[part 1 of 2: packages /VehicleProject to /E40_Platform_System_SystemPackage/Components]
AUTOSAR XML (schema 4-2-1)
standard types defined: uint8, uint16, UInt16, uint32, UInt32, sint32, boolean, Boolean, SInt32, UInt8, sint8, SInt8
package /VehicleProject
  ecu instance METER
package /E40_Platform_System_SystemPackage
  composition sw component type E40_Platform_System_SoftwareArchitecture
    component E40_Platform_SystemCmp: type=E40_Platform_System
  system E40_Platform_System_System
    system mapping MAPPING
      sw-impl-mappings:
        18 x swc to impl mapping:
          ImplementationMapping1: component-implementation=IMPL_CBacklightCdd, component=SoftwareArchitecture.E40_Platform_SystemCmp.CBacklightCdd
          ImplementationMapping2: component-implementation=IMPL_IoHwAb, component=SoftwareArchitecture.E40_Platform_SystemCmp.IoHwAb
          ImplementationMapping3: component-implementation=IMPL_CBattMdl, component=SoftwareArchitecture.E40_Platform_SystemCmp.CBattMdl
          ImplementationMapping4: component-implementation=IMPL_CCDD_EcuPowerM, component=SoftwareArchitecture.E40_Platform_SystemCmp.CCDD_EcuPowerM
          ImplementationMapping5: component-implementation=IMPL_CDisplayCdd, component=SoftwareArchitecture.E40_Platform_SystemCmp.CDisplayCdd
          ImplementationMapping6: component-implementation=IMPL_CMeetCdd, component=SoftwareArchitecture.E40_Platform_SystemCmp.CMeetCdd
          ImplementationMapping7: component-implementation=IMPL_MemAbstractMdl, component=SoftwareArchitecture.E40_Platform_SystemCmp.MemAbstractMdl
          ImplementationMapping8: component-implementation=IMPL_RtcCdd, component=SoftwareArchitecture.E40_Platform_SystemCmp.RtcCdd
          ImplementationMapping9: component-implementation=IMPL_CSleepManager, component=SoftwareArchitecture.E40_Platform_SystemCmp.CSleepManager
          ImplementationMapping10: component-implementation=IMPL_CSndCdd, component=SoftwareArchitecture.E40_Platform_SystemCmp.CSndCdd
          ImplementationMapping11: component-implementation=IMPL_DcmExt, component=SoftwareArchitecture.E40_Platform_SystemCmp.DcmExt
          ImplementationMapping12: component-implementation=IMPL_DemExt, component=SoftwareArchitecture.E40_Platform_SystemCmp.DemExt
          ImplementationMapping13: component-implementation=IMPL_DmnMgr, component=SoftwareArchitecture.E40_Platform_SystemCmp.DmnMgr
          ImplementationMapping14: component-implementation=IMPL_UclProxyCdd, component=SoftwareArchitecture.E40_Platform_SystemCmp.UclProxyCdd
          ImplementationMapping15: component-implementation=IMPL_EcuAppM, component=SoftwareArchitecture.E40_Platform_SystemCmp.EcuAppM
          ImplementationMapping16: component-implementation=IMPL_NvMExt, component=SoftwareArchitecture.E40_Platform_SystemCmp.NvMExt
          ImplementationMapping17: component-implementation=IMPL_EcuMExt, component=SoftwareArchitecture.E40_Platform_SystemCmp.EcuMExt
          ImplementationMapping18: component-implementation=IMPL_TmExt, component=SoftwareArchitecture.E40_Platform_SystemCmp.TmExt
      sw-mappings:
        swc to ecu mapping SwcToEcuMapping: ecu-instance=METER
    root-software-compositions:
      root sw composition prototype SoftwareArchitecture: software-composition=E40_Platform_System
package /E40_Platform_System_SystemPackage/Components
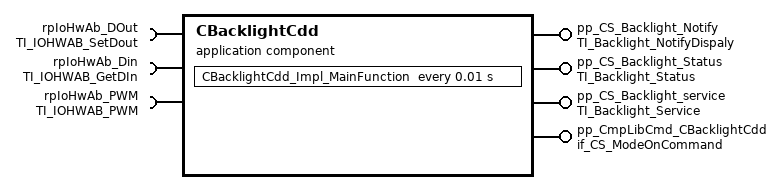
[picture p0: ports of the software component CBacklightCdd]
  application sw component type CBacklightCdd
    4 x provide port:
      pp_CS_Backlight_Notify: server-com-spec{operation=NotifyDisplayPowerState, queue-length=1}, provided-interface=TI_Backlight_NotifyDispaly
      pp_CS_Backlight_Status: server-com-spec{operation=TI_Backlight_Status/GetStatus, queue-length=1}, provided-interface=TI_Backlight_Status
      pp_CS_Backlight_service: provided-interface=TI_Backlight_Service
        provided-com-specs:
          operation=GetBrightnessValue, queue-length=1
          operation=GetThermalValue, queue-length=1
          operation=SetBrightnessValue, queue-length=1
      pp_CmpLibCmd_CBacklightCdd: server-com-spec{operation=Impl_OnCommand, queue-length=1}, provided-interface=if_CS_ModeOnCommand
    require port rpIoHwAb_DOut: required-interface=TI_IOHWAB_SetDout
    require port rpIoHwAb_Din: required-interface=TI_IOHWAB_GetDIn
    require port rpIoHwAb_PWM: required-interface=TI_IOHWAB_PWM
    behavior IB_CBacklightCdd
      operation invoked event OIE_pp_CS_Backlight_service_CBacklightCdd_GetBrightnessValueTrigByGetBrightnessValue: start-on-event=CBacklightCdd_GetBrightnessValue, operation=pp_CS_Backlight_service.GetBrightnessValue
      operation invoked event OIE_pp_CS_Backlight_Status_CBacklightCdd_GetStatusTrigByGetStatus: start-on-event=CBacklightCdd_GetStatus, operation=pp_CS_Backlight_Status.GetStatus
      operation invoked event OIE_pp_CS_Backlight_service_CBacklightCdd_GetThermalValueTrigByGetThermalValue: start-on-event=CBacklightCdd_GetThermalValue, operation=pp_CS_Backlight_service.GetThermalValue
      timing event TECBacklightCdd_Impl_MainFunction: start-on-event=CBacklightCdd_Impl_MainFunction, period=0.01
      operation invoked event OIE_pp_CmpLibCmd_CBacklightCdd_CBacklightCdd_Impl_OnCommandTrigByImpl_OnCommand: start-on-event=CBacklightCdd_Impl_OnCommand, operation=pp_CmpLibCmd_CBacklightCdd.Impl_OnCommand
      operation invoked event OIE_pp_CS_Backlight_Notify_CBacklightCdd_NotifyDisplayPowerStateTrigByNotifyDisplayPowerState: start-on-event=CBacklightCdd_NotifyDisplayPowerState, operation=pp_CS_Backlight_Notify.NotifyDisplayPowerState
      operation invoked event OIE_pp_CS_Backlight_service_CBacklightCdd_SetBrightnessValueTrigBySetBrightnessValue: start-on-event=CBacklightCdd_SetBrightnessValue, operation=pp_CS_Backlight_service.SetBrightnessValue
      port-api-options:
        enable-take-address=false, indirect-api=false, port=pp_CS_Backlight_Notify
        enable-take-address=false, indirect-api=false, port=pp_CS_Backlight_Status
        enable-take-address=false, indirect-api=false, port=pp_CS_Backlight_service
        enable-take-address=false, indirect-api=false, port=pp_CmpLibCmd_CBacklightCdd
        enable-take-address=false, indirect-api=false, port=CBacklightCdd/rpIoHwAb_DOut
        enable-take-address=false, indirect-api=false, port=CBacklightCdd/rpIoHwAb_Din
        enable-take-address=false, indirect-api=false, port=CBacklightCdd/rpIoHwAb_PWM
      7 x runnable, all with can-be-invoked-concurrently=true:
        CBacklightCdd_GetBrightnessValue
          9 x sync call, all with timeout=0.0:
            OA_rpIoHwAb_DOut_SetOutputGroup: operation=rpIoHwAb_DOut.SetOutputGroup
            OA_rpIoHwAb_DOut_SetOutputPin: operation=rpIoHwAb_DOut.SetOutputPin
            OA_rpIoHwAb_Din_GetAsyncRawInput: operation=rpIoHwAb_Din.GetAsyncRawInput
            OA_rpIoHwAb_Din_GetProcessedInput: operation=rpIoHwAb_Din.GetProcessedInput
            OA_rpIoHwAb_Din_GetSyncRawInput: operation=rpIoHwAb_Din.GetSyncRawInput
            OA_rpIoHwAb_Din_GetInputGroup: operation=rpIoHwAb_Din.GetInputGroup
            OA_rpIoHwAb_PWM_PwmSetDuty: operation=rpIoHwAb_PWM.PwmSetDuty
            OA_rpIoHwAb_PWM_PwmSetDutyAndPeriod: operation=rpIoHwAb_PWM.PwmSetDutyAndPeriod
            OA_rpIoHwAb_PWM_PwmSetIdeal: operation=rpIoHwAb_PWM.PwmSetIdeal
        CBacklightCdd_GetStatus
          9 x sync call, all with timeout=0.0:
            OA_rpIoHwAb_DOut_SetOutputGroup: operation=rpIoHwAb_DOut.SetOutputGroup
            OA_rpIoHwAb_DOut_SetOutputPin: operation=rpIoHwAb_DOut.SetOutputPin
            OA_rpIoHwAb_Din_GetAsyncRawInput: operation=rpIoHwAb_Din.GetAsyncRawInput
            OA_rpIoHwAb_Din_GetProcessedInput: operation=rpIoHwAb_Din.GetProcessedInput
            OA_rpIoHwAb_Din_GetSyncRawInput: operation=rpIoHwAb_Din.GetSyncRawInput
            OA_rpIoHwAb_Din_GetInputGroup: operation=rpIoHwAb_Din.GetInputGroup
            OA_rpIoHwAb_PWM_PwmSetDuty: operation=rpIoHwAb_PWM.PwmSetDuty
            OA_rpIoHwAb_PWM_PwmSetDutyAndPeriod: operation=rpIoHwAb_PWM.PwmSetDutyAndPeriod
            OA_rpIoHwAb_PWM_PwmSetIdeal: operation=rpIoHwAb_PWM.PwmSetIdeal
        CBacklightCdd_GetThermalValue
          9 x sync call, all with timeout=0.0:
            OA_rpIoHwAb_DOut_SetOutputGroup: operation=rpIoHwAb_DOut.SetOutputGroup
            OA_rpIoHwAb_DOut_SetOutputPin: operation=rpIoHwAb_DOut.SetOutputPin
            OA_rpIoHwAb_Din_GetAsyncRawInput: operation=rpIoHwAb_Din.GetAsyncRawInput
            OA_rpIoHwAb_Din_GetProcessedInput: operation=rpIoHwAb_Din.GetProcessedInput
            OA_rpIoHwAb_Din_GetSyncRawInput: operation=rpIoHwAb_Din.GetSyncRawInput
            OA_rpIoHwAb_Din_GetInputGroup: operation=rpIoHwAb_Din.GetInputGroup
            OA_rpIoHwAb_PWM_PwmSetDuty: operation=rpIoHwAb_PWM.PwmSetDuty
            OA_rpIoHwAb_PWM_PwmSetDutyAndPeriod: operation=rpIoHwAb_PWM.PwmSetDutyAndPeriod
            OA_rpIoHwAb_PWM_PwmSetIdeal: operation=rpIoHwAb_PWM.PwmSetIdeal
        CBacklightCdd_Impl_MainFunction
          9 x sync call, all with timeout=0.0:
            OA_rpIoHwAb_DOut_SetOutputGroup: operation=rpIoHwAb_DOut.SetOutputGroup
            OA_rpIoHwAb_DOut_SetOutputPin: operation=rpIoHwAb_DOut.SetOutputPin
            OA_rpIoHwAb_Din_GetAsyncRawInput: operation=rpIoHwAb_Din.GetAsyncRawInput
            OA_rpIoHwAb_Din_GetProcessedInput: operation=rpIoHwAb_Din.GetProcessedInput
            OA_rpIoHwAb_Din_GetSyncRawInput: operation=rpIoHwAb_Din.GetSyncRawInput
            OA_rpIoHwAb_Din_GetInputGroup: operation=rpIoHwAb_Din.GetInputGroup
            OA_rpIoHwAb_PWM_PwmSetDuty: operation=rpIoHwAb_PWM.PwmSetDuty
            OA_rpIoHwAb_PWM_PwmSetDutyAndPeriod: operation=rpIoHwAb_PWM.PwmSetDutyAndPeriod
            OA_rpIoHwAb_PWM_PwmSetIdeal: operation=rpIoHwAb_PWM.PwmSetIdeal
        CBacklightCdd_Impl_OnCommand
          9 x sync call, all with timeout=0.0:
            OA_rpIoHwAb_DOut_SetOutputGroup: operation=rpIoHwAb_DOut.SetOutputGroup
            OA_rpIoHwAb_DOut_SetOutputPin: operation=rpIoHwAb_DOut.SetOutputPin
            OA_rpIoHwAb_Din_GetAsyncRawInput: operation=rpIoHwAb_Din.GetAsyncRawInput
            OA_rpIoHwAb_Din_GetProcessedInput: operation=rpIoHwAb_Din.GetProcessedInput
            OA_rpIoHwAb_Din_GetSyncRawInput: operation=rpIoHwAb_Din.GetSyncRawInput
            OA_rpIoHwAb_Din_GetInputGroup: operation=rpIoHwAb_Din.GetInputGroup
            OA_rpIoHwAb_PWM_PwmSetDuty: operation=rpIoHwAb_PWM.PwmSetDuty
            OA_rpIoHwAb_PWM_PwmSetDutyAndPeriod: operation=rpIoHwAb_PWM.PwmSetDutyAndPeriod
            OA_rpIoHwAb_PWM_PwmSetIdeal: operation=rpIoHwAb_PWM.PwmSetIdeal
        CBacklightCdd_NotifyDisplayPowerState
          9 x sync call, all with timeout=0.0:
            OA_rpIoHwAb_DOut_SetOutputGroup: operation=rpIoHwAb_DOut.SetOutputGroup
            OA_rpIoHwAb_DOut_SetOutputPin: operation=rpIoHwAb_DOut.SetOutputPin
            OA_rpIoHwAb_Din_GetAsyncRawInput: operation=rpIoHwAb_Din.GetAsyncRawInput
            OA_rpIoHwAb_Din_GetProcessedInput: operation=rpIoHwAb_Din.GetProcessedInput
            OA_rpIoHwAb_Din_GetSyncRawInput: operation=rpIoHwAb_Din.GetSyncRawInput
            OA_rpIoHwAb_Din_GetInputGroup: operation=rpIoHwAb_Din.GetInputGroup
            OA_rpIoHwAb_PWM_PwmSetDuty: operation=rpIoHwAb_PWM.PwmSetDuty
            OA_rpIoHwAb_PWM_PwmSetDutyAndPeriod: operation=rpIoHwAb_PWM.PwmSetDutyAndPeriod
            OA_rpIoHwAb_PWM_PwmSetIdeal: operation=rpIoHwAb_PWM.PwmSetIdeal
        CBacklightCdd_SetBrightnessValue
          9 x sync call, all with timeout=0.0:
            OA_rpIoHwAb_DOut_SetOutputGroup: operation=rpIoHwAb_DOut.SetOutputGroup
            OA_rpIoHwAb_DOut_SetOutputPin: operation=rpIoHwAb_DOut.SetOutputPin
            OA_rpIoHwAb_Din_GetAsyncRawInput: operation=rpIoHwAb_Din.GetAsyncRawInput
            OA_rpIoHwAb_Din_GetProcessedInput: operation=rpIoHwAb_Din.GetProcessedInput
            OA_rpIoHwAb_Din_GetSyncRawInput: operation=rpIoHwAb_Din.GetSyncRawInput
            OA_rpIoHwAb_Din_GetInputGroup: operation=rpIoHwAb_Din.GetInputGroup
            OA_rpIoHwAb_PWM_PwmSetDuty: operation=rpIoHwAb_PWM.PwmSetDuty
            OA_rpIoHwAb_PWM_PwmSetDutyAndPeriod: operation=rpIoHwAb_PWM.PwmSetDutyAndPeriod
            OA_rpIoHwAb_PWM_PwmSetIdeal: operation=rpIoHwAb_PWM.PwmSetIdeal
  swc implementation IMPL_CBacklightCdd: programming-language=C, behavior=IB_CBacklightCdd
    code-descriptors:
      code CodeDescriptor
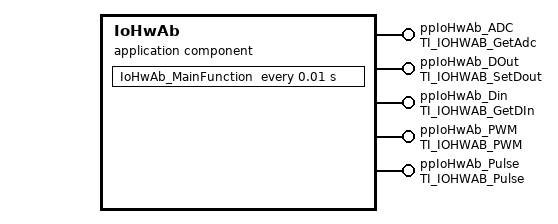
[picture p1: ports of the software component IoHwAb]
  application sw component type IoHwAb
    5 x provide port:
      ppIoHwAb_ADC: provided-interface=TI_IOHWAB_GetAdc
        provided-com-specs:
          operation=GetAsyncRawAdc, queue-length=1
          operation=GetProcessedAdc, queue-length=1
          operation=GetSyncRawAdc, queue-length=1
      ppIoHwAb_DOut: provided-com-specs=[{operation=SetOutputGroup, queue-length=1}, {operation=SetOutputPin, queue-length=1}], provided-interface=TI_IOHWAB_SetDout
      ppIoHwAb_Din: provided-interface=TI_IOHWAB_GetDIn
        provided-com-specs:
          operation=GetAsyncRawInput, queue-length=1
          operation=GetInputGroup, queue-length=1
          operation=GetProcessedInput, queue-length=1
          operation=GetSyncRawInput, queue-length=1
      ppIoHwAb_PWM: provided-interface=TI_IOHWAB_PWM
        provided-com-specs:
          operation=PwmSetDuty, queue-length=1
          operation=PwmSetDutyAndPeriod, queue-length=1
          operation=PwmSetIdeal, queue-length=1
      ppIoHwAb_Pulse: provided-interface=TI_IOHWAB_Pulse
        provided-com-specs:
          operation=GetCurrentSignalStatus_PulseInput, queue-length=1
          operation=GetCurrentSpeed_PulseInput, queue-length=1
          operation=GetRollingCount_PulseInput, queue-length=1
          operation=ResetRollingCount_PulseInput, queue-length=1
          operation=Start_Signal_Measurement_PulseInput, queue-length=1
          operation=Stop_Signal_Measurement_PulseInput, queue-length=1
          operation=Update_CalibParam_PulseInput, queue-length=1
    behavior IB_IoHwAb
      10 x operation invoked event:
        OIE_ppIoHwAb_ADC_IoHwAb_GetAsyncRawAdcTrigByGetAsyncRawAdc: start-on-event=IoHwAb_GetAsyncRawAdc, operation=ppIoHwAb_ADC.GetAsyncRawAdc
        OIE_ppIoHwAb_Din_IoHwAb_GetAsyncRawInputTrigByGetAsyncRawInput: start-on-event=IoHwAb_GetAsyncRawInput, operation=ppIoHwAb_Din.GetAsyncRawInput
        OIE_ppIoHwAb_Pulse_IoHwAb_GetCurrentSignalStatus_PulseInputTrigByGetCurrentSignalStatus_PulseInput: start-on-event=IoHwAb_GetCurrentSignalStatus_PulseInput, operation=ppIoHwAb_Pulse.GetCurrentSignalStatus_PulseInput
        OIE_ppIoHwAb_Pulse_IoHwAb_GetCurrentSpeed_PulseInputTrigByGetCurrentSpeed_PulseInput: start-on-event=IoHwAb_GetCurrentSpeed_PulseInput, operation=ppIoHwAb_Pulse.GetCurrentSpeed_PulseInput
        OIE_ppIoHwAb_Din_IoHwAb_GetInputGroupTrigByGetInputGroup: start-on-event=IoHwAb_GetInputGroup, operation=ppIoHwAb_Din.GetInputGroup
        OIE_ppIoHwAb_ADC_IoHwAb_GetProcessedAdcTrigByGetProcessedAdc: start-on-event=IoHwAb_GetProcessedAdc, operation=ppIoHwAb_ADC.GetProcessedAdc
        OIE_ppIoHwAb_Din_IoHwAb_GetProcessedInputTrigByGetProcessedInput: start-on-event=IoHwAb_GetProcessedInput, operation=ppIoHwAb_Din.GetProcessedInput
        OIE_ppIoHwAb_Pulse_IoHwAb_GetRollingCount_PulseInputTrigByGetRollingCount_PulseInput: start-on-event=IoHwAb_GetRollingCount_PulseInput, operation=ppIoHwAb_Pulse.GetRollingCount_PulseInput
        OIE_ppIoHwAb_ADC_IoHwAb_GetSyncRawAdcTrigByGetSyncRawAdc: start-on-event=IoHwAb_GetSyncRawAdc, operation=ppIoHwAb_ADC.GetSyncRawAdc
        OIE_ppIoHwAb_Din_IoHwAb_GetSyncRawInputTrigByGetSyncRawInput: start-on-event=IoHwAb_GetSyncRawInput, operation=ppIoHwAb_Din.GetSyncRawInput
      timing event TEIoHwAb_MainFunction: start-on-event=IoHwAb_MainFunction, period=0.01
      9 x operation invoked event:
        OIE_ppIoHwAb_PWM_IoHwAb_PwmSetDutyTrigByPwmSetDuty: start-on-event=IoHwAb_PwmSetDuty, operation=ppIoHwAb_PWM.PwmSetDuty
        OIE_ppIoHwAb_PWM_IoHwAb_PwmSetDutyAndPeriodTrigByPwmSetDutyAndPeriod: start-on-event=IoHwAb_PwmSetDutyAndPeriod, operation=ppIoHwAb_PWM.PwmSetDutyAndPeriod
        OIE_ppIoHwAb_PWM_IoHwAb_PwmSetIdealTrigByPwmSetIdeal: start-on-event=IoHwAb_PwmSetIdeal, operation=ppIoHwAb_PWM.PwmSetIdeal
        OIE_ppIoHwAb_Pulse_IoHwAb_ResetRollingCount_PulseInputTrigByResetRollingCount_PulseInput: start-on-event=IoHwAb_ResetRollingCount_PulseInput, operation=ppIoHwAb_Pulse.ResetRollingCount_PulseInput
        OIE_ppIoHwAb_DOut_IoHwAb_SetOutputGroupTrigBySetOutputGroup: start-on-event=IoHwAb_SetOutputGroup, operation=ppIoHwAb_DOut.SetOutputGroup
        OIE_ppIoHwAb_DOut_IoHwAb_SetOutputPinTrigBySetOutputPin: start-on-event=IoHwAb_SetOutputPin, operation=ppIoHwAb_DOut.SetOutputPin
        OIE_ppIoHwAb_Pulse_IoHwAb_Start_Signal_Measurement_PulseInputTrigByStart_Signal_Measurement_PulseInput: start-on-event=IoHwAb_Start_Signal_Measurement_PulseInput, operation=ppIoHwAb_Pulse.Start_Signal_Measurement_PulseInput
        OIE_ppIoHwAb_Pulse_IoHwAb_Stop_Signal_Measurement_PulseInputTrigByStop_Signal_Measurement_PulseInput: start-on-event=IoHwAb_Stop_Signal_Measurement_PulseInput, operation=ppIoHwAb_Pulse.Stop_Signal_Measurement_PulseInput
        OIE_ppIoHwAb_Pulse_IoHwAb_Update_CalibParam_PulseInputTrigByUpdate_CalibParam_PulseInput: start-on-event=IoHwAb_Update_CalibParam_PulseInput, operation=ppIoHwAb_Pulse.Update_CalibParam_PulseInput
      port-api-options:
        enable-take-address=false, indirect-api=false, port=ppIoHwAb_ADC
        enable-take-address=false, indirect-api=false, port=ppIoHwAb_DOut
        enable-take-address=false, indirect-api=false, port=ppIoHwAb_Din
        enable-take-address=false, indirect-api=false, port=ppIoHwAb_PWM
        enable-take-address=false, indirect-api=false, port=ppIoHwAb_Pulse
      20 x runnable, all with can-be-invoked-concurrently=true:
        IoHwAb_GetAsyncRawAdc
        IoHwAb_GetAsyncRawInput
        IoHwAb_GetCurrentSignalStatus_PulseInput
        IoHwAb_GetCurrentSpeed_PulseInput
        IoHwAb_GetInputGroup
        IoHwAb_GetProcessedAdc
        IoHwAb_GetProcessedInput
        IoHwAb_GetRollingCount_PulseInput
        IoHwAb_GetSyncRawAdc
        IoHwAb_GetSyncRawInput
        IoHwAb_MainFunction
        IoHwAb_PwmSetDuty
        IoHwAb_PwmSetDutyAndPeriod
        IoHwAb_PwmSetIdeal
        IoHwAb_ResetRollingCount_PulseInput
        IoHwAb_SetOutputGroup
        IoHwAb_SetOutputPin
        IoHwAb_Start_Signal_Measurement_PulseInput
        IoHwAb_Stop_Signal_Measurement_PulseInput
        IoHwAb_Update_CalibParam_PulseInput
  swc implementation IMPL_IoHwAb: programming-language=C, behavior=IB_IoHwAb
    code-descriptors:
      code CodeDescriptor
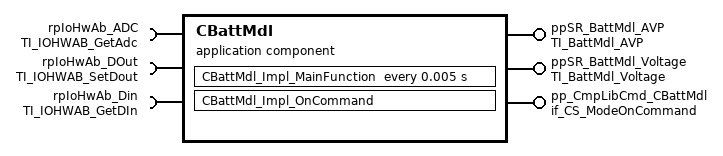
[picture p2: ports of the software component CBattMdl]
  application sw component type CBattMdl
    provide port ppSR_BattMdl_AVP: provided-interface=TI_BattMdl_AVP
      provided-com-specs:
        data-element=HVP0Flag, uses-end-to-end-protection=0, init-value=constant-reference=CBattMdlHVP0FlagValue0
        data-element=HVSD{0..4}Flag, uses-end-to-end-protection=0, init-value=constant-reference=CBattMdlHVSD{0..4}FlagValue0
        data-element=LVP0Flag, uses-end-to-end-protection=0, init-value=constant-reference=CBattMdlLVP0FlagValue0
        data-element=LVP1Flag, uses-end-to-end-protection=0, init-value=constant-reference=CBattMdlLVP1FlagValue0
        data-element=LVSD{0..4}Flag, uses-end-to-end-protection=0, init-value=constant-reference=CBattMdlLVSD{0..4}FlagValue0
        data-element=SVPFlag, uses-end-to-end-protection=0, init-value=constant-reference=CBattMdlSVPFlagValue0
    provide port ppSR_BattMdl_Voltage: nonqueued-sender-com-spec{data-element=OverVoltageInterruptFlag, uses-end-to-end-protection=0, init-value=constant-reference=CBattMdlOverVoltageInterruptFlagValue0}, provided-interface=TI_BattMdl_Voltage
    provide port pp_CmpLibCmd_CBattMdl: server-com-spec{operation=Impl_OnCommand, queue-length=1}, provided-interface=if_CS_ModeOnCommand
    require port rpIoHwAb_ADC: required-interface=TI_IOHWAB_GetAdc
    require port rpIoHwAb_DOut: required-interface=TI_IOHWAB_SetDout
    require port rpIoHwAb_Din: required-interface=TI_IOHWAB_GetDIn
    behavior IB_CBattMdl
      timing event TECBattMdl_Impl_MainFunction: start-on-event=CBattMdl_Impl_MainFunction, period=0.005
      operation invoked event OIE_pp_CmpLibCmd_CBattMdl_CBattMdl_Impl_OnCommandTrigByImpl_OnCommand: start-on-event=CBattMdl_Impl_OnCommand, operation=pp_CmpLibCmd_CBattMdl.Impl_OnCommand
      port-api-options:
        enable-take-address=false, indirect-api=false, port=ppSR_BattMdl_AVP
        enable-take-address=false, indirect-api=false, port=ppSR_BattMdl_Voltage
        enable-take-address=false, indirect-api=false, port=pp_CmpLibCmd_CBattMdl
        enable-take-address=false, indirect-api=false, port=CBattMdl/rpIoHwAb_ADC
        enable-take-address=false, indirect-api=false, port=CBattMdl/rpIoHwAb_DOut
        enable-take-address=false, indirect-api=false, port=CBattMdl/rpIoHwAb_Din
      runnable CBattMdl_Impl_MainFunction: can-be-invoked-concurrently=true
        data-send-points:
          15 x access:
            DWA_ppSR_BattMdl_AVP_HVP0Flag: accessed-variable=ppSR_BattMdl_AVP.HVP0Flag
            DWA_ppSR_BattMdl_AVP_HVSD{0..4}Flag: accessed-variable=ppSR_BattMdl_AVP.HVSD{0..4}Flag
            DWA_ppSR_BattMdl_AVP_LVP0Flag: accessed-variable=ppSR_BattMdl_AVP.LVP0Flag
            DWA_ppSR_BattMdl_AVP_LVP1Flag: accessed-variable=ppSR_BattMdl_AVP.LVP1Flag
            DWA_ppSR_BattMdl_AVP_LVSD{0..4}Flag: accessed-variable=ppSR_BattMdl_AVP.LVSD{0..4}Flag
            DWA_ppSR_BattMdl_AVP_SVPFlag: accessed-variable=ppSR_BattMdl_AVP.SVPFlag
            DWA_ppSR_BattMdl_Voltage_OverVoltageInterruptFlag: accessed-variable=ppSR_BattMdl_Voltage.OverVoltageInterruptFlag
        9 x sync call, all with timeout=0.0:
          OA_rpIoHwAb_ADC_GetAsyncRawAdc: operation=rpIoHwAb_ADC.GetAsyncRawAdc
          OA_rpIoHwAb_ADC_GetSyncRawAdc: operation=rpIoHwAb_ADC.GetSyncRawAdc
          OA_rpIoHwAb_ADC_GetProcessedAdc: operation=rpIoHwAb_ADC.GetProcessedAdc
          OA_rpIoHwAb_DOut_SetOutputGroup: operation=rpIoHwAb_DOut.SetOutputGroup
          OA_rpIoHwAb_DOut_SetOutputPin: operation=rpIoHwAb_DOut.SetOutputPin
          OA_rpIoHwAb_Din_GetAsyncRawInput: operation=rpIoHwAb_Din.GetAsyncRawInput
          OA_rpIoHwAb_Din_GetProcessedInput: operation=rpIoHwAb_Din.GetProcessedInput
          OA_rpIoHwAb_Din_GetSyncRawInput: operation=rpIoHwAb_Din.GetSyncRawInput
          OA_rpIoHwAb_Din_GetInputGroup: operation=rpIoHwAb_Din.GetInputGroup
      runnable CBattMdl_Impl_OnCommand: can-be-invoked-concurrently=true
        data-send-points:
          15 x access:
            DWA_ppSR_BattMdl_AVP_HVP0Flag: accessed-variable=ppSR_BattMdl_AVP.HVP0Flag
            DWA_ppSR_BattMdl_AVP_HVSD{0..4}Flag: accessed-variable=ppSR_BattMdl_AVP.HVSD{0..4}Flag
            DWA_ppSR_BattMdl_AVP_LVP0Flag: accessed-variable=ppSR_BattMdl_AVP.LVP0Flag
            DWA_ppSR_BattMdl_AVP_LVP1Flag: accessed-variable=ppSR_BattMdl_AVP.LVP1Flag
            DWA_ppSR_BattMdl_AVP_LVSD{0..4}Flag: accessed-variable=ppSR_BattMdl_AVP.LVSD{0..4}Flag
            DWA_ppSR_BattMdl_AVP_SVPFlag: accessed-variable=ppSR_BattMdl_AVP.SVPFlag
            DWA_ppSR_BattMdl_Voltage_OverVoltageInterruptFlag: accessed-variable=ppSR_BattMdl_Voltage.OverVoltageInterruptFlag
        9 x sync call, all with timeout=0.0:
          OA_rpIoHwAb_ADC_GetAsyncRawAdc: operation=rpIoHwAb_ADC.GetAsyncRawAdc
          OA_rpIoHwAb_ADC_GetSyncRawAdc: operation=rpIoHwAb_ADC.GetSyncRawAdc
          OA_rpIoHwAb_ADC_GetProcessedAdc: operation=rpIoHwAb_ADC.GetProcessedAdc
          OA_rpIoHwAb_DOut_SetOutputGroup: operation=rpIoHwAb_DOut.SetOutputGroup
          OA_rpIoHwAb_DOut_SetOutputPin: operation=rpIoHwAb_DOut.SetOutputPin
          OA_rpIoHwAb_Din_GetAsyncRawInput: operation=rpIoHwAb_Din.GetAsyncRawInput
          OA_rpIoHwAb_Din_GetProcessedInput: operation=rpIoHwAb_Din.GetProcessedInput
          OA_rpIoHwAb_Din_GetSyncRawInput: operation=rpIoHwAb_Din.GetSyncRawInput
          OA_rpIoHwAb_Din_GetInputGroup: operation=rpIoHwAb_Din.GetInputGroup
  15 x constant specification:
    CBattMdlHVP0FlagValue0: value-spec=CBattMdlHVP0FlagValue0:false
    CBattMdlHVSD{0..4}FlagValue0: value-spec=CBattMdlHVSD{0..4}FlagValue0:false
    CBattMdlLVP0FlagValue0: value-spec=CBattMdlLVP0FlagValue0:false
    CBattMdlLVP1FlagValue0: value-spec=CBattMdlLVP1FlagValue0:false
    CBattMdlLVSD{0..4}FlagValue0: value-spec=CBattMdlLVSD{0..4}FlagValue0:false
    CBattMdlSVPFlagValue0: value-spec=CBattMdlSVPFlagValue0:false
    CBattMdlOverVoltageInterruptFlagValue0: value-spec=CBattMdlOverVoltageInterruptFlagValue0:false
  swc implementation IMPL_CBattMdl: programming-language=C, behavior=IB_CBattMdl
    code-descriptors:
      code CodeDescriptor
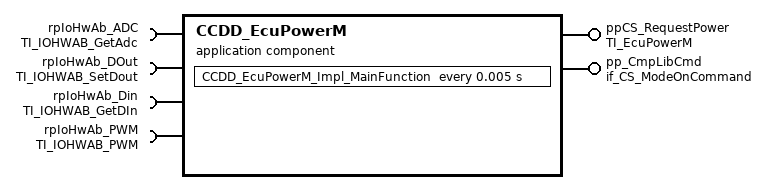
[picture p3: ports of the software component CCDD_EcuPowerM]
  application sw component type CCDD_EcuPowerM
    provide port ppCS_RequestPower: provided-interface=TI_EcuPowerM
      provided-com-specs:
        operation=EcuPowerM_GetDeviceStatus, queue-length=1
        operation=EcuPowerM_RequestPower, queue-length=1
    provide port pp_CmpLibCmd: server-com-spec{operation=Impl_OnCommand, queue-length=1}, provided-interface=if_CS_ModeOnCommand
    4 x require port:
      rpIoHwAb_ADC: required-interface=TI_IOHWAB_GetAdc
      rpIoHwAb_DOut: required-interface=TI_IOHWAB_SetDout
      rpIoHwAb_Din: required-interface=TI_IOHWAB_GetDIn
      rpIoHwAb_PWM: required-interface=TI_IOHWAB_PWM
    behavior IB_CCDD_EcuPowerM
      timing event TECCDD_EcuPowerM_Impl_MainFunction: start-on-event=CCDD_EcuPowerM_Impl_MainFunction, period=0.005
      operation invoked event OIE_ppCS_RequestPower_EcuPowerM_GetDeviceStatusTrigByEcuPowerM_GetDeviceStatus: start-on-event=EcuPowerM_GetDeviceStatus, operation=ppCS_RequestPower.EcuPowerM_GetDeviceStatus
      operation invoked event OIE_ppCS_RequestPower_EcuPowerM_RequestPowerTrigByEcuPowerM_RequestPower: start-on-event=EcuPowerM_RequestPower, operation=ppCS_RequestPower.EcuPowerM_RequestPower
      operation invoked event OIE_pp_CmpLibCmd_CCDD_EcuPowerM_Impl_OnCommandTrigByImpl_OnCommand: start-on-event=CCDD_EcuPowerM_Impl_OnCommand, operation=pp_CmpLibCmd.Impl_OnCommand
      port-api-options:
        enable-take-address=false, indirect-api=false, port=ppCS_RequestPower
        enable-take-address=false, indirect-api=false, port=CCDD_EcuPowerM/pp_CmpLibCmd
        enable-take-address=false, indirect-api=false, port=CCDD_EcuPowerM/rpIoHwAb_ADC
        enable-take-address=false, indirect-api=false, port=CCDD_EcuPowerM/rpIoHwAb_DOut
        enable-take-address=false, indirect-api=false, port=CCDD_EcuPowerM/rpIoHwAb_Din
        enable-take-address=false, indirect-api=false, port=CCDD_EcuPowerM/rpIoHwAb_PWM
      4 x runnable, all with can-be-invoked-concurrently=true:
        CCDD_EcuPowerM_Impl_MainFunction
          12 x sync call, all with timeout=0.0:
            OA_rpIoHwAb_ADC_GetAsyncRawAdc: operation=rpIoHwAb_ADC.GetAsyncRawAdc
            OA_rpIoHwAb_ADC_GetSyncRawAdc: operation=rpIoHwAb_ADC.GetSyncRawAdc
            OA_rpIoHwAb_ADC_GetProcessedAdc: operation=rpIoHwAb_ADC.GetProcessedAdc
            OA_rpIoHwAb_DOut_SetOutputGroup: operation=rpIoHwAb_DOut.SetOutputGroup
            OA_rpIoHwAb_DOut_SetOutputPin: operation=rpIoHwAb_DOut.SetOutputPin
            OA_rpIoHwAb_Din_GetAsyncRawInput: operation=rpIoHwAb_Din.GetAsyncRawInput
            OA_rpIoHwAb_Din_GetProcessedInput: operation=rpIoHwAb_Din.GetProcessedInput
            OA_rpIoHwAb_Din_GetSyncRawInput: operation=rpIoHwAb_Din.GetSyncRawInput
            OA_rpIoHwAb_Din_GetInputGroup: operation=rpIoHwAb_Din.GetInputGroup
            OA_rpIoHwAb_PWM_PwmSetDuty: operation=rpIoHwAb_PWM.PwmSetDuty
            OA_rpIoHwAb_PWM_PwmSetDutyAndPeriod: operation=rpIoHwAb_PWM.PwmSetDutyAndPeriod
            OA_rpIoHwAb_PWM_PwmSetIdeal: operation=rpIoHwAb_PWM.PwmSetIdeal
        EcuPowerM_GetDeviceStatus
          12 x sync call, all with timeout=0.0:
            OA_rpIoHwAb_ADC_GetAsyncRawAdc: operation=rpIoHwAb_ADC.GetAsyncRawAdc
            OA_rpIoHwAb_ADC_GetSyncRawAdc: operation=rpIoHwAb_ADC.GetSyncRawAdc
            OA_rpIoHwAb_ADC_GetProcessedAdc: operation=rpIoHwAb_ADC.GetProcessedAdc
            OA_rpIoHwAb_DOut_SetOutputGroup: operation=rpIoHwAb_DOut.SetOutputGroup
            OA_rpIoHwAb_DOut_SetOutputPin: operation=rpIoHwAb_DOut.SetOutputPin
            OA_rpIoHwAb_Din_GetAsyncRawInput: operation=rpIoHwAb_Din.GetAsyncRawInput
            OA_rpIoHwAb_Din_GetProcessedInput: operation=rpIoHwAb_Din.GetProcessedInput
            OA_rpIoHwAb_Din_GetSyncRawInput: operation=rpIoHwAb_Din.GetSyncRawInput
            OA_rpIoHwAb_Din_GetInputGroup: operation=rpIoHwAb_Din.GetInputGroup
            OA_rpIoHwAb_PWM_PwmSetDuty: operation=rpIoHwAb_PWM.PwmSetDuty
            OA_rpIoHwAb_PWM_PwmSetDutyAndPeriod: operation=rpIoHwAb_PWM.PwmSetDutyAndPeriod
            OA_rpIoHwAb_PWM_PwmSetIdeal: operation=rpIoHwAb_PWM.PwmSetIdeal
        EcuPowerM_RequestPower
          12 x sync call, all with timeout=0.0:
            OA_rpIoHwAb_ADC_GetAsyncRawAdc: operation=rpIoHwAb_ADC.GetAsyncRawAdc
            OA_rpIoHwAb_ADC_GetSyncRawAdc: operation=rpIoHwAb_ADC.GetSyncRawAdc
            OA_rpIoHwAb_ADC_GetProcessedAdc: operation=rpIoHwAb_ADC.GetProcessedAdc
            OA_rpIoHwAb_DOut_SetOutputGroup: operation=rpIoHwAb_DOut.SetOutputGroup
            OA_rpIoHwAb_DOut_SetOutputPin: operation=rpIoHwAb_DOut.SetOutputPin
            OA_rpIoHwAb_Din_GetAsyncRawInput: operation=rpIoHwAb_Din.GetAsyncRawInput
            OA_rpIoHwAb_Din_GetProcessedInput: operation=rpIoHwAb_Din.GetProcessedInput
            OA_rpIoHwAb_Din_GetSyncRawInput: operation=rpIoHwAb_Din.GetSyncRawInput
            OA_rpIoHwAb_Din_GetInputGroup: operation=rpIoHwAb_Din.GetInputGroup
            OA_rpIoHwAb_PWM_PwmSetDuty: operation=rpIoHwAb_PWM.PwmSetDuty
            OA_rpIoHwAb_PWM_PwmSetDutyAndPeriod: operation=rpIoHwAb_PWM.PwmSetDutyAndPeriod
            OA_rpIoHwAb_PWM_PwmSetIdeal: operation=rpIoHwAb_PWM.PwmSetIdeal
        CCDD_EcuPowerM_Impl_OnCommand
  swc implementation IMPL_CCDD_EcuPowerM: programming-language=C, behavior=IB_CCDD_EcuPowerM
    code-descriptors:
      code CodeDescriptor
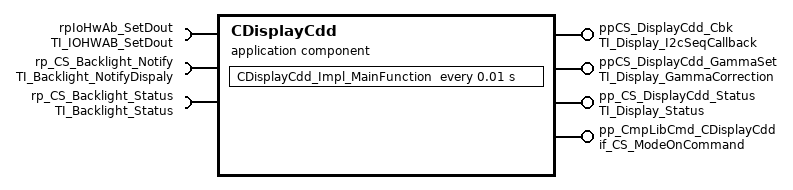
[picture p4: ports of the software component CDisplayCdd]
  application sw component type CDisplayCdd
    4 x provide port:
      ppCS_DisplayCdd_Cbk: server-com-spec{operation=I2cSeqEndCallback, queue-length=1}, provided-interface=TI_Display_I2cSeqCallback
      ppCS_DisplayCdd_GammaSet: provided-com-specs=[{operation=GetGammaCorrectionStatus, queue-length=1}, {operation=SetGammaCorrection, queue-length=1}], provided-interface=TI_Display_GammaCorrection
      pp_CS_DisplayCdd_Status: provided-com-specs=[{operation=TI_Display_Status/GetStatus, queue-length=1}, {operation=SetState, queue-length=1}], provided-interface=TI_Display_Status
      pp_CmpLibCmd_CDisplayCdd: server-com-spec{operation=Impl_OnCommand, queue-length=1}, provided-interface=if_CS_ModeOnCommand
    require port rpIoHwAb_SetDout: required-interface=TI_IOHWAB_SetDout
    require port rp_CS_Backlight_Notify: required-interface=TI_Backlight_NotifyDispaly
    require port rp_CS_Backlight_Status: required-interface=TI_Backlight_Status
    behavior IB_CDisplayCdd
      operation invoked event OIE_ppCS_DisplayCdd_GammaSet_CDisplayCdd_GetGammaCorrectionStatusTrigByGetGammaCorrectionStatus: start-on-event=CDisplayCdd_GetGammaCorrectionStatus, operation=ppCS_DisplayCdd_GammaSet.GetGammaCorrectionStatus
      operation invoked event OIE_pp_CS_DisplayCdd_Status_CDisplayCdd_GetStatusTrigByGetStatus: start-on-event=CDisplayCdd_GetStatus, operation=pp_CS_DisplayCdd_Status.GetStatus
      operation invoked event OIE_ppCS_DisplayCdd_Cbk_CDisplayCdd_I2cSeqEndCallbackTrigByI2cSeqEndCallback: start-on-event=CDisplayCdd_I2cSeqEndCallback, operation=ppCS_DisplayCdd_Cbk.I2cSeqEndCallback
      timing event TECDisplayCdd_Impl_MainFunction: start-on-event=CDisplayCdd_Impl_MainFunction, period=0.01
      operation invoked event OIE_pp_CmpLibCmd_CDisplayCdd_CDisplayCdd_Impl_OnCommandTrigByImpl_OnCommand: start-on-event=CDisplayCdd_Impl_OnCommand, operation=pp_CmpLibCmd_CDisplayCdd.Impl_OnCommand
      operation invoked event OIE_ppCS_DisplayCdd_GammaSet_CDisplayCdd_SetGammaCorrectionTrigBySetGammaCorrection: start-on-event=CDisplayCdd_SetGammaCorrection, operation=ppCS_DisplayCdd_GammaSet.SetGammaCorrection
      operation invoked event OIE_pp_CS_DisplayCdd_Status_CDisplayCdd_SetStateTrigBySetState: start-on-event=CDisplayCdd_SetState, operation=pp_CS_DisplayCdd_Status.SetState
      port-api-options:
        enable-take-address=false, indirect-api=false, port=ppCS_DisplayCdd_Cbk
        enable-take-address=false, indirect-api=false, port=ppCS_DisplayCdd_GammaSet
        enable-take-address=false, indirect-api=false, port=pp_CS_DisplayCdd_Status
        enable-take-address=false, indirect-api=false, port=pp_CmpLibCmd_CDisplayCdd
        enable-take-address=false, indirect-api=false, port=rpIoHwAb_SetDout
        enable-take-address=false, indirect-api=false, port=rp_CS_Backlight_Notify
        enable-take-address=false, indirect-api=false, port=rp_CS_Backlight_Status
      7 x runnable, all with can-be-invoked-concurrently=true:
        CDisplayCdd_GetGammaCorrectionStatus
        CDisplayCdd_GetStatus
          4 x sync call, all with timeout=0.0:
            OA_rpIoHwAb_SetDout_SetOutputGroup: operation=rpIoHwAb_SetDout.SetOutputGroup
            OA_rpIoHwAb_SetDout_SetOutputPin: operation=rpIoHwAb_SetDout.SetOutputPin
            OA_rp_CS_Backlight_Notify_NotifyDisplayPowerState: operation=rp_CS_Backlight_Notify.NotifyDisplayPowerState
            OA_rp_CS_Backlight_Status_GetStatus: operation=rp_CS_Backlight_Status.GetStatus
        CDisplayCdd_I2cSeqEndCallback
        CDisplayCdd_Impl_MainFunction
          4 x sync call, all with timeout=0.0:
            OA_rpIoHwAb_SetDout_SetOutputGroup: operation=rpIoHwAb_SetDout.SetOutputGroup
            OA_rpIoHwAb_SetDout_SetOutputPin: operation=rpIoHwAb_SetDout.SetOutputPin
            OA_rp_CS_Backlight_Notify_NotifyDisplayPowerState: operation=rp_CS_Backlight_Notify.NotifyDisplayPowerState
            OA_rp_CS_Backlight_Status_GetStatus: operation=rp_CS_Backlight_Status.GetStatus
        CDisplayCdd_Impl_OnCommand
          4 x sync call, all with timeout=0.0:
            OA_rpIoHwAb_SetDout_SetOutputGroup: operation=rpIoHwAb_SetDout.SetOutputGroup
            OA_rpIoHwAb_SetDout_SetOutputPin: operation=rpIoHwAb_SetDout.SetOutputPin
            OA_rp_CS_Backlight_Notify_NotifyDisplayPowerState: operation=rp_CS_Backlight_Notify.NotifyDisplayPowerState
            OA_rp_CS_Backlight_Status_GetStatus: operation=rp_CS_Backlight_Status.GetStatus
        CDisplayCdd_SetGammaCorrection
        CDisplayCdd_SetState
          4 x sync call, all with timeout=0.0:
            OA_rpIoHwAb_SetDout_SetOutputGroup: operation=rpIoHwAb_SetDout.SetOutputGroup
            OA_rpIoHwAb_SetDout_SetOutputPin: operation=rpIoHwAb_SetDout.SetOutputPin
            OA_rp_CS_Backlight_Notify_NotifyDisplayPowerState: operation=rp_CS_Backlight_Notify.NotifyDisplayPowerState
            OA_rp_CS_Backlight_Status_GetStatus: operation=rp_CS_Backlight_Status.GetStatus
  swc implementation IMPL_CDisplayCdd: programming-language=C, behavior=IB_CDisplayCdd
    code-descriptors:
      code CodeDescriptor
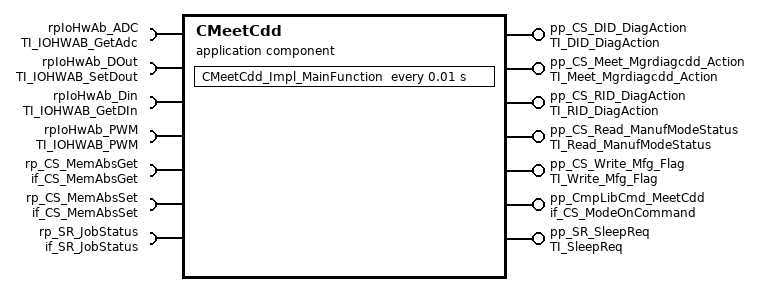
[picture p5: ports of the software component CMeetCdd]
  application sw component type CMeetCdd
    7 x provide port:
      pp_CS_DID_DiagAction: server-com-spec{operation=DID_DiagAction, queue-length=1}, provided-interface=TI_DID_DiagAction
      pp_CS_Meet_Mgrdiagcdd_Action: server-com-spec{operation=Meet_Mgrdiagcdd_Action, queue-length=1}, provided-interface=TI_Meet_Mgrdiagcdd_Action
      pp_CS_RID_DiagAction: server-com-spec{operation=RID_DiagAction, queue-length=1}, provided-interface=TI_RID_DiagAction
      pp_CS_Read_ManufModeStatus: server-com-spec{operation=Read_ManufModeStatus, queue-length=1}, provided-interface=TI_Read_ManufModeStatus
      pp_CS_Write_Mfg_Flag: server-com-spec{operation=Write_Mfg_Flag, queue-length=1}, provided-interface=TI_Write_Mfg_Flag
      pp_CmpLibCmd_MeetCdd: server-com-spec{operation=Impl_OnCommand, queue-length=1}, provided-interface=if_CS_ModeOnCommand
      pp_SR_SleepReq: nonqueued-sender-com-spec{data-element=SleepReqData, uses-end-to-end-protection=0, init-value=constant-reference=CMeetCddSleepReqDataValue0}, provided-interface=TI_SleepReq
    7 x require port:
      rpIoHwAb_ADC: required-interface=TI_IOHWAB_GetAdc
      rpIoHwAb_DOut: required-interface=TI_IOHWAB_SetDout
      rpIoHwAb_Din: required-interface=TI_IOHWAB_GetDIn
      rpIoHwAb_PWM: required-interface=TI_IOHWAB_PWM
      rp_CS_MemAbsGet: required-interface=if_CS_MemAbsGet
      rp_CS_MemAbsSet: required-interface=if_CS_MemAbsSet
      rp_SR_JobStatus: required-interface=if_SR_JobStatus
        required-com-specs:
          data-element=JobStatus_BsConst_Audio_Element, init-value=constant-reference=CMeetCddJobStatus_BsConst_Audio_ElementValue0
          data-element=JobStatus_BsConst_Communication_Element, init-value=constant-reference=CMeetCddJobStatus_BsConst_Communication_ElementValue0
          data-element=JobStatus_BsConst_EngOffTimer_Element, init-value=constant-reference=CMeetCddJobStatus_BsConst_EngOffTimer_ElementValue0
          data-element=JobStatus_BsConst_FuelGauge_Element, init-value=constant-reference=CMeetCddJobStatus_BsConst_FuelGauge_ElementValue0
          data-element=JobStatus_BsConst_Illumination_Element, init-value=constant-reference=CMeetCddJobStatus_BsConst_Illumination_ElementValue0
          data-element=JobStatus_BsConst_OilGauge_Element, init-value=constant-reference=CMeetCddJobStatus_BsConst_OilGauge_ElementValue0
          data-element=JobStatus_BsConst_PowerGauge_Element, init-value=constant-reference=CMeetCddJobStatus_BsConst_PowerGauge_ElementValue0
          data-element=JobStatus_BsConst_Power_Element, init-value=constant-reference=CMeetCddJobStatus_BsConst_Power_ElementValue0
          data-element=JobStatus_BsConst_RealTimeClock_Element, init-value=constant-reference=CMeetCddJobStatus_BsConst_RealTimeClock_ElementValue0
          data-element=JobStatus_BsConst_ServiceReminder_Element, init-value=constant-reference=CMeetCddJobStatus_BsConst_ServiceReminder_ElementValue0
          data-element=JobStatus_BsConst_SpeedoGauge_Element, init-value=constant-reference=CMeetCddJobStatus_BsConst_SpeedoGauge_ElementValue0
          data-element=JobStatus_BsConst_TachoGauge_Element, init-value=constant-reference=CMeetCddJobStatus_BsConst_TachoGauge_ElementValue0
          data-element=JobStatus_BsConst_TempGauge_Element, init-value=constant-reference=CMeetCddJobStatus_BsConst_TempGauge_ElementValue0
          data-element=JobStatus_BsConst_TripComputer_Element, init-value=constant-reference=CMeetCddJobStatus_BsConst_TripComputer_ElementValue0
          data-element=JobStatus_BsConst_Warning_Element, init-value=constant-reference=CMeetCddJobStatus_BsConst_Warning_ElementValue0
          data-element=JobStatus_BsCys_Certicificate_Element, init-value=constant-reference=CMeetCddJobStatus_BsCys_Certicificate_ElementValue0
          data-element=JobStatus_BsDiag_Dtc_Element, init-value=constant-reference=CMeetCddJobStatus_BsDiag_Dtc_ElementValue0
          data-element=JobStatus_BsDiag_ErrorRecord_Element, init-value=constant-reference=CMeetCddJobStatus_BsDiag_ErrorRecord_ElementValue0
          data-element=JobStatus_BsFuSa_Audio_Element, init-value=constant-reference=CMeetCddJobStatus_BsFuSa_Audio_ElementValue0
          data-element=JobStatus_BsFuSa_Communication_Element, init-value=constant-reference=CMeetCddJobStatus_BsFuSa_Communication_ElementValue0
          data-element=JobStatus_BsFuSa_Config_Element, init-value=constant-reference=CMeetCddJobStatus_BsFuSa_Config_ElementValue0
          data-element=JobStatus_BsFuSa_Display_Element, init-value=constant-reference=CMeetCddJobStatus_BsFuSa_Display_ElementValue0
          data-element=JobStatus_BsFuSa_Power_Element, init-value=constant-reference=CMeetCddJobStatus_BsFuSa_Power_ElementValue0
          data-element=JobStatus_BsFuSa_Warning_Element, init-value=constant-reference=CMeetCddJobStatus_BsFuSa_Warning_ElementValue0
          data-element=JobStatus_BsFusa_Fota_Element, init-value=constant-reference=CMeetCddJobStatus_BsFusa_Fota_ElementValue0
          data-element=JobStatus_BsReten_Audio_Element, init-value=constant-reference=CMeetCddJobStatus_BsReten_Audio_ElementValue0
          data-element=JobStatus_BsReten_Communication_Element, init-value=constant-reference=CMeetCddJobStatus_BsReten_Communication_ElementValue0
          data-element=JobStatus_BsReten_Display_Element, init-value=constant-reference=CMeetCddJobStatus_BsReten_Display_ElementValue0
          data-element=JobStatus_BsReten_Gauges_Element, init-value=constant-reference=CMeetCddJobStatus_BsReten_Gauges_ElementValue0
          data-element=JobStatus_BsReten_Illumination_Element, init-value=constant-reference=CMeetCddJobStatus_BsReten_Illumination_ElementValue0
          data-element=JobStatus_BsReten_Odometer_Element, init-value=constant-reference=CMeetCddJobStatus_BsReten_Odometer_ElementValue0
          data-element=JobStatus_BsReten_Personalization_Element, init-value=constant-reference=CMeetCddJobStatus_BsReten_Personalization_ElementValue0
          data-element=JobStatus_BsReten_Power_Element, init-value=constant-reference=CMeetCddJobStatus_BsReten_Power_ElementValue0
          data-element=JobStatus_BsReten_RealTimeClock_Element, init-value=constant-reference=CMeetCddJobStatus_BsReten_RealTimeClock_ElementValue0
          data-element=JobStatus_BsReten_Tripcomputer_Element, init-value=constant-reference=CMeetCddJobStatus_BsReten_Tripcomputer_ElementValue0
          data-element=JobStatus_BsReten_VisDlt_Element, init-value=constant-reference=CMeetCddJobStatus_BsReten_VisDlt_ElementValue0
          data-element=JobStatus_BsReten_Warning_Element, init-value=constant-reference=CMeetCddJobStatus_BsReten_Warning_ElementValue0
          data-element=JobStatus_BsRt_CusDlt_Element, init-value=constant-reference=CMeetCddJobStatus_BsRt_CusDlt_ElementValue0
          data-element=JobStatus_BsRt_FuelGauge_Element, init-value=constant-reference=CMeetCddJobStatus_BsRt_FuelGauge_ElementValue0
          data-element=JobStatus_BsRt_Illumination_Element, init-value=constant-reference=CMeetCddJobStatus_BsRt_Illumination_ElementValue0
          data-element=JobStatus_BsRt_Odometer_Element, init-value=constant-reference=CMeetCddJobStatus_BsRt_Odometer_ElementValue0
          data-element=JobStatus_BsRt_OilGauge_Element, init-value=constant-reference=CMeetCddJobStatus_BsRt_OilGauge_ElementValue0
          data-element=JobStatus_BsRt_Personalization_Element, init-value=constant-reference=CMeetCddJobStatus_BsRt_Personalization_ElementValue0
          data-element=JobStatus_BsRt_PowerGauge_Element, init-value=constant-reference=CMeetCddJobStatus_BsRt_PowerGauge_ElementValue0
          data-element=JobStatus_BsRt_RealTimeClock_Element, init-value=constant-reference=CMeetCddJobStatus_BsRt_RealTimeClock_ElementValue0
          data-element=JobStatus_BsRt_SpeedoGauge_Element, init-value=constant-reference=CMeetCddJobStatus_BsRt_SpeedoGauge_ElementValue0
          data-element=JobStatus_BsRt_TachoGauge_Element, init-value=constant-reference=CMeetCddJobStatus_BsRt_TachoGauge_ElementValue0
          data-element=JobStatus_BsRt_TempGauge_Element, init-value=constant-reference=CMeetCddJobStatus_BsRt_TempGauge_ElementValue0
          data-element=JobStatus_BsRt_TripComputer_Element, init-value=constant-reference=CMeetCddJobStatus_BsRt_TripComputer_ElementValue0
          data-element=JobStatus_BsRt_Warning_Element, init-value=constant-reference=CMeetCddJobStatus_BsRt_Warning_ElementValue0
          data-element=JobStatus_BsShare_EcuPartNumber_Element, init-value=constant-reference=CMeetCddJobStatus_BsShare_EcuPartNumber_ElementValue0
          data-element=JobStatus_BsShare_SwUpdFotaFinPrint_Element, init-value=constant-reference=CMeetCddJobStatus_BsShare_SwUpdFotaFinPrint_ElementValue0
          data-element=JobStatus_BsShare_SwUpdFotaMode_Element, init-value=constant-reference=CMeetCddJobStatus_BsShare_SwUpdFotaMode_ElementValue0
          data-element=JobStatus_BsShare_SwUpdFotaStatus_Element, init-value=constant-reference=CMeetCddJobStatus_BsShare_SwUpdFotaStatus_ElementValue0
          data-element=JobStatus_BsShare_SwUpdFotadecrypt_Element, init-value=constant-reference=CMeetCddJobStatus_BsShare_SwUpdFotadecrypt_ElementValue0
          data-element=JobStatus_BsShare_SwUpdReflash_Element, init-value=constant-reference=CMeetCddJobStatus_BsShare_SwUpdReflash_ElementValue0
          data-element=JobStatus_BsShare_VehicleConfig_Element, init-value=constant-reference=CMeetCddJobStatus_BsShare_VehicleConfig_ElementValue0
          data-element=JobStatus_BsShare_VisMeet_Element, init-value=constant-reference=CMeetCddJobStatus_BsShare_VisMeet_ElementValue0
          data-element=JobStatus_RefCys_Certicificate1_Element, init-value=constant-reference=CMeetCddJobStatus_RefCys_Certicificate1_ElementValue0
          data-element=JobStatus_RefCys_Certicificate_Element, init-value=constant-reference=CMeetCddJobStatus_RefCys_Certicificate_ElementValue0
    behavior IB_CMeetCdd
      operation invoked event OIE_pp_CS_DID_DiagAction_CMeetCdd_DID_DiagActionTrigByDID_DiagAction: start-on-event=CMeetCdd_DID_DiagAction, operation=pp_CS_DID_DiagAction.DID_DiagAction
      timing event TECMeetCdd_Impl_MainFunction: start-on-event=CMeetCdd_Impl_MainFunction, period=0.01
      5 x operation invoked event:
        OIE_pp_CmpLibCmd_MeetCdd_CMeetCdd_Impl_OnCommandTrigByImpl_OnCommand: start-on-event=CMeetCdd_Impl_OnCommand, operation=pp_CmpLibCmd_MeetCdd.Impl_OnCommand
        OIE_pp_CS_Meet_Mgrdiagcdd_Action_CMeetCdd_Meet_Mgrdiagcdd_ActionTrigByMeet_Mgrdiagcdd_Action: start-on-event=CMeetCdd_Meet_Mgrdiagcdd_Action, operation=pp_CS_Meet_Mgrdiagcdd_Action.Meet_Mgrdiagcdd_Action
        OIE_pp_CS_RID_DiagAction_CMeetCdd_RID_DiagActionTrigByRID_DiagAction: start-on-event=CMeetCdd_RID_DiagAction, operation=pp_CS_RID_DiagAction.RID_DiagAction
        OIE_pp_CS_Read_ManufModeStatus_CMeetCdd_Read_ManufModeStatusTrigByRead_ManufModeStatus: start-on-event=CMeetCdd_Read_ManufModeStatus, operation=pp_CS_Read_ManufModeStatus.Read_ManufModeStatus
        OIE_pp_CS_Write_Mfg_Flag_CMeetCdd_Write_Mfg_FlagTrigByWrite_Mfg_Flag: start-on-event=CMeetCdd_Write_Mfg_Flag, operation=pp_CS_Write_Mfg_Flag.Write_Mfg_Flag
      port-api-options:
        enable-take-address=false, indirect-api=false, port=pp_CS_DID_DiagAction
        enable-take-address=false, indirect-api=false, port=pp_CS_Meet_Mgrdiagcdd_Action
        enable-take-address=false, indirect-api=false, port=pp_CS_RID_DiagAction
        enable-take-address=false, indirect-api=false, port=pp_CS_Read_ManufModeStatus
        enable-take-address=false, indirect-api=false, port=pp_CS_Write_Mfg_Flag
        enable-take-address=false, indirect-api=false, port=pp_CmpLibCmd_MeetCdd
        enable-take-address=false, indirect-api=false, port=pp_SR_SleepReq
        enable-take-address=false, indirect-api=false, port=CMeetCdd/rpIoHwAb_ADC
        enable-take-address=false, indirect-api=false, port=CMeetCdd/rpIoHwAb_DOut
        enable-take-address=false, indirect-api=false, port=CMeetCdd/rpIoHwAb_Din
        enable-take-address=false, indirect-api=false, port=CMeetCdd/rpIoHwAb_PWM
        enable-take-address=false, indirect-api=false, port=rp_CS_MemAbsGet
        enable-take-address=false, indirect-api=false, port=rp_CS_MemAbsSet
        enable-take-address=false, indirect-api=false, port=rp_SR_JobStatus
      7 x runnable, all with can-be-invoked-concurrently=true:
        CMeetCdd_DID_DiagAction
        CMeetCdd_Impl_MainFunction
          data-receive-point-by-arguments:
            60 x access:
              DRA_rp_SR_JobStatus_JobStatus_BsConst_Audio_Element: accessed-variable=rp_SR_JobStatus.JobStatus_BsConst_Audio_Element
              DRA_rp_SR_JobStatus_JobStatus_BsConst_Communication_Element: accessed-variable=rp_SR_JobStatus.JobStatus_BsConst_Communication_Element
              DRA_rp_SR_JobStatus_JobStatus_BsConst_EngOffTimer_Element: accessed-variable=rp_SR_JobStatus.JobStatus_BsConst_EngOffTimer_Element
              DRA_rp_SR_JobStatus_JobStatus_BsConst_FuelGauge_Element: accessed-variable=rp_SR_JobStatus.JobStatus_BsConst_FuelGauge_Element
              DRA_rp_SR_JobStatus_JobStatus_BsConst_Illumination_Element: accessed-variable=rp_SR_JobStatus.JobStatus_BsConst_Illumination_Element
              DRA_rp_SR_JobStatus_JobStatus_BsConst_OilGauge_Element: accessed-variable=rp_SR_JobStatus.JobStatus_BsConst_OilGauge_Element
              DRA_rp_SR_JobStatus_JobStatus_BsConst_PowerGauge_Element: accessed-variable=rp_SR_JobStatus.JobStatus_BsConst_PowerGauge_Element
              DRA_rp_SR_JobStatus_JobStatus_BsConst_Power_Element: accessed-variable=rp_SR_JobStatus.JobStatus_BsConst_Power_Element
              DRA_rp_SR_JobStatus_JobStatus_BsConst_RealTimeClock_Element: accessed-variable=rp_SR_JobStatus.JobStatus_BsConst_RealTimeClock_Element
              DRA_rp_SR_JobStatus_JobStatus_BsConst_ServiceReminder_Element: accessed-variable=rp_SR_JobStatus.JobStatus_BsConst_ServiceReminder_Element
              DRA_rp_SR_JobStatus_JobStatus_BsConst_SpeedoGauge_Element: accessed-variable=rp_SR_JobStatus.JobStatus_BsConst_SpeedoGauge_Element
              DRA_rp_SR_JobStatus_JobStatus_BsConst_TachoGauge_Element: accessed-variable=rp_SR_JobStatus.JobStatus_BsConst_TachoGauge_Element
              DRA_rp_SR_JobStatus_JobStatus_BsConst_TempGauge_Element: accessed-variable=rp_SR_JobStatus.JobStatus_BsConst_TempGauge_Element
              DRA_rp_SR_JobStatus_JobStatus_BsConst_TripComputer_Element: accessed-variable=rp_SR_JobStatus.JobStatus_BsConst_TripComputer_Element
              DRA_rp_SR_JobStatus_JobStatus_BsConst_Warning_Element: accessed-variable=rp_SR_JobStatus.JobStatus_BsConst_Warning_Element
              DRA_rp_SR_JobStatus_JobStatus_BsCys_Certicificate_Element: accessed-variable=rp_SR_JobStatus.JobStatus_BsCys_Certicificate_Element
              DRA_rp_SR_JobStatus_JobStatus_BsDiag_Dtc_Element: accessed-variable=rp_SR_JobStatus.JobStatus_BsDiag_Dtc_Element
              DRA_rp_SR_JobStatus_JobStatus_BsDiag_ErrorRecord_Element: accessed-variable=rp_SR_JobStatus.JobStatus_BsDiag_ErrorRecord_Element
              DRA_rp_SR_JobStatus_JobStatus_BsFuSa_Audio_Element: accessed-variable=rp_SR_JobStatus.JobStatus_BsFuSa_Audio_Element
              DRA_rp_SR_JobStatus_JobStatus_BsFuSa_Communication_Element: accessed-variable=rp_SR_JobStatus.JobStatus_BsFuSa_Communication_Element
              DRA_rp_SR_JobStatus_JobStatus_BsFuSa_Config_Element: accessed-variable=rp_SR_JobStatus.JobStatus_BsFuSa_Config_Element
              DRA_rp_SR_JobStatus_JobStatus_BsFuSa_Display_Element: accessed-variable=rp_SR_JobStatus.JobStatus_BsFuSa_Display_Element
              DRA_rp_SR_JobStatus_JobStatus_BsFuSa_Power_Element: accessed-variable=rp_SR_JobStatus.JobStatus_BsFuSa_Power_Element
              DRA_rp_SR_JobStatus_JobStatus_BsFuSa_Warning_Element: accessed-variable=rp_SR_JobStatus.JobStatus_BsFuSa_Warning_Element
              DRA_rp_SR_JobStatus_JobStatus_BsFusa_Fota_Element: accessed-variable=rp_SR_JobStatus.JobStatus_BsFusa_Fota_Element
              DRA_rp_SR_JobStatus_JobStatus_BsReten_Audio_Element: accessed-variable=rp_SR_JobStatus.JobStatus_BsReten_Audio_Element
              DRA_rp_SR_JobStatus_JobStatus_BsReten_Communication_Element: accessed-variable=rp_SR_JobStatus.JobStatus_BsReten_Communication_Element
              DRA_rp_SR_JobStatus_JobStatus_BsReten_Display_Element: accessed-variable=rp_SR_JobStatus.JobStatus_BsReten_Display_Element
              DRA_rp_SR_JobStatus_JobStatus_BsReten_Gauges_Element: accessed-variable=rp_SR_JobStatus.JobStatus_BsReten_Gauges_Element
              DRA_rp_SR_JobStatus_JobStatus_BsReten_Illumination_Element: accessed-variable=rp_SR_JobStatus.JobStatus_BsReten_Illumination_Element
              DRA_rp_SR_JobStatus_JobStatus_BsReten_Odometer_Element: accessed-variable=rp_SR_JobStatus.JobStatus_BsReten_Odometer_Element
              DRA_rp_SR_JobStatus_JobStatus_BsReten_Personalization_Element: accessed-variable=rp_SR_JobStatus.JobStatus_BsReten_Personalization_Element
              DRA_rp_SR_JobStatus_JobStatus_BsReten_Power_Element: accessed-variable=rp_SR_JobStatus.JobStatus_BsReten_Power_Element
              DRA_rp_SR_JobStatus_JobStatus_BsReten_RealTimeClock_Element: accessed-variable=rp_SR_JobStatus.JobStatus_BsReten_RealTimeClock_Element
              DRA_rp_SR_JobStatus_JobStatus_BsReten_Tripcomputer_Element: accessed-variable=rp_SR_JobStatus.JobStatus_BsReten_Tripcomputer_Element
              DRA_rp_SR_JobStatus_JobStatus_BsReten_VisDlt_Element: accessed-variable=rp_SR_JobStatus.JobStatus_BsReten_VisDlt_Element
              DRA_rp_SR_JobStatus_JobStatus_BsReten_Warning_Element: accessed-variable=rp_SR_JobStatus.JobStatus_BsReten_Warning_Element
              DRA_rp_SR_JobStatus_JobStatus_BsRt_CusDlt_Element: accessed-variable=rp_SR_JobStatus.JobStatus_BsRt_CusDlt_Element
              DRA_rp_SR_JobStatus_JobStatus_BsRt_FuelGauge_Element: accessed-variable=rp_SR_JobStatus.JobStatus_BsRt_FuelGauge_Element
              DRA_rp_SR_JobStatus_JobStatus_BsRt_Illumination_Element: accessed-variable=rp_SR_JobStatus.JobStatus_BsRt_Illumination_Element
              DRA_rp_SR_JobStatus_JobStatus_BsRt_Odometer_Element: accessed-variable=rp_SR_JobStatus.JobStatus_BsRt_Odometer_Element
              DRA_rp_SR_JobStatus_JobStatus_BsRt_OilGauge_Element: accessed-variable=rp_SR_JobStatus.JobStatus_BsRt_OilGauge_Element
              DRA_rp_SR_JobStatus_JobStatus_BsRt_Personalization_Element: accessed-variable=rp_SR_JobStatus.JobStatus_BsRt_Personalization_Element
              DRA_rp_SR_JobStatus_JobStatus_BsRt_PowerGauge_Element: accessed-variable=rp_SR_JobStatus.JobStatus_BsRt_PowerGauge_Element
              DRA_rp_SR_JobStatus_JobStatus_BsRt_RealTimeClock_Element: accessed-variable=rp_SR_JobStatus.JobStatus_BsRt_RealTimeClock_Element
              DRA_rp_SR_JobStatus_JobStatus_BsRt_SpeedoGauge_Element: accessed-variable=rp_SR_JobStatus.JobStatus_BsRt_SpeedoGauge_Element
              DRA_rp_SR_JobStatus_JobStatus_BsRt_TachoGauge_Element: accessed-variable=rp_SR_JobStatus.JobStatus_BsRt_TachoGauge_Element
              DRA_rp_SR_JobStatus_JobStatus_BsRt_TempGauge_Element: accessed-variable=rp_SR_JobStatus.JobStatus_BsRt_TempGauge_Element
              DRA_rp_SR_JobStatus_JobStatus_BsRt_TripComputer_Element: accessed-variable=rp_SR_JobStatus.JobStatus_BsRt_TripComputer_Element
              DRA_rp_SR_JobStatus_JobStatus_BsRt_Warning_Element: accessed-variable=rp_SR_JobStatus.JobStatus_BsRt_Warning_Element
              DRA_rp_SR_JobStatus_JobStatus_BsShare_EcuPartNumber_Element: accessed-variable=rp_SR_JobStatus.JobStatus_BsShare_EcuPartNumber_Element
              DRA_rp_SR_JobStatus_JobStatus_BsShare_SwUpdFotaFinPrint_Element: accessed-variable=rp_SR_JobStatus.JobStatus_BsShare_SwUpdFotaFinPrint_Element
              DRA_rp_SR_JobStatus_JobStatus_BsShare_SwUpdFotaMode_Element: accessed-variable=rp_SR_JobStatus.JobStatus_BsShare_SwUpdFotaMode_Element
              DRA_rp_SR_JobStatus_JobStatus_BsShare_SwUpdFotaStatus_Element: accessed-variable=rp_SR_JobStatus.JobStatus_BsShare_SwUpdFotaStatus_Element
              DRA_rp_SR_JobStatus_JobStatus_BsShare_SwUpdFotadecrypt_Element: accessed-variable=rp_SR_JobStatus.JobStatus_BsShare_SwUpdFotadecrypt_Element
              DRA_rp_SR_JobStatus_JobStatus_BsShare_SwUpdReflash_Element: accessed-variable=rp_SR_JobStatus.JobStatus_BsShare_SwUpdReflash_Element
              DRA_rp_SR_JobStatus_JobStatus_BsShare_VehicleConfig_Element: accessed-variable=rp_SR_JobStatus.JobStatus_BsShare_VehicleConfig_Element
              DRA_rp_SR_JobStatus_JobStatus_BsShare_VisMeet_Element: accessed-variable=rp_SR_JobStatus.JobStatus_BsShare_VisMeet_Element
              DRA_rp_SR_JobStatus_JobStatus_RefCys_Certicificate1_Element: accessed-variable=rp_SR_JobStatus.JobStatus_RefCys_Certicificate1_Element
              DRA_rp_SR_JobStatus_JobStatus_RefCys_Certicificate_Element: accessed-variable=rp_SR_JobStatus.JobStatus_RefCys_Certicificate_Element
          data-send-points:
            access DWA_pp_SR_SleepReq_SleepReqData: accessed-variable=pp_SR_SleepReq.SleepReqData
          132 x sync call, all with timeout=0.0:
            OA_rpIoHwAb_ADC_GetAsyncRawAdc: operation=rpIoHwAb_ADC.GetAsyncRawAdc
            OA_rpIoHwAb_ADC_GetSyncRawAdc: operation=rpIoHwAb_ADC.GetSyncRawAdc
            OA_rpIoHwAb_ADC_GetProcessedAdc: operation=rpIoHwAb_ADC.GetProcessedAdc
            OA_rpIoHwAb_DOut_SetOutputGroup: operation=rpIoHwAb_DOut.SetOutputGroup
            OA_rpIoHwAb_DOut_SetOutputPin: operation=rpIoHwAb_DOut.SetOutputPin
            OA_rpIoHwAb_Din_GetAsyncRawInput: operation=rpIoHwAb_Din.GetAsyncRawInput
            OA_rpIoHwAb_Din_GetProcessedInput: operation=rpIoHwAb_Din.GetProcessedInput
            OA_rpIoHwAb_Din_GetSyncRawInput: operation=rpIoHwAb_Din.GetSyncRawInput
            OA_rpIoHwAb_Din_GetInputGroup: operation=rpIoHwAb_Din.GetInputGroup
            OA_rpIoHwAb_PWM_PwmSetDuty: operation=rpIoHwAb_PWM.PwmSetDuty
            OA_rpIoHwAb_PWM_PwmSetDutyAndPeriod: operation=rpIoHwAb_PWM.PwmSetDutyAndPeriod
            OA_rpIoHwAb_PWM_PwmSetIdeal: operation=rpIoHwAb_PWM.PwmSetIdeal
            OA_rp_CS_MemAbsGet_Get_BsShare_SwUpdReflash_Element: operation=rp_CS_MemAbsGet.Get_BsShare_SwUpdReflash_Element
            OA_rp_CS_MemAbsGet_Get_BsShare_SwUpdFotaMode_Element: operation=rp_CS_MemAbsGet.Get_BsShare_SwUpdFotaMode_Element
            OA_rp_CS_MemAbsGet_Get_BsShare_SwUpdFotaFinPrint_Element: operation=rp_CS_MemAbsGet.Get_BsShare_SwUpdFotaFinPrint_Element
            OA_rp_CS_MemAbsGet_Get_BsShare_SwUpdFotaStatus_Element: operation=rp_CS_MemAbsGet.Get_BsShare_SwUpdFotaStatus_Element
            OA_rp_CS_MemAbsGet_Get_BsShare_SwUpdFotadecrypt_Element: operation=rp_CS_MemAbsGet.Get_BsShare_SwUpdFotadecrypt_Element
            OA_rp_CS_MemAbsGet_Get_BsShare_EcuPartNumber_Element: operation=rp_CS_MemAbsGet.Get_BsShare_EcuPartNumber_Element
            OA_rp_CS_MemAbsGet_Get_BsShare_VisMeet_Element: operation=rp_CS_MemAbsGet.Get_BsShare_VisMeet_Element
            OA_rp_CS_MemAbsGet_Get_BsShare_VehicleConfig_Element: operation=rp_CS_MemAbsGet.Get_BsShare_VehicleConfig_Element
            OA_rp_CS_MemAbsGet_Get_BsConst_SpeedoGauge_Element: operation=rp_CS_MemAbsGet.Get_BsConst_SpeedoGauge_Element
            OA_rp_CS_MemAbsGet_Get_BsConst_TachoGauge_Element: operation=rp_CS_MemAbsGet.Get_BsConst_TachoGauge_Element
            OA_rp_CS_MemAbsGet_Get_BsConst_FuelGauge_Element: operation=rp_CS_MemAbsGet.Get_BsConst_FuelGauge_Element
            OA_rp_CS_MemAbsGet_Get_BsConst_TempGauge_Element: operation=rp_CS_MemAbsGet.Get_BsConst_TempGauge_Element
            OA_rp_CS_MemAbsGet_Get_BsConst_PowerGauge_Element: operation=rp_CS_MemAbsGet.Get_BsConst_PowerGauge_Element
            OA_rp_CS_MemAbsGet_Get_BsConst_OilGauge_Element: operation=rp_CS_MemAbsGet.Get_BsConst_OilGauge_Element
            OA_rp_CS_MemAbsGet_Get_BsConst_TripComputer_Element: operation=rp_CS_MemAbsGet.Get_BsConst_TripComputer_Element
            OA_rp_CS_MemAbsGet_Get_BsConst_Illumination_Element: operation=rp_CS_MemAbsGet.Get_BsConst_Illumination_Element
            OA_rp_CS_MemAbsGet_Get_BsConst_Audio_Element: operation=rp_CS_MemAbsGet.Get_BsConst_Audio_Element
            OA_rp_CS_MemAbsGet_Get_BsConst_Warning_Element: operation=rp_CS_MemAbsGet.Get_BsConst_Warning_Element
            OA_rp_CS_MemAbsGet_Get_BsConst_RealTimeClock_Element: operation=rp_CS_MemAbsGet.Get_BsConst_RealTimeClock_Element
            OA_rp_CS_MemAbsGet_Get_BsConst_Communication_Element: operation=rp_CS_MemAbsGet.Get_BsConst_Communication_Element
            OA_rp_CS_MemAbsGet_Get_BsConst_Power_Element: operation=rp_CS_MemAbsGet.Get_BsConst_Power_Element
            OA_rp_CS_MemAbsGet_Get_BsConst_ServiceReminder_Element: operation=rp_CS_MemAbsGet.Get_BsConst_ServiceReminder_Element
            OA_rp_CS_MemAbsGet_Get_BsConst_EngOffTimer_Element: operation=rp_CS_MemAbsGet.Get_BsConst_EngOffTimer_Element
            OA_rp_CS_MemAbsGet_Get_BsFuSa_Warning_Element: operation=rp_CS_MemAbsGet.Get_BsFuSa_Warning_Element
            OA_rp_CS_MemAbsGet_Get_BsFuSa_Power_Element: operation=rp_CS_MemAbsGet.Get_BsFuSa_Power_Element
            OA_rp_CS_MemAbsGet_Get_BsFuSa_Display_Element: operation=rp_CS_MemAbsGet.Get_BsFuSa_Display_Element
            OA_rp_CS_MemAbsGet_Get_BsFuSa_Audio_Element: operation=rp_CS_MemAbsGet.Get_BsFuSa_Audio_Element
            OA_rp_CS_MemAbsGet_Get_BsFuSa_Communication_Element: operation=rp_CS_MemAbsGet.Get_BsFuSa_Communication_Element
            OA_rp_CS_MemAbsGet_Get_BsFusa_Fota_Element: operation=rp_CS_MemAbsGet.Get_BsFusa_Fota_Element
            OA_rp_CS_MemAbsGet_Get_BsFuSa_Config_Element: operation=rp_CS_MemAbsGet.Get_BsFuSa_Config_Element
            OA_rp_CS_MemAbsGet_Get_BsCys_Certicificate_Element: operation=rp_CS_MemAbsGet.Get_BsCys_Certicificate_Element
            OA_rp_CS_MemAbsGet_Get_RefCys_Certicificate_Element: operation=rp_CS_MemAbsGet.Get_RefCys_Certicificate_Element
            OA_rp_CS_MemAbsGet_Get_RefCys_Certicificate1_Element: operation=rp_CS_MemAbsGet.Get_RefCys_Certicificate1_Element
            OA_rp_CS_MemAbsGet_Get_BsRt_Odometer_Element: operation=rp_CS_MemAbsGet.Get_BsRt_Odometer_Element
            OA_rp_CS_MemAbsGet_Get_BsRt_SpeedoGauge_Element: operation=rp_CS_MemAbsGet.Get_BsRt_SpeedoGauge_Element
            OA_rp_CS_MemAbsGet_Get_BsRt_TachoGauge_Element: operation=rp_CS_MemAbsGet.Get_BsRt_TachoGauge_Element
            OA_rp_CS_MemAbsGet_Get_BsRt_FuelGauge_Element: operation=rp_CS_MemAbsGet.Get_BsRt_FuelGauge_Element
            OA_rp_CS_MemAbsGet_Get_BsRt_TempGauge_Element: operation=rp_CS_MemAbsGet.Get_BsRt_TempGauge_Element
            OA_rp_CS_MemAbsGet_Get_BsRt_PowerGauge_Element: operation=rp_CS_MemAbsGet.Get_BsRt_PowerGauge_Element
            OA_rp_CS_MemAbsGet_Get_BsRt_OilGauge_Element: operation=rp_CS_MemAbsGet.Get_BsRt_OilGauge_Element
            OA_rp_CS_MemAbsGet_Get_BsRt_TripComputer_Element: operation=rp_CS_MemAbsGet.Get_BsRt_TripComputer_Element
            OA_rp_CS_MemAbsGet_Get_BsRt_Warning_Element: operation=rp_CS_MemAbsGet.Get_BsRt_Warning_Element
            OA_rp_CS_MemAbsGet_Get_BsRt_RealTimeClock_Element: operation=rp_CS_MemAbsGet.Get_BsRt_RealTimeClock_Element
            OA_rp_CS_MemAbsGet_Get_BsRt_Personalization_Element: operation=rp_CS_MemAbsGet.Get_BsRt_Personalization_Element
            OA_rp_CS_MemAbsGet_Get_BsRt_Illumination_Element: operation=rp_CS_MemAbsGet.Get_BsRt_Illumination_Element
            OA_rp_CS_MemAbsGet_Get_BsRt_CusDlt_Element: operation=rp_CS_MemAbsGet.Get_BsRt_CusDlt_Element
            OA_rp_CS_MemAbsGet_Get_BsReten_Odometer_Element: operation=rp_CS_MemAbsGet.Get_BsReten_Odometer_Element
            OA_rp_CS_MemAbsGet_Get_BsReten_Gauges_Element: operation=rp_CS_MemAbsGet.Get_BsReten_Gauges_Element
            OA_rp_CS_MemAbsGet_Get_BsReten_Tripcomputer_Element: operation=rp_CS_MemAbsGet.Get_BsReten_Tripcomputer_Element
            OA_rp_CS_MemAbsGet_Get_BsReten_Illumination_Element: operation=rp_CS_MemAbsGet.Get_BsReten_Illumination_Element
            OA_rp_CS_MemAbsGet_Get_BsReten_Audio_Element: operation=rp_CS_MemAbsGet.Get_BsReten_Audio_Element
            OA_rp_CS_MemAbsGet_Get_BsReten_Warning_Element: operation=rp_CS_MemAbsGet.Get_BsReten_Warning_Element
            OA_rp_CS_MemAbsGet_Get_BsReten_RealTimeClock_Element: operation=rp_CS_MemAbsGet.Get_BsReten_RealTimeClock_Element
            OA_rp_CS_MemAbsGet_Get_BsReten_Communication_Element: operation=rp_CS_MemAbsGet.Get_BsReten_Communication_Element
            OA_rp_CS_MemAbsGet_Get_BsReten_Personalization_Element: operation=rp_CS_MemAbsGet.Get_BsReten_Personalization_Element
            OA_rp_CS_MemAbsGet_Get_BsReten_VisDlt_Element: operation=rp_CS_MemAbsGet.Get_BsReten_VisDlt_Element
            OA_rp_CS_MemAbsGet_Get_BsReten_Power_Element: operation=rp_CS_MemAbsGet.Get_BsReten_Power_Element
            OA_rp_CS_MemAbsGet_Get_BsReten_Display_Element: operation=rp_CS_MemAbsGet.Get_BsReten_Display_Element
            OA_rp_CS_MemAbsGet_Get_BsDiag_ErrorRecord_Element: operation=rp_CS_MemAbsGet.Get_BsDiag_ErrorRecord_Element
            OA_rp_CS_MemAbsGet_Get_BsDiag_Dtc_Element: operation=rp_CS_MemAbsGet.Get_BsDiag_Dtc_Element
            OA_rp_CS_MemAbsSet_Set_BsShare_SwUpdReflash_Element: operation=rp_CS_MemAbsSet.Set_BsShare_SwUpdReflash_Element
            OA_rp_CS_MemAbsSet_Set_BsShare_SwUpdFotaMode_Element: operation=rp_CS_MemAbsSet.Set_BsShare_SwUpdFotaMode_Element
            OA_rp_CS_MemAbsSet_Set_BsShare_SwUpdFotaFinPrint_Element: operation=rp_CS_MemAbsSet.Set_BsShare_SwUpdFotaFinPrint_Element
            OA_rp_CS_MemAbsSet_Set_BsShare_SwUpdFotaStatus_Element: operation=rp_CS_MemAbsSet.Set_BsShare_SwUpdFotaStatus_Element
            OA_rp_CS_MemAbsSet_Set_BsShare_SwUpdFotadecrypt_Element: operation=rp_CS_MemAbsSet.Set_BsShare_SwUpdFotadecrypt_Element
            OA_rp_CS_MemAbsSet_Set_BsShare_EcuPartNumber_Element: operation=rp_CS_MemAbsSet.Set_BsShare_EcuPartNumber_Element
            OA_rp_CS_MemAbsSet_Set_BsShare_VisMeet_Element: operation=rp_CS_MemAbsSet.Set_BsShare_VisMeet_Element
            OA_rp_CS_MemAbsSet_Set_BsShare_VehicleConfig_Element: operation=rp_CS_MemAbsSet.Set_BsShare_VehicleConfig_Element
            OA_rp_CS_MemAbsSet_Set_BsConst_SpeedoGauge_Element: operation=rp_CS_MemAbsSet.Set_BsConst_SpeedoGauge_Element
            OA_rp_CS_MemAbsSet_Set_BsConst_TachoGauge_Element: operation=rp_CS_MemAbsSet.Set_BsConst_TachoGauge_Element
            OA_rp_CS_MemAbsSet_Set_BsConst_FuelGauge_Element: operation=rp_CS_MemAbsSet.Set_BsConst_FuelGauge_Element
            OA_rp_CS_MemAbsSet_Set_BsConst_TempGauge_Element: operation=rp_CS_MemAbsSet.Set_BsConst_TempGauge_Element
            OA_rp_CS_MemAbsSet_Set_BsConst_PowerGauge_Element: operation=rp_CS_MemAbsSet.Set_BsConst_PowerGauge_Element
            OA_rp_CS_MemAbsSet_Set_BsConst_OilGauge_Element: operation=rp_CS_MemAbsSet.Set_BsConst_OilGauge_Element
            OA_rp_CS_MemAbsSet_Set_BsConst_TripComputer_Element: operation=rp_CS_MemAbsSet.Set_BsConst_TripComputer_Element
            OA_rp_CS_MemAbsSet_Set_BsConst_Illumination_Element: operation=rp_CS_MemAbsSet.Set_BsConst_Illumination_Element
            OA_rp_CS_MemAbsSet_Set_BsConst_Audio_Element: operation=rp_CS_MemAbsSet.Set_BsConst_Audio_Element
            OA_rp_CS_MemAbsSet_Set_BsConst_Warning_Element: operation=rp_CS_MemAbsSet.Set_BsConst_Warning_Element
            OA_rp_CS_MemAbsSet_Set_BsConst_RealTimeClock_Element: operation=rp_CS_MemAbsSet.Set_BsConst_RealTimeClock_Element
            OA_rp_CS_MemAbsSet_Set_BsConst_Communication_Element: operation=rp_CS_MemAbsSet.Set_BsConst_Communication_Element
            OA_rp_CS_MemAbsSet_Set_BsConst_Power_Element: operation=rp_CS_MemAbsSet.Set_BsConst_Power_Element
            OA_rp_CS_MemAbsSet_Set_BsConst_ServiceReminder_Element: operation=rp_CS_MemAbsSet.Set_BsConst_ServiceReminder_Element
            OA_rp_CS_MemAbsSet_Set_BsConst_EngOffTimer_Element: operation=rp_CS_MemAbsSet.Set_BsConst_EngOffTimer_Element
            OA_rp_CS_MemAbsSet_Set_BsFuSa_Warning_Element: operation=rp_CS_MemAbsSet.Set_BsFuSa_Warning_Element
            OA_rp_CS_MemAbsSet_Set_BsFuSa_Power_Element: operation=rp_CS_MemAbsSet.Set_BsFuSa_Power_Element
            OA_rp_CS_MemAbsSet_Set_BsFuSa_Display_Element: operation=rp_CS_MemAbsSet.Set_BsFuSa_Display_Element
            OA_rp_CS_MemAbsSet_Set_BsFuSa_Audio_Element: operation=rp_CS_MemAbsSet.Set_BsFuSa_Audio_Element
            OA_rp_CS_MemAbsSet_Set_BsFuSa_Communication_Element: operation=rp_CS_MemAbsSet.Set_BsFuSa_Communication_Element
            OA_rp_CS_MemAbsSet_Set_BsFusa_Fota_Element: operation=rp_CS_MemAbsSet.Set_BsFusa_Fota_Element
            OA_rp_CS_MemAbsSet_Set_BsFuSa_Config_Element: operation=rp_CS_MemAbsSet.Set_BsFuSa_Config_Element
            OA_rp_CS_MemAbsSet_Set_BsCys_Certicificate_Element: operation=rp_CS_MemAbsSet.Set_BsCys_Certicificate_Element
            OA_rp_CS_MemAbsSet_Set_RefCys_Certicificate_Element: operation=rp_CS_MemAbsSet.Set_RefCys_Certicificate_Element
            OA_rp_CS_MemAbsSet_Set_RefCys_Certicificate1_Element: operation=rp_CS_MemAbsSet.Set_RefCys_Certicificate1_Element
            OA_rp_CS_MemAbsSet_Set_BsRt_Odometer_Element: operation=rp_CS_MemAbsSet.Set_BsRt_Odometer_Element
            OA_rp_CS_MemAbsSet_Set_BsRt_SpeedoGauge_Element: operation=rp_CS_MemAbsSet.Set_BsRt_SpeedoGauge_Element
            OA_rp_CS_MemAbsSet_Set_BsRt_TachoGauge_Element: operation=rp_CS_MemAbsSet.Set_BsRt_TachoGauge_Element
            OA_rp_CS_MemAbsSet_Set_BsRt_FuelGauge_Element: operation=rp_CS_MemAbsSet.Set_BsRt_FuelGauge_Element
            OA_rp_CS_MemAbsSet_Set_BsRt_TempGauge_Element: operation=rp_CS_MemAbsSet.Set_BsRt_TempGauge_Element
            OA_rp_CS_MemAbsSet_Set_BsRt_PowerGauge_Element: operation=rp_CS_MemAbsSet.Set_BsRt_PowerGauge_Element
            OA_rp_CS_MemAbsSet_Set_BsRt_OilGauge_Element: operation=rp_CS_MemAbsSet.Set_BsRt_OilGauge_Element
            OA_rp_CS_MemAbsSet_Set_BsRt_TripComputer_Element: operation=rp_CS_MemAbsSet.Set_BsRt_TripComputer_Element
            OA_rp_CS_MemAbsSet_Set_BsRt_Warning_Element: operation=rp_CS_MemAbsSet.Set_BsRt_Warning_Element
            OA_rp_CS_MemAbsSet_Set_BsRt_RealTimeClock_Element: operation=rp_CS_MemAbsSet.Set_BsRt_RealTimeClock_Element
            OA_rp_CS_MemAbsSet_Set_BsRt_Personalization_Element: operation=rp_CS_MemAbsSet.Set_BsRt_Personalization_Element
            OA_rp_CS_MemAbsSet_Set_BsRt_Illumination_Element: operation=rp_CS_MemAbsSet.Set_BsRt_Illumination_Element
            OA_rp_CS_MemAbsSet_Set_BsRt_CusDlt_Element: operation=rp_CS_MemAbsSet.Set_BsRt_CusDlt_Element
            OA_rp_CS_MemAbsSet_Set_BsReten_Odometer_Element: operation=rp_CS_MemAbsSet.Set_BsReten_Odometer_Element
            OA_rp_CS_MemAbsSet_Set_BsReten_Gauges_Element: operation=rp_CS_MemAbsSet.Set_BsReten_Gauges_Element
            OA_rp_CS_MemAbsSet_Set_BsReten_Tripcomputer_Element: operation=rp_CS_MemAbsSet.Set_BsReten_Tripcomputer_Element
            OA_rp_CS_MemAbsSet_Set_BsReten_Illumination_Element: operation=rp_CS_MemAbsSet.Set_BsReten_Illumination_Element
            OA_rp_CS_MemAbsSet_Set_BsReten_Audio_Element: operation=rp_CS_MemAbsSet.Set_BsReten_Audio_Element
            OA_rp_CS_MemAbsSet_Set_BsReten_Warning_Element: operation=rp_CS_MemAbsSet.Set_BsReten_Warning_Element
            OA_rp_CS_MemAbsSet_Set_BsReten_RealTimeClock_Element: operation=rp_CS_MemAbsSet.Set_BsReten_RealTimeClock_Element
            OA_rp_CS_MemAbsSet_Set_BsReten_Communication_Element: operation=rp_CS_MemAbsSet.Set_BsReten_Communication_Element
            OA_rp_CS_MemAbsSet_Set_BsReten_Personalization_Element: operation=rp_CS_MemAbsSet.Set_BsReten_Personalization_Element
            OA_rp_CS_MemAbsSet_Set_BsReten_VisDlt_Element: operation=rp_CS_MemAbsSet.Set_BsReten_VisDlt_Element
            OA_rp_CS_MemAbsSet_Set_BsReten_Power_Element: operation=rp_CS_MemAbsSet.Set_BsReten_Power_Element
            OA_rp_CS_MemAbsSet_Set_BsReten_Display_Element: operation=rp_CS_MemAbsSet.Set_BsReten_Display_Element
            OA_rp_CS_MemAbsSet_Set_BsDiag_ErrorRecord_Element: operation=rp_CS_MemAbsSet.Set_BsDiag_ErrorRecord_Element
            OA_rp_CS_MemAbsSet_Set_BsDiag_Dtc_Element: operation=rp_CS_MemAbsSet.Set_BsDiag_Dtc_Element
        CMeetCdd_Impl_OnCommand
        CMeetCdd_Meet_Mgrdiagcdd_Action
        CMeetCdd_RID_DiagAction
        CMeetCdd_Read_ManufModeStatus
        CMeetCdd_Write_Mfg_Flag
  61 x constant specification:
    CMeetCddSleepReqDataValue0: value-spec=CMeetCddSleepReqDataValue0:false
    CMeetCddJobStatus_BsConst_Audio_ElementValue0: value-spec=CMeetCddJobStatus_BsConst_Audio_ElementValue0:0
    CMeetCddJobStatus_BsConst_Communication_ElementValue0: value-spec=CMeetCddJobStatus_BsConst_Communication_ElementValue0:0
    CMeetCddJobStatus_BsConst_EngOffTimer_ElementValue0: value-spec=CMeetCddJobStatus_BsConst_EngOffTimer_ElementValue0:0
    CMeetCddJobStatus_BsConst_FuelGauge_ElementValue0: value-spec=CMeetCddJobStatus_BsConst_FuelGauge_ElementValue0:0
    CMeetCddJobStatus_BsConst_Illumination_ElementValue0: value-spec=CMeetCddJobStatus_BsConst_Illumination_ElementValue0:0
    CMeetCddJobStatus_BsConst_OilGauge_ElementValue0: value-spec=CMeetCddJobStatus_BsConst_OilGauge_ElementValue0:0
    CMeetCddJobStatus_BsConst_PowerGauge_ElementValue0: value-spec=CMeetCddJobStatus_BsConst_PowerGauge_ElementValue0:0
    CMeetCddJobStatus_BsConst_Power_ElementValue0: value-spec=CMeetCddJobStatus_BsConst_Power_ElementValue0:0
    CMeetCddJobStatus_BsConst_RealTimeClock_ElementValue0: value-spec=CMeetCddJobStatus_BsConst_RealTimeClock_ElementValue0:0
    CMeetCddJobStatus_BsConst_ServiceReminder_ElementValue0: value-spec=CMeetCddJobStatus_BsConst_ServiceReminder_ElementValue0:0
    CMeetCddJobStatus_BsConst_SpeedoGauge_ElementValue0: value-spec=CMeetCddJobStatus_BsConst_SpeedoGauge_ElementValue0:0
    CMeetCddJobStatus_BsConst_TachoGauge_ElementValue0: value-spec=CMeetCddJobStatus_BsConst_TachoGauge_ElementValue0:0
    CMeetCddJobStatus_BsConst_TempGauge_ElementValue0: value-spec=CMeetCddJobStatus_BsConst_TempGauge_ElementValue0:0
    CMeetCddJobStatus_BsConst_TripComputer_ElementValue0: value-spec=CMeetCddJobStatus_BsConst_TripComputer_ElementValue0:0
    CMeetCddJobStatus_BsConst_Warning_ElementValue0: value-spec=CMeetCddJobStatus_BsConst_Warning_ElementValue0:0
    CMeetCddJobStatus_BsCys_Certicificate_ElementValue0: value-spec=CMeetCddJobStatus_BsCys_Certicificate_ElementValue0:0
    CMeetCddJobStatus_BsDiag_Dtc_ElementValue0: value-spec=CMeetCddJobStatus_BsDiag_Dtc_ElementValue0:0
    CMeetCddJobStatus_BsDiag_ErrorRecord_ElementValue0: value-spec=CMeetCddJobStatus_BsDiag_ErrorRecord_ElementValue0:0
    CMeetCddJobStatus_BsFuSa_Audio_ElementValue0: value-spec=CMeetCddJobStatus_BsFuSa_Audio_ElementValue0:0
    CMeetCddJobStatus_BsFuSa_Communication_ElementValue0: value-spec=CMeetCddJobStatus_BsFuSa_Communication_ElementValue0:0
    CMeetCddJobStatus_BsFuSa_Config_ElementValue0: value-spec=CMeetCddJobStatus_BsFuSa_Config_ElementValue0:0
    CMeetCddJobStatus_BsFuSa_Display_ElementValue0: value-spec=CMeetCddJobStatus_BsFuSa_Display_ElementValue0:0
    CMeetCddJobStatus_BsFuSa_Power_ElementValue0: value-spec=CMeetCddJobStatus_BsFuSa_Power_ElementValue0:0
    CMeetCddJobStatus_BsFuSa_Warning_ElementValue0: value-spec=CMeetCddJobStatus_BsFuSa_Warning_ElementValue0:0
    CMeetCddJobStatus_BsFusa_Fota_ElementValue0: value-spec=CMeetCddJobStatus_BsFusa_Fota_ElementValue0:0
    CMeetCddJobStatus_BsReten_Audio_ElementValue0: value-spec=CMeetCddJobStatus_BsReten_Audio_ElementValue0:0
    CMeetCddJobStatus_BsReten_Communication_ElementValue0: value-spec=CMeetCddJobStatus_BsReten_Communication_ElementValue0:0
    CMeetCddJobStatus_BsReten_Display_ElementValue0: value-spec=CMeetCddJobStatus_BsReten_Display_ElementValue0:0
    CMeetCddJobStatus_BsReten_Gauges_ElementValue0: value-spec=CMeetCddJobStatus_BsReten_Gauges_ElementValue0:0
    CMeetCddJobStatus_BsReten_Illumination_ElementValue0: value-spec=CMeetCddJobStatus_BsReten_Illumination_ElementValue0:0
    CMeetCddJobStatus_BsReten_Odometer_ElementValue0: value-spec=CMeetCddJobStatus_BsReten_Odometer_ElementValue0:0
    CMeetCddJobStatus_BsReten_Personalization_ElementValue0: value-spec=CMeetCddJobStatus_BsReten_Personalization_ElementValue0:0
    CMeetCddJobStatus_BsReten_Power_ElementValue0: value-spec=CMeetCddJobStatus_BsReten_Power_ElementValue0:0
    CMeetCddJobStatus_BsReten_RealTimeClock_ElementValue0: value-spec=CMeetCddJobStatus_BsReten_RealTimeClock_ElementValue0:0
    CMeetCddJobStatus_BsReten_Tripcomputer_ElementValue0: value-spec=CMeetCddJobStatus_BsReten_Tripcomputer_ElementValue0:0
    CMeetCddJobStatus_BsReten_VisDlt_ElementValue0: value-spec=CMeetCddJobStatus_BsReten_VisDlt_ElementValue0:0
    CMeetCddJobStatus_BsReten_Warning_ElementValue0: value-spec=CMeetCddJobStatus_BsReten_Warning_ElementValue0:0
    CMeetCddJobStatus_BsRt_CusDlt_ElementValue0: value-spec=CMeetCddJobStatus_BsRt_CusDlt_ElementValue0:0
    CMeetCddJobStatus_BsRt_FuelGauge_ElementValue0: value-spec=CMeetCddJobStatus_BsRt_FuelGauge_ElementValue0:0
    CMeetCddJobStatus_BsRt_Illumination_ElementValue0: value-spec=CMeetCddJobStatus_BsRt_Illumination_ElementValue0:0
    CMeetCddJobStatus_BsRt_Odometer_ElementValue0: value-spec=CMeetCddJobStatus_BsRt_Odometer_ElementValue0:0
    CMeetCddJobStatus_BsRt_OilGauge_ElementValue0: value-spec=CMeetCddJobStatus_BsRt_OilGauge_ElementValue0:0
    CMeetCddJobStatus_BsRt_Personalization_ElementValue0: value-spec=CMeetCddJobStatus_BsRt_Personalization_ElementValue0:0
    CMeetCddJobStatus_BsRt_PowerGauge_ElementValue0: value-spec=CMeetCddJobStatus_BsRt_PowerGauge_ElementValue0:0
    CMeetCddJobStatus_BsRt_RealTimeClock_ElementValue0: value-spec=CMeetCddJobStatus_BsRt_RealTimeClock_ElementValue0:0
    CMeetCddJobStatus_BsRt_SpeedoGauge_ElementValue0: value-spec=CMeetCddJobStatus_BsRt_SpeedoGauge_ElementValue0:0
    CMeetCddJobStatus_BsRt_TachoGauge_ElementValue0: value-spec=CMeetCddJobStatus_BsRt_TachoGauge_ElementValue0:0
    CMeetCddJobStatus_BsRt_TempGauge_ElementValue0: value-spec=CMeetCddJobStatus_BsRt_TempGauge_ElementValue0:0
    CMeetCddJobStatus_BsRt_TripComputer_ElementValue0: value-spec=CMeetCddJobStatus_BsRt_TripComputer_ElementValue0:0
    CMeetCddJobStatus_BsRt_Warning_ElementValue0: value-spec=CMeetCddJobStatus_BsRt_Warning_ElementValue0:0
    CMeetCddJobStatus_BsShare_EcuPartNumber_ElementValue0: value-spec=CMeetCddJobStatus_BsShare_EcuPartNumber_ElementValue0:0
    CMeetCddJobStatus_BsShare_SwUpdFotaFinPrint_ElementValue0: value-spec=CMeetCddJobStatus_BsShare_SwUpdFotaFinPrint_ElementValue0:0
    CMeetCddJobStatus_BsShare_SwUpdFotaMode_ElementValue0: value-spec=CMeetCddJobStatus_BsShare_SwUpdFotaMode_ElementValue0:0
    CMeetCddJobStatus_BsShare_SwUpdFotaStatus_ElementValue0: value-spec=CMeetCddJobStatus_BsShare_SwUpdFotaStatus_ElementValue0:0
    CMeetCddJobStatus_BsShare_SwUpdFotadecrypt_ElementValue0: value-spec=CMeetCddJobStatus_BsShare_SwUpdFotadecrypt_ElementValue0:0
    CMeetCddJobStatus_BsShare_SwUpdReflash_ElementValue0: value-spec=CMeetCddJobStatus_BsShare_SwUpdReflash_ElementValue0:0
    CMeetCddJobStatus_BsShare_VehicleConfig_ElementValue0: value-spec=CMeetCddJobStatus_BsShare_VehicleConfig_ElementValue0:0
    CMeetCddJobStatus_BsShare_VisMeet_ElementValue0: value-spec=CMeetCddJobStatus_BsShare_VisMeet_ElementValue0:0
    CMeetCddJobStatus_RefCys_Certicificate1_ElementValue0: value-spec=CMeetCddJobStatus_RefCys_Certicificate1_ElementValue0:0
    CMeetCddJobStatus_RefCys_Certicificate_ElementValue0: value-spec=CMeetCddJobStatus_RefCys_Certicificate_ElementValue0:0
  swc implementation IMPL_CMeetCdd: programming-language=C, behavior=IB_CMeetCdd
    code-descriptors:
      code CodeDescriptor
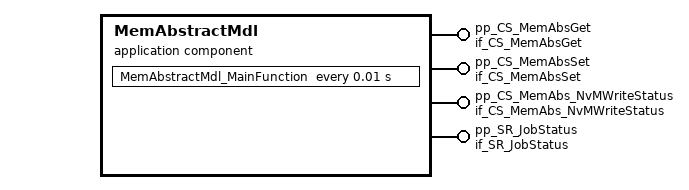
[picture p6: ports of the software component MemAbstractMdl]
  application sw component type MemAbstractMdl
    4 x provide port:
      pp_CS_MemAbsGet: provided-interface=if_CS_MemAbsGet
        provided-com-specs:
          operation=Get_BsConst_Audio_Element, queue-length=1
          operation=Get_BsConst_Communication_Element, queue-length=1
          operation=Get_BsConst_EngOffTimer_Element, queue-length=1
          operation=Get_BsConst_FuelGauge_Element, queue-length=1
          operation=Get_BsConst_Illumination_Element, queue-length=1
          operation=Get_BsConst_OilGauge_Element, queue-length=1
          operation=Get_BsConst_PowerGauge_Element, queue-length=1
          operation=Get_BsConst_Power_Element, queue-length=1
          operation=Get_BsConst_RealTimeClock_Element, queue-length=1
          operation=Get_BsConst_ServiceReminder_Element, queue-length=1
          operation=Get_BsConst_SpeedoGauge_Element, queue-length=1
          operation=Get_BsConst_TachoGauge_Element, queue-length=1
          operation=Get_BsConst_TempGauge_Element, queue-length=1
          operation=Get_BsConst_TripComputer_Element, queue-length=1
          operation=Get_BsConst_Warning_Element, queue-length=1
          operation=Get_BsCys_Certicificate_Element, queue-length=1
          operation=Get_BsDiag_Dtc_Element, queue-length=1
          operation=Get_BsDiag_ErrorRecord_Element, queue-length=1
          operation=Get_BsFuSa_Audio_Element, queue-length=1
          operation=Get_BsFuSa_Communication_Element, queue-length=1
          operation=Get_BsFuSa_Config_Element, queue-length=1
          operation=Get_BsFuSa_Display_Element, queue-length=1
          operation=Get_BsFuSa_Power_Element, queue-length=1
          operation=Get_BsFuSa_Warning_Element, queue-length=1
          operation=Get_BsFusa_Fota_Element, queue-length=1
          operation=Get_BsReten_Audio_Element, queue-length=1
          operation=Get_BsReten_Communication_Element, queue-length=1
          operation=Get_BsReten_Display_Element, queue-length=1
          operation=Get_BsReten_Gauges_Element, queue-length=1
          operation=Get_BsReten_Illumination_Element, queue-length=1
          operation=Get_BsReten_Odometer_Element, queue-length=1
          operation=Get_BsReten_Personalization_Element, queue-length=1
          operation=Get_BsReten_Power_Element, queue-length=1
          operation=Get_BsReten_RealTimeClock_Element, queue-length=1
          operation=Get_BsReten_Tripcomputer_Element, queue-length=1
          operation=Get_BsReten_VisDlt_Element, queue-length=1
          operation=Get_BsReten_Warning_Element, queue-length=1
          operation=Get_BsRt_CusDlt_Element, queue-length=1
          operation=Get_BsRt_FuelGauge_Element, queue-length=1
          operation=Get_BsRt_Illumination_Element, queue-length=1
          operation=Get_BsRt_Odometer_Element, queue-length=1
          operation=Get_BsRt_OilGauge_Element, queue-length=1
          operation=Get_BsRt_Personalization_Element, queue-length=1
          operation=Get_BsRt_PowerGauge_Element, queue-length=1
          operation=Get_BsRt_RealTimeClock_Element, queue-length=1
          operation=Get_BsRt_SpeedoGauge_Element, queue-length=1
          operation=Get_BsRt_TachoGauge_Element, queue-length=1
          operation=Get_BsRt_TempGauge_Element, queue-length=1
          operation=Get_BsRt_TripComputer_Element, queue-length=1
          operation=Get_BsRt_Warning_Element, queue-length=1
          operation=Get_BsShare_EcuPartNumber_Element, queue-length=1
          operation=Get_BsShare_SwUpdFotaFinPrint_Element, queue-length=1
          operation=Get_BsShare_SwUpdFotaMode_Element, queue-length=1
          operation=Get_BsShare_SwUpdFotaStatus_Element, queue-length=1
          operation=Get_BsShare_SwUpdFotadecrypt_Element, queue-length=1
          operation=Get_BsShare_SwUpdReflash_Element, queue-length=1
          operation=Get_BsShare_VehicleConfig_Element, queue-length=1
          operation=Get_BsShare_VisMeet_Element, queue-length=1
          operation=Get_RefCys_Certicificate1_Element, queue-length=1
          operation=Get_RefCys_Certicificate_Element, queue-length=1
      pp_CS_MemAbsSet: provided-interface=if_CS_MemAbsSet
        provided-com-specs:
          operation=Set_BsConst_Audio_Element, queue-length=1
          operation=Set_BsConst_Communication_Element, queue-length=1
          operation=Set_BsConst_EngOffTimer_Element, queue-length=1
          operation=Set_BsConst_FuelGauge_Element, queue-length=1
          operation=Set_BsConst_Illumination_Element, queue-length=1
          operation=Set_BsConst_OilGauge_Element, queue-length=1
          operation=Set_BsConst_PowerGauge_Element, queue-length=1
          operation=Set_BsConst_Power_Element, queue-length=1
          operation=Set_BsConst_RealTimeClock_Element, queue-length=1
          operation=Set_BsConst_ServiceReminder_Element, queue-length=1
          operation=Set_BsConst_SpeedoGauge_Element, queue-length=1
          operation=Set_BsConst_TachoGauge_Element, queue-length=1
          operation=Set_BsConst_TempGauge_Element, queue-length=1
          operation=Set_BsConst_TripComputer_Element, queue-length=1
          operation=Set_BsConst_Warning_Element, queue-length=1
          operation=Set_BsCys_Certicificate_Element, queue-length=1
          operation=Set_BsDiag_Dtc_Element, queue-length=1
          operation=Set_BsDiag_ErrorRecord_Element, queue-length=1
          operation=Set_BsFuSa_Audio_Element, queue-length=1
          operation=Set_BsFuSa_Communication_Element, queue-length=1
          operation=Set_BsFuSa_Config_Element, queue-length=1
          operation=Set_BsFuSa_Display_Element, queue-length=1
          operation=Set_BsFuSa_Power_Element, queue-length=1
          operation=Set_BsFuSa_Warning_Element, queue-length=1
          operation=Set_BsFusa_Fota_Element, queue-length=1
          operation=Set_BsReten_Audio_Element, queue-length=1
          operation=Set_BsReten_Communication_Element, queue-length=1
          operation=Set_BsReten_Display_Element, queue-length=1
          operation=Set_BsReten_Gauges_Element, queue-length=1
          operation=Set_BsReten_Illumination_Element, queue-length=1
          operation=Set_BsReten_Odometer_Element, queue-length=1
          operation=Set_BsReten_Personalization_Element, queue-length=1
          operation=Set_BsReten_Power_Element, queue-length=1
          operation=Set_BsReten_RealTimeClock_Element, queue-length=1
          operation=Set_BsReten_Tripcomputer_Element, queue-length=1
          operation=Set_BsReten_VisDlt_Element, queue-length=1
          operation=Set_BsReten_Warning_Element, queue-length=1
          operation=Set_BsRt_CusDlt_Element, queue-length=1
          operation=Set_BsRt_FuelGauge_Element, queue-length=1
          operation=Set_BsRt_Illumination_Element, queue-length=1
          operation=Set_BsRt_Odometer_Element, queue-length=1
          operation=Set_BsRt_OilGauge_Element, queue-length=1
          operation=Set_BsRt_Personalization_Element, queue-length=1
          operation=Set_BsRt_PowerGauge_Element, queue-length=1
          operation=Set_BsRt_RealTimeClock_Element, queue-length=1
          operation=Set_BsRt_SpeedoGauge_Element, queue-length=1
          operation=Set_BsRt_TachoGauge_Element, queue-length=1
          operation=Set_BsRt_TempGauge_Element, queue-length=1
          operation=Set_BsRt_TripComputer_Element, queue-length=1
          operation=Set_BsRt_Warning_Element, queue-length=1
          operation=Set_BsShare_EcuPartNumber_Element, queue-length=1
          operation=Set_BsShare_SwUpdFotaFinPrint_Element, queue-length=1
          operation=Set_BsShare_SwUpdFotaMode_Element, queue-length=1
          operation=Set_BsShare_SwUpdFotaStatus_Element, queue-length=1
          operation=Set_BsShare_SwUpdFotadecrypt_Element, queue-length=1
          operation=Set_BsShare_SwUpdReflash_Element, queue-length=1
          operation=Set_BsShare_VehicleConfig_Element, queue-length=1
          operation=Set_BsShare_VisMeet_Element, queue-length=1
          operation=Set_RefCys_Certicificate1_Element, queue-length=1
          operation=Set_RefCys_Certicificate_Element, queue-length=1
      pp_CS_MemAbs_NvMWriteStatus: server-com-spec{operation=NvmWriteStatus, queue-length=1}, provided-interface=if_CS_MemAbs_NvMWriteStatus
      pp_SR_JobStatus: provided-interface=if_SR_JobStatus
        provided-com-specs:
          data-element=JobStatus_BsConst_Audio_Element, init-value=constant-reference=MemAbstractMdlJobStatus_BsConst_Audio_ElementValue0
          data-element=JobStatus_BsConst_Communication_Element, init-value=constant-reference=MemAbstractMdlJobStatus_BsConst_Communication_ElementValue0
          data-element=JobStatus_BsConst_EngOffTimer_Element, init-value=constant-reference=MemAbstractMdlJobStatus_BsConst_EngOffTimer_ElementValue0
          data-element=JobStatus_BsConst_FuelGauge_Element, init-value=constant-reference=MemAbstractMdlJobStatus_BsConst_FuelGauge_ElementValue0
          data-element=JobStatus_BsConst_Illumination_Element, init-value=constant-reference=MemAbstractMdlJobStatus_BsConst_Illumination_ElementValue0
          data-element=JobStatus_BsConst_OilGauge_Element, init-value=constant-reference=MemAbstractMdlJobStatus_BsConst_OilGauge_ElementValue0
          data-element=JobStatus_BsConst_PowerGauge_Element, init-value=constant-reference=MemAbstractMdlJobStatus_BsConst_PowerGauge_ElementValue0
          data-element=JobStatus_BsConst_Power_Element, init-value=constant-reference=MemAbstractMdlJobStatus_BsConst_Power_ElementValue0
          data-element=JobStatus_BsConst_RealTimeClock_Element, init-value=constant-reference=MemAbstractMdlJobStatus_BsConst_RealTimeClock_ElementValue0
          data-element=JobStatus_BsConst_ServiceReminder_Element, init-value=constant-reference=MemAbstractMdlJobStatus_BsConst_ServiceReminder_ElementValue0
          data-element=JobStatus_BsConst_SpeedoGauge_Element, init-value=constant-reference=MemAbstractMdlJobStatus_BsConst_SpeedoGauge_ElementValue0
          data-element=JobStatus_BsConst_TachoGauge_Element, init-value=constant-reference=MemAbstractMdlJobStatus_BsConst_TachoGauge_ElementValue0
          data-element=JobStatus_BsConst_TempGauge_Element, init-value=constant-reference=MemAbstractMdlJobStatus_BsConst_TempGauge_ElementValue0
          data-element=JobStatus_BsConst_TripComputer_Element, init-value=constant-reference=MemAbstractMdlJobStatus_BsConst_TripComputer_ElementValue0
          data-element=JobStatus_BsConst_Warning_Element, init-value=constant-reference=MemAbstractMdlJobStatus_BsConst_Warning_ElementValue0
          data-element=JobStatus_BsCys_Certicificate_Element, init-value=constant-reference=MemAbstractMdlJobStatus_BsCys_Certicificate_ElementValue0
          data-element=JobStatus_BsDiag_Dtc_Element, init-value=constant-reference=MemAbstractMdlJobStatus_BsDiag_Dtc_ElementValue0
          data-element=JobStatus_BsDiag_ErrorRecord_Element, init-value=constant-reference=MemAbstractMdlJobStatus_BsDiag_ErrorRecord_ElementValue0
          data-element=JobStatus_BsFuSa_Audio_Element, init-value=constant-reference=MemAbstractMdlJobStatus_BsFuSa_Audio_ElementValue0
          data-element=JobStatus_BsFuSa_Communication_Element, init-value=constant-reference=MemAbstractMdlJobStatus_BsFuSa_Communication_ElementValue0
          data-element=JobStatus_BsFuSa_Config_Element, init-value=constant-reference=MemAbstractMdlJobStatus_BsFuSa_Config_ElementValue0
          data-element=JobStatus_BsFuSa_Display_Element, init-value=constant-reference=MemAbstractMdlJobStatus_BsFuSa_Display_ElementValue0
          data-element=JobStatus_BsFuSa_Power_Element, init-value=constant-reference=MemAbstractMdlJobStatus_BsFuSa_Power_ElementValue0
          data-element=JobStatus_BsFuSa_Warning_Element, init-value=constant-reference=MemAbstractMdlJobStatus_BsFuSa_Warning_ElementValue0
          data-element=JobStatus_BsFusa_Fota_Element, init-value=constant-reference=MemAbstractMdlJobStatus_BsFusa_Fota_ElementValue0
          data-element=JobStatus_BsReten_Audio_Element, init-value=constant-reference=MemAbstractMdlJobStatus_BsReten_Audio_ElementValue0
          data-element=JobStatus_BsReten_Communication_Element, init-value=constant-reference=MemAbstractMdlJobStatus_BsReten_Communication_ElementValue0
          data-element=JobStatus_BsReten_Display_Element, init-value=constant-reference=MemAbstractMdlJobStatus_BsReten_Display_ElementValue0
          data-element=JobStatus_BsReten_Gauges_Element, init-value=constant-reference=MemAbstractMdlJobStatus_BsReten_Gauges_ElementValue0
          data-element=JobStatus_BsReten_Illumination_Element, init-value=constant-reference=MemAbstractMdlJobStatus_BsReten_Illumination_ElementValue0
          data-element=JobStatus_BsReten_Odometer_Element, init-value=constant-reference=MemAbstractMdlJobStatus_BsReten_Odometer_ElementValue0
          data-element=JobStatus_BsReten_Personalization_Element, init-value=constant-reference=MemAbstractMdlJobStatus_BsReten_Personalization_ElementValue0
          data-element=JobStatus_BsReten_Power_Element, init-value=constant-reference=MemAbstractMdlJobStatus_BsReten_Power_ElementValue0
          data-element=JobStatus_BsReten_RealTimeClock_Element, init-value=constant-reference=MemAbstractMdlJobStatus_BsReten_RealTimeClock_ElementValue0
          data-element=JobStatus_BsReten_Tripcomputer_Element, init-value=constant-reference=MemAbstractMdlJobStatus_BsReten_Tripcomputer_ElementValue0
          data-element=JobStatus_BsReten_VisDlt_Element, init-value=constant-reference=MemAbstractMdlJobStatus_BsReten_VisDlt_ElementValue0
          data-element=JobStatus_BsReten_Warning_Element, init-value=constant-reference=MemAbstractMdlJobStatus_BsReten_Warning_ElementValue0
          data-element=JobStatus_BsRt_CusDlt_Element, init-value=constant-reference=MemAbstractMdlJobStatus_BsRt_CusDlt_ElementValue0
          data-element=JobStatus_BsRt_FuelGauge_Element, init-value=constant-reference=MemAbstractMdlJobStatus_BsRt_FuelGauge_ElementValue0
          data-element=JobStatus_BsRt_Illumination_Element, init-value=constant-reference=MemAbstractMdlJobStatus_BsRt_Illumination_ElementValue0
          data-element=JobStatus_BsRt_Odometer_Element, init-value=constant-reference=MemAbstractMdlJobStatus_BsRt_Odometer_ElementValue0
          data-element=JobStatus_BsRt_OilGauge_Element, init-value=constant-reference=MemAbstractMdlJobStatus_BsRt_OilGauge_ElementValue0
          data-element=JobStatus_BsRt_Personalization_Element, init-value=constant-reference=MemAbstractMdlJobStatus_BsRt_Personalization_ElementValue0
          data-element=JobStatus_BsRt_PowerGauge_Element, init-value=constant-reference=MemAbstractMdlJobStatus_BsRt_PowerGauge_ElementValue0
          data-element=JobStatus_BsRt_RealTimeClock_Element, init-value=constant-reference=MemAbstractMdlJobStatus_BsRt_RealTimeClock_ElementValue0
          data-element=JobStatus_BsRt_SpeedoGauge_Element, init-value=constant-reference=MemAbstractMdlJobStatus_BsRt_SpeedoGauge_ElementValue0
          data-element=JobStatus_BsRt_TachoGauge_Element, init-value=constant-reference=MemAbstractMdlJobStatus_BsRt_TachoGauge_ElementValue0
          data-element=JobStatus_BsRt_TempGauge_Element, init-value=constant-reference=MemAbstractMdlJobStatus_BsRt_TempGauge_ElementValue0
          data-element=JobStatus_BsRt_TripComputer_Element, init-value=constant-reference=MemAbstractMdlJobStatus_BsRt_TripComputer_ElementValue0
          data-element=JobStatus_BsRt_Warning_Element, init-value=constant-reference=MemAbstractMdlJobStatus_BsRt_Warning_ElementValue0
          data-element=JobStatus_BsShare_EcuPartNumber_Element, init-value=constant-reference=MemAbstractMdlJobStatus_BsShare_EcuPartNumber_ElementValue0
          data-element=JobStatus_BsShare_SwUpdFotaFinPrint_Element, init-value=constant-reference=MemAbstractMdlJobStatus_BsShare_SwUpdFotaFinPrint_ElementValue0
          data-element=JobStatus_BsShare_SwUpdFotaMode_Element, init-value=constant-reference=MemAbstractMdlJobStatus_BsShare_SwUpdFotaMode_ElementValue0
          data-element=JobStatus_BsShare_SwUpdFotaStatus_Element, init-value=constant-reference=MemAbstractMdlJobStatus_BsShare_SwUpdFotaStatus_ElementValue0
          data-element=JobStatus_BsShare_SwUpdFotadecrypt_Element, init-value=constant-reference=MemAbstractMdlJobStatus_BsShare_SwUpdFotadecrypt_ElementValue0
          data-element=JobStatus_BsShare_SwUpdReflash_Element, init-value=constant-reference=MemAbstractMdlJobStatus_BsShare_SwUpdReflash_ElementValue0
          data-element=JobStatus_BsShare_VehicleConfig_Element, init-value=constant-reference=MemAbstractMdlJobStatus_BsShare_VehicleConfig_ElementValue0
          data-element=JobStatus_BsShare_VisMeet_Element, init-value=constant-reference=MemAbstractMdlJobStatus_BsShare_VisMeet_ElementValue0
          data-element=JobStatus_RefCys_Certicificate1_Element, init-value=constant-reference=MemAbstractMdlJobStatus_RefCys_Certicificate1_ElementValue0
          data-element=JobStatus_RefCys_Certicificate_Element, init-value=constant-reference=MemAbstractMdlJobStatus_RefCys_Certicificate_ElementValue0
    behavior IB_MemAbstractMdl
      60 x operation invoked event:
        OIE_pp_CS_MemAbsGet_MemAbstractMdl_Get_BsConst_Audio_ElementTrigByGet_BsConst_Audio_Element: start-on-event=MemAbstractMdl_Get_BsConst_Audio_Element, operation=pp_CS_MemAbsGet.Get_BsConst_Audio_Element
        OIE_pp_CS_MemAbsGet_MemAbstractMdl_Get_BsConst_Communication_ElementTrigByGet_BsConst_Communication_Element: start-on-event=MemAbstractMdl_Get_BsConst_Communication_Element, operation=pp_CS_MemAbsGet.Get_BsConst_Communication_Element
        OIE_pp_CS_MemAbsGet_MemAbstractMdl_Get_BsConst_EngOffTimer_ElementTrigByGet_BsConst_EngOffTimer_Element: start-on-event=MemAbstractMdl_Get_BsConst_EngOffTimer_Element, operation=pp_CS_MemAbsGet.Get_BsConst_EngOffTimer_Element
        OIE_pp_CS_MemAbsGet_MemAbstractMdl_Get_BsConst_FuelGauge_ElementTrigByGet_BsConst_FuelGauge_Element: start-on-event=MemAbstractMdl_Get_BsConst_FuelGauge_Element, operation=pp_CS_MemAbsGet.Get_BsConst_FuelGauge_Element
        OIE_pp_CS_MemAbsGet_MemAbstractMdl_Get_BsConst_Illumination_ElementTrigByGet_BsConst_Illumination_Element: start-on-event=MemAbstractMdl_Get_BsConst_Illumination_Element, operation=pp_CS_MemAbsGet.Get_BsConst_Illumination_Element
        OIE_pp_CS_MemAbsGet_MemAbstractMdl_Get_BsConst_OilGauge_ElementTrigByGet_BsConst_OilGauge_Element: start-on-event=MemAbstractMdl_Get_BsConst_OilGauge_Element, operation=pp_CS_MemAbsGet.Get_BsConst_OilGauge_Element
        OIE_pp_CS_MemAbsGet_MemAbstractMdl_Get_BsConst_PowerGauge_ElementTrigByGet_BsConst_PowerGauge_Element: start-on-event=MemAbstractMdl_Get_BsConst_PowerGauge_Element, operation=pp_CS_MemAbsGet.Get_BsConst_PowerGauge_Element
        OIE_pp_CS_MemAbsGet_MemAbstractMdl_Get_BsConst_Power_ElementTrigByGet_BsConst_Power_Element: start-on-event=MemAbstractMdl_Get_BsConst_Power_Element, operation=pp_CS_MemAbsGet.Get_BsConst_Power_Element
        OIE_pp_CS_MemAbsGet_MemAbstractMdl_Get_BsConst_RealTimeClock_ElementTrigByGet_BsConst_RealTimeClock_Element: start-on-event=MemAbstractMdl_Get_BsConst_RealTimeClock_Element, operation=pp_CS_MemAbsGet.Get_BsConst_RealTimeClock_Element
        OIE_pp_CS_MemAbsGet_MemAbstractMdl_Get_BsConst_ServiceReminder_ElementTrigByGet_BsConst_ServiceReminder_Element: start-on-event=MemAbstractMdl_Get_BsConst_ServiceReminder_Element, operation=pp_CS_MemAbsGet.Get_BsConst_ServiceReminder_Element
        OIE_pp_CS_MemAbsGet_MemAbstractMdl_Get_BsConst_SpeedoGauge_ElementTrigByGet_BsConst_SpeedoGauge_Element: start-on-event=MemAbstractMdl_Get_BsConst_SpeedoGauge_Element, operation=pp_CS_MemAbsGet.Get_BsConst_SpeedoGauge_Element
        OIE_pp_CS_MemAbsGet_MemAbstractMdl_Get_BsConst_TachoGauge_ElementTrigByGet_BsConst_TachoGauge_Element: start-on-event=MemAbstractMdl_Get_BsConst_TachoGauge_Element, operation=pp_CS_MemAbsGet.Get_BsConst_TachoGauge_Element
        OIE_pp_CS_MemAbsGet_MemAbstractMdl_Get_BsConst_TempGauge_ElementTrigByGet_BsConst_TempGauge_Element: start-on-event=MemAbstractMdl_Get_BsConst_TempGauge_Element, operation=pp_CS_MemAbsGet.Get_BsConst_TempGauge_Element
        OIE_pp_CS_MemAbsGet_MemAbstractMdl_Get_BsConst_TripComputer_ElementTrigByGet_BsConst_TripComputer_Element: start-on-event=MemAbstractMdl_Get_BsConst_TripComputer_Element, operation=pp_CS_MemAbsGet.Get_BsConst_TripComputer_Element
        OIE_pp_CS_MemAbsGet_MemAbstractMdl_Get_BsConst_Warning_ElementTrigByGet_BsConst_Warning_Element: start-on-event=MemAbstractMdl_Get_BsConst_Warning_Element, operation=pp_CS_MemAbsGet.Get_BsConst_Warning_Element
        OIE_pp_CS_MemAbsGet_MemAbstractMdl_Get_BsCys_Certicificate_ElementTrigByGet_BsCys_Certicificate_Element: start-on-event=MemAbstractMdl_Get_BsCys_Certicificate_Element, operation=pp_CS_MemAbsGet.Get_BsCys_Certicificate_Element
        OIE_pp_CS_MemAbsGet_MemAbstractMdl_Get_BsDiag_Dtc_ElementTrigByGet_BsDiag_Dtc_Element: start-on-event=MemAbstractMdl_Get_BsDiag_Dtc_Element, operation=pp_CS_MemAbsGet.Get_BsDiag_Dtc_Element
        OIE_pp_CS_MemAbsGet_MemAbstractMdl_Get_BsDiag_ErrorRecord_ElementTrigByGet_BsDiag_ErrorRecord_Element: start-on-event=MemAbstractMdl_Get_BsDiag_ErrorRecord_Element, operation=pp_CS_MemAbsGet.Get_BsDiag_ErrorRecord_Element
        OIE_pp_CS_MemAbsGet_MemAbstractMdl_Get_BsFuSa_Audio_ElementTrigByGet_BsFuSa_Audio_Element: start-on-event=MemAbstractMdl_Get_BsFuSa_Audio_Element, operation=pp_CS_MemAbsGet.Get_BsFuSa_Audio_Element
        OIE_pp_CS_MemAbsGet_MemAbstractMdl_Get_BsFuSa_Communication_ElementTrigByGet_BsFuSa_Communication_Element: start-on-event=MemAbstractMdl_Get_BsFuSa_Communication_Element, operation=pp_CS_MemAbsGet.Get_BsFuSa_Communication_Element
        OIE_pp_CS_MemAbsGet_MemAbstractMdl_Get_BsFuSa_Config_ElementTrigByGet_BsFuSa_Config_Element: start-on-event=MemAbstractMdl_Get_BsFuSa_Config_Element, operation=pp_CS_MemAbsGet.Get_BsFuSa_Config_Element
        OIE_pp_CS_MemAbsGet_MemAbstractMdl_Get_BsFuSa_Display_ElementTrigByGet_BsFuSa_Display_Element: start-on-event=MemAbstractMdl_Get_BsFuSa_Display_Element, operation=pp_CS_MemAbsGet.Get_BsFuSa_Display_Element
        OIE_pp_CS_MemAbsGet_MemAbstractMdl_Get_BsFuSa_Power_ElementTrigByGet_BsFuSa_Power_Element: start-on-event=MemAbstractMdl_Get_BsFuSa_Power_Element, operation=pp_CS_MemAbsGet.Get_BsFuSa_Power_Element
        OIE_pp_CS_MemAbsGet_MemAbstractMdl_Get_BsFuSa_Warning_ElementTrigByGet_BsFuSa_Warning_Element: start-on-event=MemAbstractMdl_Get_BsFuSa_Warning_Element, operation=pp_CS_MemAbsGet.Get_BsFuSa_Warning_Element
        OIE_pp_CS_MemAbsGet_MemAbstractMdl_Get_BsFusa_Fota_ElementTrigByGet_BsFusa_Fota_Element: start-on-event=MemAbstractMdl_Get_BsFusa_Fota_Element, operation=pp_CS_MemAbsGet.Get_BsFusa_Fota_Element
        OIE_pp_CS_MemAbsGet_MemAbstractMdl_Get_BsReten_Audio_ElementTrigByGet_BsReten_Audio_Element: start-on-event=MemAbstractMdl_Get_BsReten_Audio_Element, operation=pp_CS_MemAbsGet.Get_BsReten_Audio_Element
        OIE_pp_CS_MemAbsGet_MemAbstractMdl_Get_BsReten_Communication_ElementTrigByGet_BsReten_Communication_Element: start-on-event=MemAbstractMdl_Get_BsReten_Communication_Element, operation=pp_CS_MemAbsGet.Get_BsReten_Communication_Element
        OIE_pp_CS_MemAbsGet_MemAbstractMdl_Get_BsReten_Display_ElementTrigByGet_BsReten_Display_Element: start-on-event=MemAbstractMdl_Get_BsReten_Display_Element, operation=pp_CS_MemAbsGet.Get_BsReten_Display_Element
        OIE_pp_CS_MemAbsGet_MemAbstractMdl_Get_BsReten_Gauges_ElementTrigByGet_BsReten_Gauges_Element: start-on-event=MemAbstractMdl_Get_BsReten_Gauges_Element, operation=pp_CS_MemAbsGet.Get_BsReten_Gauges_Element
        OIE_pp_CS_MemAbsGet_MemAbstractMdl_Get_BsReten_Illumination_ElementTrigByGet_BsReten_Illumination_Element: start-on-event=MemAbstractMdl_Get_BsReten_Illumination_Element, operation=pp_CS_MemAbsGet.Get_BsReten_Illumination_Element
        OIE_pp_CS_MemAbsGet_MemAbstractMdl_Get_BsReten_Odometer_ElementTrigByGet_BsReten_Odometer_Element: start-on-event=MemAbstractMdl_Get_BsReten_Odometer_Element, operation=pp_CS_MemAbsGet.Get_BsReten_Odometer_Element
        OIE_pp_CS_MemAbsGet_MemAbstractMdl_Get_BsReten_Personalization_ElementTrigByGet_BsReten_Personalization_Element: start-on-event=MemAbstractMdl_Get_BsReten_Personalization_Element, operation=pp_CS_MemAbsGet.Get_BsReten_Personalization_Element
        OIE_pp_CS_MemAbsGet_MemAbstractMdl_Get_BsReten_Power_ElementTrigByGet_BsReten_Power_Element: start-on-event=MemAbstractMdl_Get_BsReten_Power_Element, operation=pp_CS_MemAbsGet.Get_BsReten_Power_Element
        OIE_pp_CS_MemAbsGet_MemAbstractMdl_Get_BsReten_RealTimeClock_ElementTrigByGet_BsReten_RealTimeClock_Element: start-on-event=MemAbstractMdl_Get_BsReten_RealTimeClock_Element, operation=pp_CS_MemAbsGet.Get_BsReten_RealTimeClock_Element
        OIE_pp_CS_MemAbsGet_MemAbstractMdl_Get_BsReten_Tripcomputer_ElementTrigByGet_BsReten_Tripcomputer_Element: start-on-event=MemAbstractMdl_Get_BsReten_Tripcomputer_Element, operation=pp_CS_MemAbsGet.Get_BsReten_Tripcomputer_Element
        OIE_pp_CS_MemAbsGet_MemAbstractMdl_Get_BsReten_VisDlt_ElementTrigByGet_BsReten_VisDlt_Element: start-on-event=MemAbstractMdl_Get_BsReten_VisDlt_Element, operation=pp_CS_MemAbsGet.Get_BsReten_VisDlt_Element
        OIE_pp_CS_MemAbsGet_MemAbstractMdl_Get_BsReten_Warning_ElementTrigByGet_BsReten_Warning_Element: start-on-event=MemAbstractMdl_Get_BsReten_Warning_Element, operation=pp_CS_MemAbsGet.Get_BsReten_Warning_Element
        OIE_pp_CS_MemAbsGet_MemAbstractMdl_Get_BsRt_CusDlt_ElementTrigByGet_BsRt_CusDlt_Element: start-on-event=MemAbstractMdl_Get_BsRt_CusDlt_Element, operation=pp_CS_MemAbsGet.Get_BsRt_CusDlt_Element
        OIE_pp_CS_MemAbsGet_MemAbstractMdl_Get_BsRt_FuelGauge_ElementTrigByGet_BsRt_FuelGauge_Element: start-on-event=MemAbstractMdl_Get_BsRt_FuelGauge_Element, operation=pp_CS_MemAbsGet.Get_BsRt_FuelGauge_Element
        OIE_pp_CS_MemAbsGet_MemAbstractMdl_Get_BsRt_Illumination_ElementTrigByGet_BsRt_Illumination_Element: start-on-event=MemAbstractMdl_Get_BsRt_Illumination_Element, operation=pp_CS_MemAbsGet.Get_BsRt_Illumination_Element
        OIE_pp_CS_MemAbsGet_MemAbstractMdl_Get_BsRt_Odometer_ElementTrigByGet_BsRt_Odometer_Element: start-on-event=MemAbstractMdl_Get_BsRt_Odometer_Element, operation=pp_CS_MemAbsGet.Get_BsRt_Odometer_Element
        OIE_pp_CS_MemAbsGet_MemAbstractMdl_Get_BsRt_OilGauge_ElementTrigByGet_BsRt_OilGauge_Element: start-on-event=MemAbstractMdl_Get_BsRt_OilGauge_Element, operation=pp_CS_MemAbsGet.Get_BsRt_OilGauge_Element
        OIE_pp_CS_MemAbsGet_MemAbstractMdl_Get_BsRt_Personalization_ElementTrigByGet_BsRt_Personalization_Element: start-on-event=MemAbstractMdl_Get_BsRt_Personalization_Element, operation=pp_CS_MemAbsGet.Get_BsRt_Personalization_Element
        OIE_pp_CS_MemAbsGet_MemAbstractMdl_Get_BsRt_PowerGauge_ElementTrigByGet_BsRt_PowerGauge_Element: start-on-event=MemAbstractMdl_Get_BsRt_PowerGauge_Element, operation=pp_CS_MemAbsGet.Get_BsRt_PowerGauge_Element
        OIE_pp_CS_MemAbsGet_MemAbstractMdl_Get_BsRt_RealTimeClock_ElementTrigByGet_BsRt_RealTimeClock_Element: start-on-event=MemAbstractMdl_Get_BsRt_RealTimeClock_Element, operation=pp_CS_MemAbsGet.Get_BsRt_RealTimeClock_Element
        OIE_pp_CS_MemAbsGet_MemAbstractMdl_Get_BsRt_SpeedoGauge_ElementTrigByGet_BsRt_SpeedoGauge_Element: start-on-event=MemAbstractMdl_Get_BsRt_SpeedoGauge_Element, operation=pp_CS_MemAbsGet.Get_BsRt_SpeedoGauge_Element
        OIE_pp_CS_MemAbsGet_MemAbstractMdl_Get_BsRt_TachoGauge_ElementTrigByGet_BsRt_TachoGauge_Element: start-on-event=MemAbstractMdl_Get_BsRt_TachoGauge_Element, operation=pp_CS_MemAbsGet.Get_BsRt_TachoGauge_Element
        OIE_pp_CS_MemAbsGet_MemAbstractMdl_Get_BsRt_TempGauge_ElementTrigByGet_BsRt_TempGauge_Element: start-on-event=MemAbstractMdl_Get_BsRt_TempGauge_Element, operation=pp_CS_MemAbsGet.Get_BsRt_TempGauge_Element
        OIE_pp_CS_MemAbsGet_MemAbstractMdl_Get_BsRt_TripComputer_ElementTrigByGet_BsRt_TripComputer_Element: start-on-event=MemAbstractMdl_Get_BsRt_TripComputer_Element, operation=pp_CS_MemAbsGet.Get_BsRt_TripComputer_Element
        OIE_pp_CS_MemAbsGet_MemAbstractMdl_Get_BsRt_Warning_ElementTrigByGet_BsRt_Warning_Element: start-on-event=MemAbstractMdl_Get_BsRt_Warning_Element, operation=pp_CS_MemAbsGet.Get_BsRt_Warning_Element
        OIE_pp_CS_MemAbsGet_MemAbstractMdl_Get_BsShare_EcuPartNumber_ElementTrigByGet_BsShare_EcuPartNumber_Element: start-on-event=MemAbstractMdl_Get_BsShare_EcuPartNumber_Element, operation=pp_CS_MemAbsGet.Get_BsShare_EcuPartNumber_Element
        OIE_pp_CS_MemAbsGet_MemAbstractMdl_Get_BsShare_SwUpdFotaFinPrint_ElementTrigByGet_BsShare_SwUpdFotaFinPrint_Element: start-on-event=MemAbstractMdl_Get_BsShare_SwUpdFotaFinPrint_Element, operation=pp_CS_MemAbsGet.Get_BsShare_SwUpdFotaFinPrint_Element
        OIE_pp_CS_MemAbsGet_MemAbstractMdl_Get_BsShare_SwUpdFotaMode_ElementTrigByGet_BsShare_SwUpdFotaMode_Element: start-on-event=MemAbstractMdl_Get_BsShare_SwUpdFotaMode_Element, operation=pp_CS_MemAbsGet.Get_BsShare_SwUpdFotaMode_Element
        OIE_pp_CS_MemAbsGet_MemAbstractMdl_Get_BsShare_SwUpdFotaStatus_ElementTrigByGet_BsShare_SwUpdFotaStatus_Element: start-on-event=MemAbstractMdl_Get_BsShare_SwUpdFotaStatus_Element, operation=pp_CS_MemAbsGet.Get_BsShare_SwUpdFotaStatus_Element
        OIE_pp_CS_MemAbsGet_MemAbstractMdl_Get_BsShare_SwUpdFotadecrypt_ElementTrigByGet_BsShare_SwUpdFotadecrypt_Element: start-on-event=MemAbstractMdl_Get_BsShare_SwUpdFotadecrypt_Element, operation=pp_CS_MemAbsGet.Get_BsShare_SwUpdFotadecrypt_Element
        OIE_pp_CS_MemAbsGet_MemAbstractMdl_Get_BsShare_SwUpdReflash_ElementTrigByGet_BsShare_SwUpdReflash_Element: start-on-event=MemAbstractMdl_Get_BsShare_SwUpdReflash_Element, operation=pp_CS_MemAbsGet.Get_BsShare_SwUpdReflash_Element
        OIE_pp_CS_MemAbsGet_MemAbstractMdl_Get_BsShare_VehicleConfig_ElementTrigByGet_BsShare_VehicleConfig_Element: start-on-event=MemAbstractMdl_Get_BsShare_VehicleConfig_Element, operation=pp_CS_MemAbsGet.Get_BsShare_VehicleConfig_Element
        OIE_pp_CS_MemAbsGet_MemAbstractMdl_Get_BsShare_VisMeet_ElementTrigByGet_BsShare_VisMeet_Element: start-on-event=MemAbstractMdl_Get_BsShare_VisMeet_Element, operation=pp_CS_MemAbsGet.Get_BsShare_VisMeet_Element
        OIE_pp_CS_MemAbsGet_MemAbstractMdl_Get_RefCys_Certicificate1_ElementTrigByGet_RefCys_Certicificate1_Element: start-on-event=MemAbstractMdl_Get_RefCys_Certicificate1_Element, operation=pp_CS_MemAbsGet.Get_RefCys_Certicificate1_Element
        OIE_pp_CS_MemAbsGet_MemAbstractMdl_Get_RefCys_Certicificate_ElementTrigByGet_RefCys_Certicificate_Element: start-on-event=MemAbstractMdl_Get_RefCys_Certicificate_Element, operation=pp_CS_MemAbsGet.Get_RefCys_Certicificate_Element
      timing event TEMemAbstractMdl_MainFunction: start-on-event=MemAbstractMdl_MainFunction, period=0.01
      61 x operation invoked event:
        OIE_pp_CS_MemAbs_NvMWriteStatus_MemAbstractMdl_NvmWriteStatusTrigByNvmWriteStatus: start-on-event=MemAbstractMdl_NvmWriteStatus, operation=pp_CS_MemAbs_NvMWriteStatus.NvmWriteStatus
        OIE_pp_CS_MemAbsSet_MemAbstractMdl_Set_BsConst_Audio_ElementTrigBySet_BsConst_Audio_Element: start-on-event=MemAbstractMdl_Set_BsConst_Audio_Element, operation=pp_CS_MemAbsSet.Set_BsConst_Audio_Element
        OIE_pp_CS_MemAbsSet_MemAbstractMdl_Set_BsConst_Communication_ElementTrigBySet_BsConst_Communication_Element: start-on-event=MemAbstractMdl_Set_BsConst_Communication_Element, operation=pp_CS_MemAbsSet.Set_BsConst_Communication_Element
        OIE_pp_CS_MemAbsSet_MemAbstractMdl_Set_BsConst_EngOffTimer_ElementTrigBySet_BsConst_EngOffTimer_Element: start-on-event=MemAbstractMdl_Set_BsConst_EngOffTimer_Element, operation=pp_CS_MemAbsSet.Set_BsConst_EngOffTimer_Element
        OIE_pp_CS_MemAbsSet_MemAbstractMdl_Set_BsConst_FuelGauge_ElementTrigBySet_BsConst_FuelGauge_Element: start-on-event=MemAbstractMdl_Set_BsConst_FuelGauge_Element, operation=pp_CS_MemAbsSet.Set_BsConst_FuelGauge_Element
        OIE_pp_CS_MemAbsSet_MemAbstractMdl_Set_BsConst_Illumination_ElementTrigBySet_BsConst_Illumination_Element: start-on-event=MemAbstractMdl_Set_BsConst_Illumination_Element, operation=pp_CS_MemAbsSet.Set_BsConst_Illumination_Element
        OIE_pp_CS_MemAbsSet_MemAbstractMdl_Set_BsConst_OilGauge_ElementTrigBySet_BsConst_OilGauge_Element: start-on-event=MemAbstractMdl_Set_BsConst_OilGauge_Element, operation=pp_CS_MemAbsSet.Set_BsConst_OilGauge_Element
        OIE_pp_CS_MemAbsSet_MemAbstractMdl_Set_BsConst_PowerGauge_ElementTrigBySet_BsConst_PowerGauge_Element: start-on-event=MemAbstractMdl_Set_BsConst_PowerGauge_Element, operation=pp_CS_MemAbsSet.Set_BsConst_PowerGauge_Element
        OIE_pp_CS_MemAbsSet_MemAbstractMdl_Set_BsConst_Power_ElementTrigBySet_BsConst_Power_Element: start-on-event=MemAbstractMdl_Set_BsConst_Power_Element, operation=pp_CS_MemAbsSet.Set_BsConst_Power_Element
        OIE_pp_CS_MemAbsSet_MemAbstractMdl_Set_BsConst_RealTimeClock_ElementTrigBySet_BsConst_RealTimeClock_Element: start-on-event=MemAbstractMdl_Set_BsConst_RealTimeClock_Element, operation=pp_CS_MemAbsSet.Set_BsConst_RealTimeClock_Element
        OIE_pp_CS_MemAbsSet_MemAbstractMdl_Set_BsConst_ServiceReminder_ElementTrigBySet_BsConst_ServiceReminder_Element: start-on-event=MemAbstractMdl_Set_BsConst_ServiceReminder_Element, operation=pp_CS_MemAbsSet.Set_BsConst_ServiceReminder_Element
        OIE_pp_CS_MemAbsSet_MemAbstractMdl_Set_BsConst_SpeedoGauge_ElementTrigBySet_BsConst_SpeedoGauge_Element: start-on-event=MemAbstractMdl_Set_BsConst_SpeedoGauge_Element, operation=pp_CS_MemAbsSet.Set_BsConst_SpeedoGauge_Element
        OIE_pp_CS_MemAbsSet_MemAbstractMdl_Set_BsConst_TachoGauge_ElementTrigBySet_BsConst_TachoGauge_Element: start-on-event=MemAbstractMdl_Set_BsConst_TachoGauge_Element, operation=pp_CS_MemAbsSet.Set_BsConst_TachoGauge_Element
        OIE_pp_CS_MemAbsSet_MemAbstractMdl_Set_BsConst_TempGauge_ElementTrigBySet_BsConst_TempGauge_Element: start-on-event=MemAbstractMdl_Set_BsConst_TempGauge_Element, operation=pp_CS_MemAbsSet.Set_BsConst_TempGauge_Element
        OIE_pp_CS_MemAbsSet_MemAbstractMdl_Set_BsConst_TripComputer_ElementTrigBySet_BsConst_TripComputer_Element: start-on-event=MemAbstractMdl_Set_BsConst_TripComputer_Element, operation=pp_CS_MemAbsSet.Set_BsConst_TripComputer_Element
        OIE_pp_CS_MemAbsSet_MemAbstractMdl_Set_BsConst_Warning_ElementTrigBySet_BsConst_Warning_Element: start-on-event=MemAbstractMdl_Set_BsConst_Warning_Element, operation=pp_CS_MemAbsSet.Set_BsConst_Warning_Element
        OIE_pp_CS_MemAbsSet_MemAbstractMdl_Set_BsCys_Certicificate_ElementTrigBySet_BsCys_Certicificate_Element: start-on-event=MemAbstractMdl_Set_BsCys_Certicificate_Element, operation=pp_CS_MemAbsSet.Set_BsCys_Certicificate_Element
        OIE_pp_CS_MemAbsSet_MemAbstractMdl_Set_BsDiag_Dtc_ElementTrigBySet_BsDiag_Dtc_Element: start-on-event=MemAbstractMdl_Set_BsDiag_Dtc_Element, operation=pp_CS_MemAbsSet.Set_BsDiag_Dtc_Element
        OIE_pp_CS_MemAbsSet_MemAbstractMdl_Set_BsDiag_ErrorRecord_ElementTrigBySet_BsDiag_ErrorRecord_Element: start-on-event=MemAbstractMdl_Set_BsDiag_ErrorRecord_Element, operation=pp_CS_MemAbsSet.Set_BsDiag_ErrorRecord_Element
        OIE_pp_CS_MemAbsSet_MemAbstractMdl_Set_BsFuSa_Audio_ElementTrigBySet_BsFuSa_Audio_Element: start-on-event=MemAbstractMdl_Set_BsFuSa_Audio_Element, operation=pp_CS_MemAbsSet.Set_BsFuSa_Audio_Element
        OIE_pp_CS_MemAbsSet_MemAbstractMdl_Set_BsFuSa_Communication_ElementTrigBySet_BsFuSa_Communication_Element: start-on-event=MemAbstractMdl_Set_BsFuSa_Communication_Element, operation=pp_CS_MemAbsSet.Set_BsFuSa_Communication_Element
        OIE_pp_CS_MemAbsSet_MemAbstractMdl_Set_BsFuSa_Config_ElementTrigBySet_BsFuSa_Config_Element: start-on-event=MemAbstractMdl_Set_BsFuSa_Config_Element, operation=pp_CS_MemAbsSet.Set_BsFuSa_Config_Element
        OIE_pp_CS_MemAbsSet_MemAbstractMdl_Set_BsFuSa_Display_ElementTrigBySet_BsFuSa_Display_Element: start-on-event=MemAbstractMdl_Set_BsFuSa_Display_Element, operation=pp_CS_MemAbsSet.Set_BsFuSa_Display_Element
        OIE_pp_CS_MemAbsSet_MemAbstractMdl_Set_BsFuSa_Power_ElementTrigBySet_BsFuSa_Power_Element: start-on-event=MemAbstractMdl_Set_BsFuSa_Power_Element, operation=pp_CS_MemAbsSet.Set_BsFuSa_Power_Element
        OIE_pp_CS_MemAbsSet_MemAbstractMdl_Set_BsFuSa_Warning_ElementTrigBySet_BsFuSa_Warning_Element: start-on-event=MemAbstractMdl_Set_BsFuSa_Warning_Element, operation=pp_CS_MemAbsSet.Set_BsFuSa_Warning_Element
        OIE_pp_CS_MemAbsSet_MemAbstractMdl_Set_BsFusa_Fota_ElementTrigBySet_BsFusa_Fota_Element: start-on-event=MemAbstractMdl_Set_BsFusa_Fota_Element, operation=pp_CS_MemAbsSet.Set_BsFusa_Fota_Element
        OIE_pp_CS_MemAbsSet_MemAbstractMdl_Set_BsReten_Audio_ElementTrigBySet_BsReten_Audio_Element: start-on-event=MemAbstractMdl_Set_BsReten_Audio_Element, operation=pp_CS_MemAbsSet.Set_BsReten_Audio_Element
        OIE_pp_CS_MemAbsSet_MemAbstractMdl_Set_BsReten_Communication_ElementTrigBySet_BsReten_Communication_Element: start-on-event=MemAbstractMdl_Set_BsReten_Communication_Element, operation=pp_CS_MemAbsSet.Set_BsReten_Communication_Element
        OIE_pp_CS_MemAbsSet_MemAbstractMdl_Set_BsReten_Display_ElementTrigBySet_BsReten_Display_Element: start-on-event=MemAbstractMdl_Set_BsReten_Display_Element, operation=pp_CS_MemAbsSet.Set_BsReten_Display_Element
        OIE_pp_CS_MemAbsSet_MemAbstractMdl_Set_BsReten_Gauges_ElementTrigBySet_BsReten_Gauges_Element: start-on-event=MemAbstractMdl_Set_BsReten_Gauges_Element, operation=pp_CS_MemAbsSet.Set_BsReten_Gauges_Element
        OIE_pp_CS_MemAbsSet_MemAbstractMdl_Set_BsReten_Illumination_ElementTrigBySet_BsReten_Illumination_Element: start-on-event=MemAbstractMdl_Set_BsReten_Illumination_Element, operation=pp_CS_MemAbsSet.Set_BsReten_Illumination_Element
        OIE_pp_CS_MemAbsSet_MemAbstractMdl_Set_BsReten_Odometer_ElementTrigBySet_BsReten_Odometer_Element: start-on-event=MemAbstractMdl_Set_BsReten_Odometer_Element, operation=pp_CS_MemAbsSet.Set_BsReten_Odometer_Element
        OIE_pp_CS_MemAbsSet_MemAbstractMdl_Set_BsReten_Personalization_ElementTrigBySet_BsReten_Personalization_Element: start-on-event=MemAbstractMdl_Set_BsReten_Personalization_Element, operation=pp_CS_MemAbsSet.Set_BsReten_Personalization_Element
        OIE_pp_CS_MemAbsSet_MemAbstractMdl_Set_BsReten_Power_ElementTrigBySet_BsReten_Power_Element: start-on-event=MemAbstractMdl_Set_BsReten_Power_Element, operation=pp_CS_MemAbsSet.Set_BsReten_Power_Element
        OIE_pp_CS_MemAbsSet_MemAbstractMdl_Set_BsReten_RealTimeClock_ElementTrigBySet_BsReten_RealTimeClock_Element: start-on-event=MemAbstractMdl_Set_BsReten_RealTimeClock_Element, operation=pp_CS_MemAbsSet.Set_BsReten_RealTimeClock_Element
        OIE_pp_CS_MemAbsSet_MemAbstractMdl_Set_BsReten_Tripcomputer_ElementTrigBySet_BsReten_Tripcomputer_Element: start-on-event=MemAbstractMdl_Set_BsReten_Tripcomputer_Element, operation=pp_CS_MemAbsSet.Set_BsReten_Tripcomputer_Element
        OIE_pp_CS_MemAbsSet_MemAbstractMdl_Set_BsReten_VisDlt_ElementTrigBySet_BsReten_VisDlt_Element: start-on-event=MemAbstractMdl_Set_BsReten_VisDlt_Element, operation=pp_CS_MemAbsSet.Set_BsReten_VisDlt_Element
        OIE_pp_CS_MemAbsSet_MemAbstractMdl_Set_BsReten_Warning_ElementTrigBySet_BsReten_Warning_Element: start-on-event=MemAbstractMdl_Set_BsReten_Warning_Element, operation=pp_CS_MemAbsSet.Set_BsReten_Warning_Element
        OIE_pp_CS_MemAbsSet_MemAbstractMdl_Set_BsRt_CusDlt_ElementTrigBySet_BsRt_CusDlt_Element: start-on-event=MemAbstractMdl_Set_BsRt_CusDlt_Element, operation=pp_CS_MemAbsSet.Set_BsRt_CusDlt_Element
        OIE_pp_CS_MemAbsSet_MemAbstractMdl_Set_BsRt_FuelGauge_ElementTrigBySet_BsRt_FuelGauge_Element: start-on-event=MemAbstractMdl_Set_BsRt_FuelGauge_Element, operation=pp_CS_MemAbsSet.Set_BsRt_FuelGauge_Element
        OIE_pp_CS_MemAbsSet_MemAbstractMdl_Set_BsRt_Illumination_ElementTrigBySet_BsRt_Illumination_Element: start-on-event=MemAbstractMdl_Set_BsRt_Illumination_Element, operation=pp_CS_MemAbsSet.Set_BsRt_Illumination_Element
        OIE_pp_CS_MemAbsSet_MemAbstractMdl_Set_BsRt_Odometer_ElementTrigBySet_BsRt_Odometer_Element: start-on-event=MemAbstractMdl_Set_BsRt_Odometer_Element, operation=pp_CS_MemAbsSet.Set_BsRt_Odometer_Element
        OIE_pp_CS_MemAbsSet_MemAbstractMdl_Set_BsRt_OilGauge_ElementTrigBySet_BsRt_OilGauge_Element: start-on-event=MemAbstractMdl_Set_BsRt_OilGauge_Element, operation=pp_CS_MemAbsSet.Set_BsRt_OilGauge_Element
        OIE_pp_CS_MemAbsSet_MemAbstractMdl_Set_BsRt_Personalization_ElementTrigBySet_BsRt_Personalization_Element: start-on-event=MemAbstractMdl_Set_BsRt_Personalization_Element, operation=pp_CS_MemAbsSet.Set_BsRt_Personalization_Element
        OIE_pp_CS_MemAbsSet_MemAbstractMdl_Set_BsRt_PowerGauge_ElementTrigBySet_BsRt_PowerGauge_Element: start-on-event=MemAbstractMdl_Set_BsRt_PowerGauge_Element, operation=pp_CS_MemAbsSet.Set_BsRt_PowerGauge_Element
        OIE_pp_CS_MemAbsSet_MemAbstractMdl_Set_BsRt_RealTimeClock_ElementTrigBySet_BsRt_RealTimeClock_Element: start-on-event=MemAbstractMdl_Set_BsRt_RealTimeClock_Element, operation=pp_CS_MemAbsSet.Set_BsRt_RealTimeClock_Element
        OIE_pp_CS_MemAbsSet_MemAbstractMdl_Set_BsRt_SpeedoGauge_ElementTrigBySet_BsRt_SpeedoGauge_Element: start-on-event=MemAbstractMdl_Set_BsRt_SpeedoGauge_Element, operation=pp_CS_MemAbsSet.Set_BsRt_SpeedoGauge_Element
        OIE_pp_CS_MemAbsSet_MemAbstractMdl_Set_BsRt_TachoGauge_ElementTrigBySet_BsRt_TachoGauge_Element: start-on-event=MemAbstractMdl_Set_BsRt_TachoGauge_Element, operation=pp_CS_MemAbsSet.Set_BsRt_TachoGauge_Element
        OIE_pp_CS_MemAbsSet_MemAbstractMdl_Set_BsRt_TempGauge_ElementTrigBySet_BsRt_TempGauge_Element: start-on-event=MemAbstractMdl_Set_BsRt_TempGauge_Element, operation=pp_CS_MemAbsSet.Set_BsRt_TempGauge_Element
        OIE_pp_CS_MemAbsSet_MemAbstractMdl_Set_BsRt_TripComputer_ElementTrigBySet_BsRt_TripComputer_Element: start-on-event=MemAbstractMdl_Set_BsRt_TripComputer_Element, operation=pp_CS_MemAbsSet.Set_BsRt_TripComputer_Element
        OIE_pp_CS_MemAbsSet_MemAbstractMdl_Set_BsRt_Warning_ElementTrigBySet_BsRt_Warning_Element: start-on-event=MemAbstractMdl_Set_BsRt_Warning_Element, operation=pp_CS_MemAbsSet.Set_BsRt_Warning_Element
        OIE_pp_CS_MemAbsSet_MemAbstractMdl_Set_BsShare_EcuPartNumber_ElementTrigBySet_BsShare_EcuPartNumber_Element: start-on-event=MemAbstractMdl_Set_BsShare_EcuPartNumber_Element, operation=pp_CS_MemAbsSet.Set_BsShare_EcuPartNumber_Element
        OIE_pp_CS_MemAbsSet_MemAbstractMdl_Set_BsShare_SwUpdFotaFinPrint_ElementTrigBySet_BsShare_SwUpdFotaFinPrint_Element: start-on-event=MemAbstractMdl_Set_BsShare_SwUpdFotaFinPrint_Element, operation=pp_CS_MemAbsSet.Set_BsShare_SwUpdFotaFinPrint_Element
        OIE_pp_CS_MemAbsSet_MemAbstractMdl_Set_BsShare_SwUpdFotaMode_ElementTrigBySet_BsShare_SwUpdFotaMode_Element: start-on-event=MemAbstractMdl_Set_BsShare_SwUpdFotaMode_Element, operation=pp_CS_MemAbsSet.Set_BsShare_SwUpdFotaMode_Element
        OIE_pp_CS_MemAbsSet_MemAbstractMdl_Set_BsShare_SwUpdFotaStatus_ElementTrigBySet_BsShare_SwUpdFotaStatus_Element: start-on-event=MemAbstractMdl_Set_BsShare_SwUpdFotaStatus_Element, operation=pp_CS_MemAbsSet.Set_BsShare_SwUpdFotaStatus_Element
        OIE_pp_CS_MemAbsSet_MemAbstractMdl_Set_BsShare_SwUpdFotadecrypt_ElementTrigBySet_BsShare_SwUpdFotadecrypt_Element: start-on-event=MemAbstractMdl_Set_BsShare_SwUpdFotadecrypt_Element, operation=pp_CS_MemAbsSet.Set_BsShare_SwUpdFotadecrypt_Element
        OIE_pp_CS_MemAbsSet_MemAbstractMdl_Set_BsShare_SwUpdReflash_ElementTrigBySet_BsShare_SwUpdReflash_Element: start-on-event=MemAbstractMdl_Set_BsShare_SwUpdReflash_Element, operation=pp_CS_MemAbsSet.Set_BsShare_SwUpdReflash_Element
        OIE_pp_CS_MemAbsSet_MemAbstractMdl_Set_BsShare_VehicleConfig_ElementTrigBySet_BsShare_VehicleConfig_Element: start-on-event=MemAbstractMdl_Set_BsShare_VehicleConfig_Element, operation=pp_CS_MemAbsSet.Set_BsShare_VehicleConfig_Element
        OIE_pp_CS_MemAbsSet_MemAbstractMdl_Set_BsShare_VisMeet_ElementTrigBySet_BsShare_VisMeet_Element: start-on-event=MemAbstractMdl_Set_BsShare_VisMeet_Element, operation=pp_CS_MemAbsSet.Set_BsShare_VisMeet_Element
        OIE_pp_CS_MemAbsSet_MemAbstractMdl_Set_RefCys_Certicificate1_ElementTrigBySet_RefCys_Certicificate1_Element: start-on-event=MemAbstractMdl_Set_RefCys_Certicificate1_Element, operation=pp_CS_MemAbsSet.Set_RefCys_Certicificate1_Element
        OIE_pp_CS_MemAbsSet_MemAbstractMdl_Set_RefCys_Certicificate_ElementTrigBySet_RefCys_Certicificate_Element: start-on-event=MemAbstractMdl_Set_RefCys_Certicificate_Element, operation=pp_CS_MemAbsSet.Set_RefCys_Certicificate_Element
      port-api-options:
        enable-take-address=false, indirect-api=false, port=pp_CS_MemAbsGet
        enable-take-address=false, indirect-api=false, port=pp_CS_MemAbsSet
        enable-take-address=false, indirect-api=false, port=pp_CS_MemAbs_NvMWriteStatus
        enable-take-address=false, indirect-api=false, port=pp_SR_JobStatus
      122 x runnable, all with can-be-invoked-concurrently=true:
        MemAbstractMdl_Get_BsConst_Audio_Element
        MemAbstractMdl_Get_BsConst_Communication_Element
        MemAbstractMdl_Get_BsConst_EngOffTimer_Element
        MemAbstractMdl_Get_BsConst_FuelGauge_Element
        MemAbstractMdl_Get_BsConst_Illumination_Element
        MemAbstractMdl_Get_BsConst_OilGauge_Element
        MemAbstractMdl_Get_BsConst_PowerGauge_Element
        MemAbstractMdl_Get_BsConst_Power_Element
        MemAbstractMdl_Get_BsConst_RealTimeClock_Element
        MemAbstractMdl_Get_BsConst_ServiceReminder_Element
        MemAbstractMdl_Get_BsConst_SpeedoGauge_Element
        MemAbstractMdl_Get_BsConst_TachoGauge_Element
        MemAbstractMdl_Get_BsConst_TempGauge_Element
        MemAbstractMdl_Get_BsConst_TripComputer_Element
        MemAbstractMdl_Get_BsConst_Warning_Element
        MemAbstractMdl_Get_BsCys_Certicificate_Element
        MemAbstractMdl_Get_BsDiag_Dtc_Element
        MemAbstractMdl_Get_BsDiag_ErrorRecord_Element
        MemAbstractMdl_Get_BsFuSa_Audio_Element
        MemAbstractMdl_Get_BsFuSa_Communication_Element
        MemAbstractMdl_Get_BsFuSa_Config_Element
        MemAbstractMdl_Get_BsFuSa_Display_Element
        MemAbstractMdl_Get_BsFuSa_Power_Element
        MemAbstractMdl_Get_BsFuSa_Warning_Element
        MemAbstractMdl_Get_BsFusa_Fota_Element
        MemAbstractMdl_Get_BsReten_Audio_Element
        MemAbstractMdl_Get_BsReten_Communication_Element
        MemAbstractMdl_Get_BsReten_Display_Element
        MemAbstractMdl_Get_BsReten_Gauges_Element
        MemAbstractMdl_Get_BsReten_Illumination_Element
        MemAbstractMdl_Get_BsReten_Odometer_Element
        MemAbstractMdl_Get_BsReten_Personalization_Element
        MemAbstractMdl_Get_BsReten_Power_Element
        MemAbstractMdl_Get_BsReten_RealTimeClock_Element
        MemAbstractMdl_Get_BsReten_Tripcomputer_Element
        MemAbstractMdl_Get_BsReten_VisDlt_Element
        MemAbstractMdl_Get_BsReten_Warning_Element
        MemAbstractMdl_Get_BsRt_CusDlt_Element
        MemAbstractMdl_Get_BsRt_FuelGauge_Element
        MemAbstractMdl_Get_BsRt_Illumination_Element
        MemAbstractMdl_Get_BsRt_Odometer_Element
        MemAbstractMdl_Get_BsRt_OilGauge_Element
        MemAbstractMdl_Get_BsRt_Personalization_Element
        MemAbstractMdl_Get_BsRt_PowerGauge_Element
        MemAbstractMdl_Get_BsRt_RealTimeClock_Element
        MemAbstractMdl_Get_BsRt_SpeedoGauge_Element
        MemAbstractMdl_Get_BsRt_TachoGauge_Element
        MemAbstractMdl_Get_BsRt_TempGauge_Element
        MemAbstractMdl_Get_BsRt_TripComputer_Element
        MemAbstractMdl_Get_BsRt_Warning_Element
        MemAbstractMdl_Get_BsShare_EcuPartNumber_Element
        MemAbstractMdl_Get_BsShare_SwUpdFotaFinPrint_Element
        MemAbstractMdl_Get_BsShare_SwUpdFotaMode_Element
        MemAbstractMdl_Get_BsShare_SwUpdFotaStatus_Element
        MemAbstractMdl_Get_BsShare_SwUpdFotadecrypt_Element
        MemAbstractMdl_Get_BsShare_SwUpdReflash_Element
        MemAbstractMdl_Get_BsShare_VehicleConfig_Element
        MemAbstractMdl_Get_BsShare_VisMeet_Element
        MemAbstractMdl_Get_RefCys_Certicificate1_Element
        MemAbstractMdl_Get_RefCys_Certicificate_Element
        MemAbstractMdl_MainFunction
          data-send-points:
            60 x access:
              DWA_pp_SR_JobStatus_JobStatus_BsConst_Audio_Element: accessed-variable=pp_SR_JobStatus.JobStatus_BsConst_Audio_Element
              DWA_pp_SR_JobStatus_JobStatus_BsConst_Communication_Element: accessed-variable=pp_SR_JobStatus.JobStatus_BsConst_Communication_Element
              DWA_pp_SR_JobStatus_JobStatus_BsConst_EngOffTimer_Element: accessed-variable=pp_SR_JobStatus.JobStatus_BsConst_EngOffTimer_Element
              DWA_pp_SR_JobStatus_JobStatus_BsConst_FuelGauge_Element: accessed-variable=pp_SR_JobStatus.JobStatus_BsConst_FuelGauge_Element
              DWA_pp_SR_JobStatus_JobStatus_BsConst_Illumination_Element: accessed-variable=pp_SR_JobStatus.JobStatus_BsConst_Illumination_Element
              DWA_pp_SR_JobStatus_JobStatus_BsConst_OilGauge_Element: accessed-variable=pp_SR_JobStatus.JobStatus_BsConst_OilGauge_Element
              DWA_pp_SR_JobStatus_JobStatus_BsConst_PowerGauge_Element: accessed-variable=pp_SR_JobStatus.JobStatus_BsConst_PowerGauge_Element
              DWA_pp_SR_JobStatus_JobStatus_BsConst_Power_Element: accessed-variable=pp_SR_JobStatus.JobStatus_BsConst_Power_Element
              DWA_pp_SR_JobStatus_JobStatus_BsConst_RealTimeClock_Element: accessed-variable=pp_SR_JobStatus.JobStatus_BsConst_RealTimeClock_Element
              DWA_pp_SR_JobStatus_JobStatus_BsConst_ServiceReminder_Element: accessed-variable=pp_SR_JobStatus.JobStatus_BsConst_ServiceReminder_Element
              DWA_pp_SR_JobStatus_JobStatus_BsConst_SpeedoGauge_Element: accessed-variable=pp_SR_JobStatus.JobStatus_BsConst_SpeedoGauge_Element
              DWA_pp_SR_JobStatus_JobStatus_BsConst_TachoGauge_Element: accessed-variable=pp_SR_JobStatus.JobStatus_BsConst_TachoGauge_Element
              DWA_pp_SR_JobStatus_JobStatus_BsConst_TempGauge_Element: accessed-variable=pp_SR_JobStatus.JobStatus_BsConst_TempGauge_Element
              DWA_pp_SR_JobStatus_JobStatus_BsConst_TripComputer_Element: accessed-variable=pp_SR_JobStatus.JobStatus_BsConst_TripComputer_Element
              DWA_pp_SR_JobStatus_JobStatus_BsConst_Warning_Element: accessed-variable=pp_SR_JobStatus.JobStatus_BsConst_Warning_Element
              DWA_pp_SR_JobStatus_JobStatus_BsCys_Certicificate_Element: accessed-variable=pp_SR_JobStatus.JobStatus_BsCys_Certicificate_Element
              DWA_pp_SR_JobStatus_JobStatus_BsDiag_Dtc_Element: accessed-variable=pp_SR_JobStatus.JobStatus_BsDiag_Dtc_Element
              DWA_pp_SR_JobStatus_JobStatus_BsDiag_ErrorRecord_Element: accessed-variable=pp_SR_JobStatus.JobStatus_BsDiag_ErrorRecord_Element
              DWA_pp_SR_JobStatus_JobStatus_BsFuSa_Audio_Element: accessed-variable=pp_SR_JobStatus.JobStatus_BsFuSa_Audio_Element
              DWA_pp_SR_JobStatus_JobStatus_BsFuSa_Communication_Element: accessed-variable=pp_SR_JobStatus.JobStatus_BsFuSa_Communication_Element
              DWA_pp_SR_JobStatus_JobStatus_BsFuSa_Config_Element: accessed-variable=pp_SR_JobStatus.JobStatus_BsFuSa_Config_Element
              DWA_pp_SR_JobStatus_JobStatus_BsFuSa_Display_Element: accessed-variable=pp_SR_JobStatus.JobStatus_BsFuSa_Display_Element
              DWA_pp_SR_JobStatus_JobStatus_BsFuSa_Power_Element: accessed-variable=pp_SR_JobStatus.JobStatus_BsFuSa_Power_Element
              DWA_pp_SR_JobStatus_JobStatus_BsFuSa_Warning_Element: accessed-variable=pp_SR_JobStatus.JobStatus_BsFuSa_Warning_Element
              DWA_pp_SR_JobStatus_JobStatus_BsFusa_Fota_Element: accessed-variable=pp_SR_JobStatus.JobStatus_BsFusa_Fota_Element
              DWA_pp_SR_JobStatus_JobStatus_BsReten_Audio_Element: accessed-variable=pp_SR_JobStatus.JobStatus_BsReten_Audio_Element
              DWA_pp_SR_JobStatus_JobStatus_BsReten_Communication_Element: accessed-variable=pp_SR_JobStatus.JobStatus_BsReten_Communication_Element
              DWA_pp_SR_JobStatus_JobStatus_BsReten_Display_Element: accessed-variable=pp_SR_JobStatus.JobStatus_BsReten_Display_Element
              DWA_pp_SR_JobStatus_JobStatus_BsReten_Gauges_Element: accessed-variable=pp_SR_JobStatus.JobStatus_BsReten_Gauges_Element
              DWA_pp_SR_JobStatus_JobStatus_BsReten_Illumination_Element: accessed-variable=pp_SR_JobStatus.JobStatus_BsReten_Illumination_Element
              DWA_pp_SR_JobStatus_JobStatus_BsReten_Odometer_Element: accessed-variable=pp_SR_JobStatus.JobStatus_BsReten_Odometer_Element
              DWA_pp_SR_JobStatus_JobStatus_BsReten_Personalization_Element: accessed-variable=pp_SR_JobStatus.JobStatus_BsReten_Personalization_Element
              DWA_pp_SR_JobStatus_JobStatus_BsReten_Power_Element: accessed-variable=pp_SR_JobStatus.JobStatus_BsReten_Power_Element
              DWA_pp_SR_JobStatus_JobStatus_BsReten_RealTimeClock_Element: accessed-variable=pp_SR_JobStatus.JobStatus_BsReten_RealTimeClock_Element
              DWA_pp_SR_JobStatus_JobStatus_BsReten_Tripcomputer_Element: accessed-variable=pp_SR_JobStatus.JobStatus_BsReten_Tripcomputer_Element
              DWA_pp_SR_JobStatus_JobStatus_BsReten_VisDlt_Element: accessed-variable=pp_SR_JobStatus.JobStatus_BsReten_VisDlt_Element
              DWA_pp_SR_JobStatus_JobStatus_BsReten_Warning_Element: accessed-variable=pp_SR_JobStatus.JobStatus_BsReten_Warning_Element
              DWA_pp_SR_JobStatus_JobStatus_BsRt_CusDlt_Element: accessed-variable=pp_SR_JobStatus.JobStatus_BsRt_CusDlt_Element
              DWA_pp_SR_JobStatus_JobStatus_BsRt_FuelGauge_Element: accessed-variable=pp_SR_JobStatus.JobStatus_BsRt_FuelGauge_Element
              DWA_pp_SR_JobStatus_JobStatus_BsRt_Illumination_Element: accessed-variable=pp_SR_JobStatus.JobStatus_BsRt_Illumination_Element
              DWA_pp_SR_JobStatus_JobStatus_BsRt_Odometer_Element: accessed-variable=pp_SR_JobStatus.JobStatus_BsRt_Odometer_Element
              DWA_pp_SR_JobStatus_JobStatus_BsRt_OilGauge_Element: accessed-variable=pp_SR_JobStatus.JobStatus_BsRt_OilGauge_Element
              DWA_pp_SR_JobStatus_JobStatus_BsRt_Personalization_Element: accessed-variable=pp_SR_JobStatus.JobStatus_BsRt_Personalization_Element
              DWA_pp_SR_JobStatus_JobStatus_BsRt_PowerGauge_Element: accessed-variable=pp_SR_JobStatus.JobStatus_BsRt_PowerGauge_Element
              DWA_pp_SR_JobStatus_JobStatus_BsRt_RealTimeClock_Element: accessed-variable=pp_SR_JobStatus.JobStatus_BsRt_RealTimeClock_Element
              DWA_pp_SR_JobStatus_JobStatus_BsRt_SpeedoGauge_Element: accessed-variable=pp_SR_JobStatus.JobStatus_BsRt_SpeedoGauge_Element
              DWA_pp_SR_JobStatus_JobStatus_BsRt_TachoGauge_Element: accessed-variable=pp_SR_JobStatus.JobStatus_BsRt_TachoGauge_Element
              DWA_pp_SR_JobStatus_JobStatus_BsRt_TempGauge_Element: accessed-variable=pp_SR_JobStatus.JobStatus_BsRt_TempGauge_Element
              DWA_pp_SR_JobStatus_JobStatus_BsRt_TripComputer_Element: accessed-variable=pp_SR_JobStatus.JobStatus_BsRt_TripComputer_Element
              DWA_pp_SR_JobStatus_JobStatus_BsRt_Warning_Element: accessed-variable=pp_SR_JobStatus.JobStatus_BsRt_Warning_Element
              DWA_pp_SR_JobStatus_JobStatus_BsShare_EcuPartNumber_Element: accessed-variable=pp_SR_JobStatus.JobStatus_BsShare_EcuPartNumber_Element
              DWA_pp_SR_JobStatus_JobStatus_BsShare_SwUpdFotaFinPrint_Element: accessed-variable=pp_SR_JobStatus.JobStatus_BsShare_SwUpdFotaFinPrint_Element
              DWA_pp_SR_JobStatus_JobStatus_BsShare_SwUpdFotaMode_Element: accessed-variable=pp_SR_JobStatus.JobStatus_BsShare_SwUpdFotaMode_Element
              DWA_pp_SR_JobStatus_JobStatus_BsShare_SwUpdFotaStatus_Element: accessed-variable=pp_SR_JobStatus.JobStatus_BsShare_SwUpdFotaStatus_Element
              DWA_pp_SR_JobStatus_JobStatus_BsShare_SwUpdFotadecrypt_Element: accessed-variable=pp_SR_JobStatus.JobStatus_BsShare_SwUpdFotadecrypt_Element
              DWA_pp_SR_JobStatus_JobStatus_BsShare_SwUpdReflash_Element: accessed-variable=pp_SR_JobStatus.JobStatus_BsShare_SwUpdReflash_Element
              DWA_pp_SR_JobStatus_JobStatus_BsShare_VehicleConfig_Element: accessed-variable=pp_SR_JobStatus.JobStatus_BsShare_VehicleConfig_Element
              DWA_pp_SR_JobStatus_JobStatus_BsShare_VisMeet_Element: accessed-variable=pp_SR_JobStatus.JobStatus_BsShare_VisMeet_Element
              DWA_pp_SR_JobStatus_JobStatus_RefCys_Certicificate1_Element: accessed-variable=pp_SR_JobStatus.JobStatus_RefCys_Certicificate1_Element
              DWA_pp_SR_JobStatus_JobStatus_RefCys_Certicificate_Element: accessed-variable=pp_SR_JobStatus.JobStatus_RefCys_Certicificate_Element
        MemAbstractMdl_NvmWriteStatus
        MemAbstractMdl_Set_BsConst_Audio_Element
        MemAbstractMdl_Set_BsConst_Communication_Element
        MemAbstractMdl_Set_BsConst_EngOffTimer_Element
        MemAbstractMdl_Set_BsConst_FuelGauge_Element
        MemAbstractMdl_Set_BsConst_Illumination_Element
        MemAbstractMdl_Set_BsConst_OilGauge_Element
        MemAbstractMdl_Set_BsConst_PowerGauge_Element
        MemAbstractMdl_Set_BsConst_Power_Element
        MemAbstractMdl_Set_BsConst_RealTimeClock_Element
        MemAbstractMdl_Set_BsConst_ServiceReminder_Element
        MemAbstractMdl_Set_BsConst_SpeedoGauge_Element
        MemAbstractMdl_Set_BsConst_TachoGauge_Element
        MemAbstractMdl_Set_BsConst_TempGauge_Element
        MemAbstractMdl_Set_BsConst_TripComputer_Element
        MemAbstractMdl_Set_BsConst_Warning_Element
        MemAbstractMdl_Set_BsCys_Certicificate_Element
        MemAbstractMdl_Set_BsDiag_Dtc_Element
        MemAbstractMdl_Set_BsDiag_ErrorRecord_Element
        MemAbstractMdl_Set_BsFuSa_Audio_Element
        MemAbstractMdl_Set_BsFuSa_Communication_Element
        MemAbstractMdl_Set_BsFuSa_Config_Element
        MemAbstractMdl_Set_BsFuSa_Display_Element
        MemAbstractMdl_Set_BsFuSa_Power_Element
        MemAbstractMdl_Set_BsFuSa_Warning_Element
        MemAbstractMdl_Set_BsFusa_Fota_Element
        MemAbstractMdl_Set_BsReten_Audio_Element
        MemAbstractMdl_Set_BsReten_Communication_Element
        MemAbstractMdl_Set_BsReten_Display_Element
        MemAbstractMdl_Set_BsReten_Gauges_Element
        MemAbstractMdl_Set_BsReten_Illumination_Element
        MemAbstractMdl_Set_BsReten_Odometer_Element
        MemAbstractMdl_Set_BsReten_Personalization_Element
        MemAbstractMdl_Set_BsReten_Power_Element
        MemAbstractMdl_Set_BsReten_RealTimeClock_Element
        MemAbstractMdl_Set_BsReten_Tripcomputer_Element
        MemAbstractMdl_Set_BsReten_VisDlt_Element
        MemAbstractMdl_Set_BsReten_Warning_Element
        MemAbstractMdl_Set_BsRt_CusDlt_Element
        MemAbstractMdl_Set_BsRt_FuelGauge_Element
        MemAbstractMdl_Set_BsRt_Illumination_Element
        MemAbstractMdl_Set_BsRt_Odometer_Element
        MemAbstractMdl_Set_BsRt_OilGauge_Element
        MemAbstractMdl_Set_BsRt_Personalization_Element
        MemAbstractMdl_Set_BsRt_PowerGauge_Element
        MemAbstractMdl_Set_BsRt_RealTimeClock_Element
        MemAbstractMdl_Set_BsRt_SpeedoGauge_Element
        MemAbstractMdl_Set_BsRt_TachoGauge_Element
        MemAbstractMdl_Set_BsRt_TempGauge_Element
        MemAbstractMdl_Set_BsRt_TripComputer_Element
        MemAbstractMdl_Set_BsRt_Warning_Element
        MemAbstractMdl_Set_BsShare_EcuPartNumber_Element
        MemAbstractMdl_Set_BsShare_SwUpdFotaFinPrint_Element
        MemAbstractMdl_Set_BsShare_SwUpdFotaMode_Element
        MemAbstractMdl_Set_BsShare_SwUpdFotaStatus_Element
        MemAbstractMdl_Set_BsShare_SwUpdFotadecrypt_Element
        MemAbstractMdl_Set_BsShare_SwUpdReflash_Element
        MemAbstractMdl_Set_BsShare_VehicleConfig_Element
        MemAbstractMdl_Set_BsShare_VisMeet_Element
        MemAbstractMdl_Set_RefCys_Certicificate1_Element
        MemAbstractMdl_Set_RefCys_Certicificate_Element
  60 x constant specification:
    MemAbstractMdlJobStatus_BsConst_Audio_ElementValue0: value-spec=MemAbstractMdlJobStatus_BsConst_Audio_ElementValue0:0
    MemAbstractMdlJobStatus_BsConst_Communication_ElementValue0: value-spec=MemAbstractMdlJobStatus_BsConst_Communication_ElementValue0:0
    MemAbstractMdlJobStatus_BsConst_EngOffTimer_ElementValue0: value-spec=MemAbstractMdlJobStatus_BsConst_EngOffTimer_ElementValue0:0
    MemAbstractMdlJobStatus_BsConst_FuelGauge_ElementValue0: value-spec=MemAbstractMdlJobStatus_BsConst_FuelGauge_ElementValue0:0
    MemAbstractMdlJobStatus_BsConst_Illumination_ElementValue0: value-spec=MemAbstractMdlJobStatus_BsConst_Illumination_ElementValue0:0
    MemAbstractMdlJobStatus_BsConst_OilGauge_ElementValue0: value-spec=MemAbstractMdlJobStatus_BsConst_OilGauge_ElementValue0:0
    MemAbstractMdlJobStatus_BsConst_PowerGauge_ElementValue0: value-spec=MemAbstractMdlJobStatus_BsConst_PowerGauge_ElementValue0:0
    MemAbstractMdlJobStatus_BsConst_Power_ElementValue0: value-spec=MemAbstractMdlJobStatus_BsConst_Power_ElementValue0:0
    MemAbstractMdlJobStatus_BsConst_RealTimeClock_ElementValue0: value-spec=MemAbstractMdlJobStatus_BsConst_RealTimeClock_ElementValue0:0
    MemAbstractMdlJobStatus_BsConst_ServiceReminder_ElementValue0: value-spec=MemAbstractMdlJobStatus_BsConst_ServiceReminder_ElementValue0:0
    MemAbstractMdlJobStatus_BsConst_SpeedoGauge_ElementValue0: value-spec=MemAbstractMdlJobStatus_BsConst_SpeedoGauge_ElementValue0:0
    MemAbstractMdlJobStatus_BsConst_TachoGauge_ElementValue0: value-spec=MemAbstractMdlJobStatus_BsConst_TachoGauge_ElementValue0:0
    MemAbstractMdlJobStatus_BsConst_TempGauge_ElementValue0: value-spec=MemAbstractMdlJobStatus_BsConst_TempGauge_ElementValue0:0
    MemAbstractMdlJobStatus_BsConst_TripComputer_ElementValue0: value-spec=MemAbstractMdlJobStatus_BsConst_TripComputer_ElementValue0:0
    MemAbstractMdlJobStatus_BsConst_Warning_ElementValue0: value-spec=MemAbstractMdlJobStatus_BsConst_Warning_ElementValue0:0
    MemAbstractMdlJobStatus_BsCys_Certicificate_ElementValue0: value-spec=MemAbstractMdlJobStatus_BsCys_Certicificate_ElementValue0:0
    MemAbstractMdlJobStatus_BsDiag_Dtc_ElementValue0: value-spec=MemAbstractMdlJobStatus_BsDiag_Dtc_ElementValue0:0
    MemAbstractMdlJobStatus_BsDiag_ErrorRecord_ElementValue0: value-spec=MemAbstractMdlJobStatus_BsDiag_ErrorRecord_ElementValue0:0
    MemAbstractMdlJobStatus_BsFuSa_Audio_ElementValue0: value-spec=MemAbstractMdlJobStatus_BsFuSa_Audio_ElementValue0:0
    MemAbstractMdlJobStatus_BsFuSa_Communication_ElementValue0: value-spec=MemAbstractMdlJobStatus_BsFuSa_Communication_ElementValue0:0
    MemAbstractMdlJobStatus_BsFuSa_Config_ElementValue0: value-spec=MemAbstractMdlJobStatus_BsFuSa_Config_ElementValue0:0
    MemAbstractMdlJobStatus_BsFuSa_Display_ElementValue0: value-spec=MemAbstractMdlJobStatus_BsFuSa_Display_ElementValue0:0
    MemAbstractMdlJobStatus_BsFuSa_Power_ElementValue0: value-spec=MemAbstractMdlJobStatus_BsFuSa_Power_ElementValue0:0
    MemAbstractMdlJobStatus_BsFuSa_Warning_ElementValue0: value-spec=MemAbstractMdlJobStatus_BsFuSa_Warning_ElementValue0:0
    MemAbstractMdlJobStatus_BsFusa_Fota_ElementValue0: value-spec=MemAbstractMdlJobStatus_BsFusa_Fota_ElementValue0:0
    MemAbstractMdlJobStatus_BsReten_Audio_ElementValue0: value-spec=MemAbstractMdlJobStatus_BsReten_Audio_ElementValue0:0
    MemAbstractMdlJobStatus_BsReten_Communication_ElementValue0: value-spec=MemAbstractMdlJobStatus_BsReten_Communication_ElementValue0:0
    MemAbstractMdlJobStatus_BsReten_Display_ElementValue0: value-spec=MemAbstractMdlJobStatus_BsReten_Display_ElementValue0:0
    MemAbstractMdlJobStatus_BsReten_Gauges_ElementValue0: value-spec=MemAbstractMdlJobStatus_BsReten_Gauges_ElementValue0:0
    MemAbstractMdlJobStatus_BsReten_Illumination_ElementValue0: value-spec=MemAbstractMdlJobStatus_BsReten_Illumination_ElementValue0:0
    MemAbstractMdlJobStatus_BsReten_Odometer_ElementValue0: value-spec=MemAbstractMdlJobStatus_BsReten_Odometer_ElementValue0:0
    MemAbstractMdlJobStatus_BsReten_Personalization_ElementValue0: value-spec=MemAbstractMdlJobStatus_BsReten_Personalization_ElementValue0:0
    MemAbstractMdlJobStatus_BsReten_Power_ElementValue0: value-spec=MemAbstractMdlJobStatus_BsReten_Power_ElementValue0:0
    MemAbstractMdlJobStatus_BsReten_RealTimeClock_ElementValue0: value-spec=MemAbstractMdlJobStatus_BsReten_RealTimeClock_ElementValue0:0
    MemAbstractMdlJobStatus_BsReten_Tripcomputer_ElementValue0: value-spec=MemAbstractMdlJobStatus_BsReten_Tripcomputer_ElementValue0:0
    MemAbstractMdlJobStatus_BsReten_VisDlt_ElementValue0: value-spec=MemAbstractMdlJobStatus_BsReten_VisDlt_ElementValue0:0
    MemAbstractMdlJobStatus_BsReten_Warning_ElementValue0: value-spec=MemAbstractMdlJobStatus_BsReten_Warning_ElementValue0:0
    MemAbstractMdlJobStatus_BsRt_CusDlt_ElementValue0: value-spec=MemAbstractMdlJobStatus_BsRt_CusDlt_ElementValue0:0
    MemAbstractMdlJobStatus_BsRt_FuelGauge_ElementValue0: value-spec=MemAbstractMdlJobStatus_BsRt_FuelGauge_ElementValue0:0
    MemAbstractMdlJobStatus_BsRt_Illumination_ElementValue0: value-spec=MemAbstractMdlJobStatus_BsRt_Illumination_ElementValue0:0
    MemAbstractMdlJobStatus_BsRt_Odometer_ElementValue0: value-spec=MemAbstractMdlJobStatus_BsRt_Odometer_ElementValue0:0
    MemAbstractMdlJobStatus_BsRt_OilGauge_ElementValue0: value-spec=MemAbstractMdlJobStatus_BsRt_OilGauge_ElementValue0:0
    MemAbstractMdlJobStatus_BsRt_Personalization_ElementValue0: value-spec=MemAbstractMdlJobStatus_BsRt_Personalization_ElementValue0:0
    MemAbstractMdlJobStatus_BsRt_PowerGauge_ElementValue0: value-spec=MemAbstractMdlJobStatus_BsRt_PowerGauge_ElementValue0:0
    MemAbstractMdlJobStatus_BsRt_RealTimeClock_ElementValue0: value-spec=MemAbstractMdlJobStatus_BsRt_RealTimeClock_ElementValue0:0
    MemAbstractMdlJobStatus_BsRt_SpeedoGauge_ElementValue0: value-spec=MemAbstractMdlJobStatus_BsRt_SpeedoGauge_ElementValue0:0
    MemAbstractMdlJobStatus_BsRt_TachoGauge_ElementValue0: value-spec=MemAbstractMdlJobStatus_BsRt_TachoGauge_ElementValue0:0
    MemAbstractMdlJobStatus_BsRt_TempGauge_ElementValue0: value-spec=MemAbstractMdlJobStatus_BsRt_TempGauge_ElementValue0:0
    MemAbstractMdlJobStatus_BsRt_TripComputer_ElementValue0: value-spec=MemAbstractMdlJobStatus_BsRt_TripComputer_ElementValue0:0
    MemAbstractMdlJobStatus_BsRt_Warning_ElementValue0: value-spec=MemAbstractMdlJobStatus_BsRt_Warning_ElementValue0:0
    MemAbstractMdlJobStatus_BsShare_EcuPartNumber_ElementValue0: value-spec=MemAbstractMdlJobStatus_BsShare_EcuPartNumber_ElementValue0:0
    MemAbstractMdlJobStatus_BsShare_SwUpdFotaFinPrint_ElementValue0: value-spec=MemAbstractMdlJobStatus_BsShare_SwUpdFotaFinPrint_ElementValue0:0
    MemAbstractMdlJobStatus_BsShare_SwUpdFotaMode_ElementValue0: value-spec=MemAbstractMdlJobStatus_BsShare_SwUpdFotaMode_ElementValue0:0
    MemAbstractMdlJobStatus_BsShare_SwUpdFotaStatus_ElementValue0: value-spec=MemAbstractMdlJobStatus_BsShare_SwUpdFotaStatus_ElementValue0:0
    MemAbstractMdlJobStatus_BsShare_SwUpdFotadecrypt_ElementValue0: value-spec=MemAbstractMdlJobStatus_BsShare_SwUpdFotadecrypt_ElementValue0:0
    MemAbstractMdlJobStatus_BsShare_SwUpdReflash_ElementValue0: value-spec=MemAbstractMdlJobStatus_BsShare_SwUpdReflash_ElementValue0:0
    MemAbstractMdlJobStatus_BsShare_VehicleConfig_ElementValue0: value-spec=MemAbstractMdlJobStatus_BsShare_VehicleConfig_ElementValue0:0
    MemAbstractMdlJobStatus_BsShare_VisMeet_ElementValue0: value-spec=MemAbstractMdlJobStatus_BsShare_VisMeet_ElementValue0:0
    MemAbstractMdlJobStatus_RefCys_Certicificate1_ElementValue0: value-spec=MemAbstractMdlJobStatus_RefCys_Certicificate1_ElementValue0:0
    MemAbstractMdlJobStatus_RefCys_Certicificate_ElementValue0: value-spec=MemAbstractMdlJobStatus_RefCys_Certicificate_ElementValue0:0
  swc implementation IMPL_MemAbstractMdl: programming-language=C, behavior=IB_MemAbstractMdl
    code-descriptors:
      code CodeDescriptor
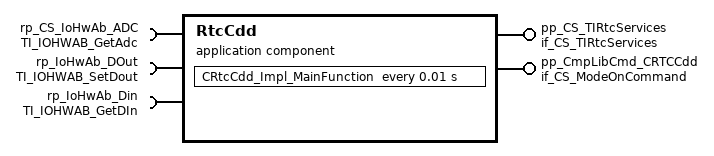
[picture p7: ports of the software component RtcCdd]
  application sw component type RtcCdd
    provide port pp_CS_TIRtcServices: provided-interface=if_CS_TIRtcServices
      provided-com-specs:
        operation=RtcCdd_ClearAlarm, queue-length=1
        operation=RtcCdd_GetTime, queue-length=1
        operation=RtcCdd_SetAlarm, queue-length=1
        operation=RtcCdd_SetTime, queue-length=1
    provide port pp_CmpLibCmd_CRTCCdd: server-com-spec{operation=Impl_OnCommand, queue-length=1}, provided-interface=if_CS_ModeOnCommand
    require port rp_CS_IoHwAb_ADC: required-interface=TI_IOHWAB_GetAdc
    require port rp_IoHwAb_DOut: required-interface=TI_IOHWAB_SetDout
    require port rp_IoHwAb_Din: required-interface=TI_IOHWAB_GetDIn
    behavior IB_RtcCdd
      timing event TECRtcCdd_Impl_MainFunction: start-on-event=CRtcCdd_Impl_MainFunction, period=0.01
      4 x operation invoked event:
        OIE_pp_CS_TIRtcServices_RtcCdd_ClearAlarmTrigByRtcCdd_ClearAlarm: start-on-event=RtcCdd_ClearAlarm, operation=pp_CS_TIRtcServices.RtcCdd_ClearAlarm
        OIE_pp_CS_TIRtcServices_RtcCdd_GetTimeTrigByRtcCdd_GetTime: start-on-event=RtcCdd_GetTime, operation=pp_CS_TIRtcServices.RtcCdd_GetTime
        OIE_pp_CS_TIRtcServices_RtcCdd_SetAlarmTrigByRtcCdd_SetAlarm: start-on-event=RtcCdd_SetAlarm, operation=pp_CS_TIRtcServices.RtcCdd_SetAlarm
        OIE_pp_CS_TIRtcServices_RtcCdd_SetTimeTrigByRtcCdd_SetTime: start-on-event=RtcCdd_SetTime, operation=pp_CS_TIRtcServices.RtcCdd_SetTime
      port-api-options:
        enable-take-address=false, indirect-api=false, port=pp_CS_TIRtcServices
        enable-take-address=false, indirect-api=false, port=pp_CmpLibCmd_CRTCCdd
        enable-take-address=false, indirect-api=false, port=rp_CS_IoHwAb_ADC
        enable-take-address=false, indirect-api=false, port=rp_IoHwAb_DOut
        enable-take-address=false, indirect-api=false, port=rp_IoHwAb_Din
      5 x runnable, all with can-be-invoked-concurrently=true:
        CRtcCdd_Impl_MainFunction
          9 x sync call, all with timeout=0.0:
            OA_rp_CS_IoHwAb_ADC_GetAsyncRawAdc: operation=rp_CS_IoHwAb_ADC.GetAsyncRawAdc
            OA_rp_CS_IoHwAb_ADC_GetSyncRawAdc: operation=rp_CS_IoHwAb_ADC.GetSyncRawAdc
            OA_rp_CS_IoHwAb_ADC_GetProcessedAdc: operation=rp_CS_IoHwAb_ADC.GetProcessedAdc
            OA_rp_IoHwAb_DOut_SetOutputGroup: operation=rp_IoHwAb_DOut.SetOutputGroup
            OA_rp_IoHwAb_DOut_SetOutputPin: operation=rp_IoHwAb_DOut.SetOutputPin
            OA_rp_IoHwAb_Din_GetAsyncRawInput: operation=rp_IoHwAb_Din.GetAsyncRawInput
            OA_rp_IoHwAb_Din_GetProcessedInput: operation=rp_IoHwAb_Din.GetProcessedInput
            OA_rp_IoHwAb_Din_GetSyncRawInput: operation=rp_IoHwAb_Din.GetSyncRawInput
            OA_rp_IoHwAb_Din_GetInputGroup: operation=rp_IoHwAb_Din.GetInputGroup
        RtcCdd_ClearAlarm
        RtcCdd_GetTime
        RtcCdd_SetAlarm
        RtcCdd_SetTime
  swc implementation IMPL_RtcCdd: programming-language=C, behavior=IB_RtcCdd
    code-descriptors:
      code CodeDescriptor
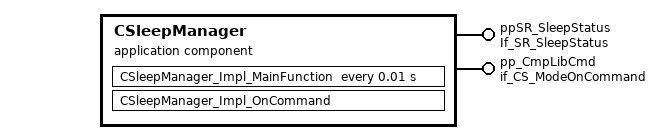
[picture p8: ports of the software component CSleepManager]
  application sw component type CSleepManager
    provide port ppSR_SleepStatus: nonqueued-sender-com-spec{data-element=SleepManager_SleepStatus, init-value=constant-reference=CSleepManagerSleepManager_SleepStatusValue0}, provided-interface=If_SR_SleepStatus
    provide port pp_CmpLibCmd: server-com-spec{operation=Impl_OnCommand, queue-length=1}, provided-interface=if_CS_ModeOnCommand
    behavior IB_CSleepManager
      timing event TECSleepManager_Impl_MainFunction: start-on-event=CSleepManager_Impl_MainFunction, period=0.01
      operation invoked event OIE_pp_CmpLibCmd_CSleepManager_Impl_OnCommandTrigByImpl_OnCommand: start-on-event=CSleepManager_Impl_OnCommand, operation=pp_CmpLibCmd.Impl_OnCommand
      port-api-options:
        enable-take-address=false, indirect-api=false, port=ppSR_SleepStatus
        enable-take-address=false, indirect-api=false, port=CSleepManager/pp_CmpLibCmd
      runnable CSleepManager_Impl_MainFunction: can-be-invoked-concurrently=true
        data-send-points:
          access DWA_ppSR_SleepStatus_SleepManager_SleepStatus: accessed-variable=ppSR_SleepStatus.SleepManager_SleepStatus
      runnable CSleepManager_Impl_OnCommand: can-be-invoked-concurrently=true
  constant specification CSleepManagerSleepManager_SleepStatusValue0: value-spec=CSleepManagerSleepManager_SleepStatusValue0:0
  swc implementation IMPL_CSleepManager: programming-language=C, behavior=IB_CSleepManager
    code-descriptors:
      code CodeDescriptor
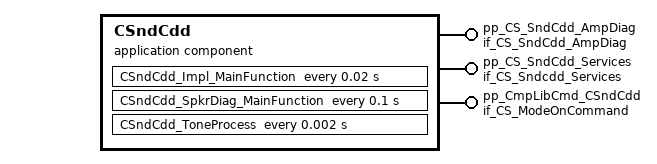
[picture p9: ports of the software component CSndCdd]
  application sw component type CSndCdd
    provide port pp_CS_SndCdd_AmpDiag: provided-com-specs=[{operation=GetSpeaker_status, queue-length=1}, {operation=SpkrAmp_Recovery, queue-length=1}], provided-interface=if_CS_SndCdd_AmpDiag
    provide port pp_CS_SndCdd_Services: provided-interface=if_CS_Sndcdd_Services
      provided-com-specs:
        operation=CheckChimeStatus, queue-length=1
        operation=CheckLastToneStatus, queue-length=1
        operation=ClearChimeResumeInfoBuffer, queue-length=1
        operation=GetChimeResumeInfoBuffer, queue-length=1
        operation=RequestCustomChime, queue-length=1
        operation=RequestToClear_SafetyChimeErrorStatus, queue-length=1
        operation=RequestToStart, queue-length=1
        operation=RequestToStop, queue-length=1
        operation=SetChimeResumeInfoBuffer, queue-length=1
        operation=SetDynamicDeadTime, queue-length=1
        operation=SetUserPersonalizationVolume, queue-length=1
        operation=StopCustomChime, queue-length=1
        operation=UpdateChannelVolume, queue-length=1
        operation=UpdateChimeInfoBuffer, queue-length=1
        operation=UpdateChimeVolume, queue-length=1
        operation=ischannelavailable, queue-length=1
    provide port pp_CmpLibCmd_CSndCdd: server-com-spec{operation=Impl_OnCommand, queue-length=1}, provided-interface=if_CS_ModeOnCommand
    behavior IB_CSndCdd
      5 x operation invoked event:
        OIE_pp_CS_SndCdd_Services_CSndCdd_CheckChimeStatusTrigByCheckChimeStatus: start-on-event=CSndCdd_CheckChimeStatus, operation=pp_CS_SndCdd_Services.CheckChimeStatus
        OIE_pp_CS_SndCdd_Services_CSndCdd_CheckLastToneStatusTrigByCheckLastToneStatus: start-on-event=CSndCdd_CheckLastToneStatus, operation=pp_CS_SndCdd_Services.CheckLastToneStatus
        OIE_pp_CS_SndCdd_Services_CSndCdd_ClearChimeResumeInfoBufferTrigByClearChimeResumeInfoBuffer: start-on-event=CSndCdd_ClearChimeResumeInfoBuffer, operation=pp_CS_SndCdd_Services.ClearChimeResumeInfoBuffer
        OIE_pp_CS_SndCdd_Services_CSndCdd_GetChimeResumeInfoBufferTrigByGetChimeResumeInfoBuffer: start-on-event=CSndCdd_GetChimeResumeInfoBuffer, operation=pp_CS_SndCdd_Services.GetChimeResumeInfoBuffer
        OIE_pp_CS_SndCdd_AmpDiag_CSndCdd_GetSpeaker_statusTrigByGetSpeaker_status: start-on-event=CSndCdd_GetSpeaker_status, operation=pp_CS_SndCdd_AmpDiag.GetSpeaker_status
      timing event TECSndCdd_Impl_MainFunction: start-on-event=CSndCdd_Impl_MainFunction, period=0.02
      9 x operation invoked event:
        OIE_pp_CmpLibCmd_CSndCdd_CSndCdd_Impl_OnCommandTrigByImpl_OnCommand: start-on-event=CSndCdd_Impl_OnCommand, operation=pp_CmpLibCmd_CSndCdd.Impl_OnCommand
        OIE_pp_CS_SndCdd_Services_CSndCdd_RequestCustomChimeTrigByRequestCustomChime: start-on-event=CSndCdd_RequestCustomChime, operation=pp_CS_SndCdd_Services.RequestCustomChime
        OIE_pp_CS_SndCdd_Services_CSndCdd_RequestToClear_SafetyChimeErrorStatusTrigByRequestToClear_SafetyChimeErrorStatus: start-on-event=CSndCdd_RequestToClear_SafetyChimeErrorStatus, operation=pp_CS_SndCdd_Services.RequestToClear_SafetyChimeErrorStatus
        OIE_pp_CS_SndCdd_Services_CSndCdd_RequestToStartTrigByRequestToStart: start-on-event=CSndCdd_RequestToStart, operation=pp_CS_SndCdd_Services.RequestToStart
        OIE_pp_CS_SndCdd_Services_CSndCdd_RequestToStopTrigByRequestToStop: start-on-event=CSndCdd_RequestToStop, operation=pp_CS_SndCdd_Services.RequestToStop
        OIE_pp_CS_SndCdd_Services_CSndCdd_SetChimeResumeInfoBufferTrigBySetChimeResumeInfoBuffer: start-on-event=CSndCdd_SetChimeResumeInfoBuffer, operation=pp_CS_SndCdd_Services.SetChimeResumeInfoBuffer
        OIE_pp_CS_SndCdd_Services_CSndCdd_SetDynamicDeadTimeTrigBySetDynamicDeadTime: start-on-event=CSndCdd_SetDynamicDeadTime, operation=pp_CS_SndCdd_Services.SetDynamicDeadTime
        OIE_pp_CS_SndCdd_Services_CSndCdd_SetUserPersonalizationVolumeTrigBySetUserPersonalizationVolume: start-on-event=CSndCdd_SetUserPersonalizationVolume, operation=pp_CS_SndCdd_Services.SetUserPersonalizationVolume
        OIE_pp_CS_SndCdd_AmpDiag_CSndCdd_SpkrAmp_RecoveryTrigBySpkrAmp_Recovery: start-on-event=CSndCdd_SpkrAmp_Recovery, operation=pp_CS_SndCdd_AmpDiag.SpkrAmp_Recovery
      timing event TECSndCdd_SpkrDiag_MainFunction: start-on-event=CSndCdd_SpkrDiag_MainFunction, period=0.1
      operation invoked event OIE_pp_CS_SndCdd_Services_CSndCdd_StopCustomChimeTrigByStopCustomChime: start-on-event=CSndCdd_StopCustomChime, operation=pp_CS_SndCdd_Services.StopCustomChime
      timing event TECSndCdd_ToneProcess: start-on-event=CSndCdd_ToneProcess, period=0.002
      4 x operation invoked event:
        OIE_pp_CS_SndCdd_Services_CSndCdd_UpdateChannelVolumeTrigByUpdateChannelVolume: start-on-event=CSndCdd_UpdateChannelVolume, operation=pp_CS_SndCdd_Services.UpdateChannelVolume
        OIE_pp_CS_SndCdd_Services_CSndCdd_UpdateChimeInfoBufferTrigByUpdateChimeInfoBuffer: start-on-event=CSndCdd_UpdateChimeInfoBuffer, operation=pp_CS_SndCdd_Services.UpdateChimeInfoBuffer
        OIE_pp_CS_SndCdd_Services_CSndCdd_UpdateChimeVolumeTrigByUpdateChimeVolume: start-on-event=CSndCdd_UpdateChimeVolume, operation=pp_CS_SndCdd_Services.UpdateChimeVolume
        OIE_pp_CS_SndCdd_Services_CSndCdd_ischannelavailableTrigByischannelavailable: start-on-event=CSndCdd_ischannelavailable, operation=pp_CS_SndCdd_Services.ischannelavailable
      port-api-options:
        enable-take-address=false, indirect-api=false, port=pp_CS_SndCdd_AmpDiag
        enable-take-address=false, indirect-api=false, port=pp_CS_SndCdd_Services
        enable-take-address=false, indirect-api=false, port=pp_CmpLibCmd_CSndCdd
      22 x runnable, all with can-be-invoked-concurrently=true:
        CSndCdd_CheckChimeStatus
        CSndCdd_CheckLastToneStatus
        CSndCdd_ClearChimeResumeInfoBuffer
        CSndCdd_GetChimeResumeInfoBuffer
        CSndCdd_GetSpeaker_status
        CSndCdd_Impl_MainFunction
        CSndCdd_Impl_OnCommand
        CSndCdd_RequestCustomChime
        CSndCdd_RequestToClear_SafetyChimeErrorStatus
        CSndCdd_RequestToStart
        CSndCdd_RequestToStop
        CSndCdd_SetChimeResumeInfoBuffer
        CSndCdd_SetDynamicDeadTime
        CSndCdd_SetUserPersonalizationVolume
        CSndCdd_SpkrAmp_Recovery
        CSndCdd_SpkrDiag_MainFunction
        CSndCdd_StopCustomChime
        CSndCdd_ToneProcess
        CSndCdd_UpdateChannelVolume
        CSndCdd_UpdateChimeInfoBuffer
        CSndCdd_UpdateChimeVolume
        CSndCdd_ischannelavailable
  swc implementation IMPL_CSndCdd: programming-language=C, behavior=IB_CSndCdd
    code-descriptors:
      code CodeDescriptor
